VERSION "dbc-export 1 2025.20.8"

NS_ :

BS_:

BU_: BMS CC CMP CMPD CP DAS DI DIF DIR EPBL EPBR EVSE FC GTW HCML HCMR HVP ICR PCS PM PMF PMR PTC SCCM SDCR TAS UMC VC VCFRONT VCLEFT VCRIGHT VCSEC

BO_ 1012 LS_lightShow: 8 GTW
 SG_ LS_lightShowIndex M : 0|5@1+ (1,0) [0|31] "" Vector__XXX
 SG_ LS_lightLeftRampedChannel1Reques m0 : 5|1@1+ (1,0) [0|1] "" Vector__XXX
 SG_ LS_lightLeftRampedChannel1Durati m0 : 6|2@1+ (1,0) [0|3] "" Vector__XXX
 SG_ LS_lightLeftRampedChannel2Reques m0 : 8|1@1+ (1,0) [0|1] "" Vector__XXX
 SG_ LS_lightLeftRampedChannel2Durati m0 : 9|2@1+ (1,0) [0|3] "" Vector__XXX
 SG_ LS_lightLeftRampedChannel3Reques m0 : 11|1@1+ (1,0) [0|1] "" Vector__XXX
 SG_ LS_lightLeftRampedChannel3Durati m0 : 12|2@1+ (1,0) [0|3] "" Vector__XXX
 SG_ LS_lightLeftRampedChannel4Reques m0 : 14|1@1+ (1,0) [0|1] "" Vector__XXX
 SG_ LS_lightLeftRampedChannel4Durati m0 : 16|2@1+ (1,0) [0|3] "" Vector__XXX
 SG_ LS_lightLeftRampedChannel5Reques m0 : 18|1@1+ (1,0) [0|1] "" Vector__XXX
 SG_ LS_lightLeftRampedChannel5Durati m0 : 19|2@1+ (1,0) [0|3] "" Vector__XXX
 SG_ LS_lightLeftRampedChannel6Reques m0 : 21|1@1+ (1,0) [0|1] "" Vector__XXX
 SG_ LS_lightLeftRampedChannel6Durati m0 : 22|2@1+ (1,0) [0|3] "" Vector__XXX
 SG_ LS_lightLeftRampedChannel7Reques m0 : 24|1@1+ (1,0) [0|1] "" Vector__XXX
 SG_ LS_lightLeftRampedChannel7Durati m0 : 25|2@1+ (1,0) [0|3] "" Vector__XXX
 SG_ LS_lightRightRampedChannel1Reque m0 : 27|1@1+ (1,0) [0|1] "" Vector__XXX
 SG_ LS_lightRightRampedChannel1Durat m0 : 28|2@1+ (1,0) [0|3] "" Vector__XXX
 SG_ LS_lightRightRampedChannel2Reque m0 : 30|1@1+ (1,0) [0|1] "" Vector__XXX
 SG_ LS_lightRightRampedChannel2Durat m0 : 31|2@1+ (1,0) [0|3] "" Vector__XXX
 SG_ LS_lightRightRampedChannel3Reque m0 : 33|1@1+ (1,0) [0|1] "" Vector__XXX
 SG_ LS_lightRightRampedChannel3Durat m0 : 34|2@1+ (1,0) [0|3] "" Vector__XXX
 SG_ LS_lightRightRampedChannel4Reque m0 : 36|1@1+ (1,0) [0|1] "" Vector__XXX
 SG_ LS_lightRightRampedChannel4Durat m0 : 37|2@1+ (1,0) [0|3] "" Vector__XXX
 SG_ LS_lightRightRampedChannel5Reque m0 : 39|1@1+ (1,0) [0|1] "" Vector__XXX
 SG_ LS_lightRightRampedChannel5Durat m0 : 40|2@1+ (1,0) [0|3] "" Vector__XXX
 SG_ LS_lightRightRampedChannel6Reque m0 : 42|1@1+ (1,0) [0|1] "" Vector__XXX
 SG_ LS_lightRightRampedChannel6Durat m0 : 43|2@1+ (1,0) [0|3] "" Vector__XXX
 SG_ LS_lightRightRampedChannel7Reque m0 : 45|1@1+ (1,0) [0|1] "" Vector__XXX
 SG_ LS_lightRightRampedChannel7Durat m0 : 46|2@1+ (1,0) [0|3] "" Vector__XXX
 SG_ LS_lightRearTurnLeftRequest m0 : 48|1@1+ (1,0) [0|1] "" Vector__XXX
 SG_ LS_lightRearTurnRightRequest m0 : 49|1@1+ (1,0) [0|1] "" Vector__XXX
 SG_ LS_lightSideRepeaterLeftRequest m0 : 50|1@1+ (1,0) [0|1] "" Vector__XXX
 SG_ LS_lightSideRepeaterRightRequest m0 : 51|1@1+ (1,0) [0|1] "" Vector__XXX
 SG_ LS_lightSideMarkerLeftRequest m0 : 52|1@1+ (1,0) [0|1] "" Vector__XXX
 SG_ LS_lightSideMarkerRightRequest m0 : 53|1@1+ (1,0) [0|1] "" Vector__XXX
 SG_ LS_lightFrontFogLeftRequest m0 : 54|1@1+ (1,0) [0|1] "" Vector__XXX
 SG_ LS_lightFrontFogRightRequest m0 : 55|1@1+ (1,0) [0|1] "" Vector__XXX
 SG_ LS_lightRearFogRequest m0 : 56|1@1+ (1,0) [0|1] "" Vector__XXX
 SG_ LS_lightBrakeRequest m0 : 57|1@1+ (1,0) [0|1] "" Vector__XXX
 SG_ LS_lightTailLeftRequest m0 : 58|1@1+ (1,0) [0|1] "" Vector__XXX
 SG_ LS_lightTailRightRequest m0 : 59|1@1+ (1,0) [0|1] "" Vector__XXX
 SG_ LS_lightLicensePlateRequest m0 : 60|1@1+ (1,0) [0|1] "" Vector__XXX
 SG_ LS_lightReverseRequest m0 : 61|1@1+ (1,0) [0|1] "" Vector__XXX
 SG_ LS_lightAuxParkLeftRequest m0 : 62|1@1+ (1,0) [0|1] "" Vector__XXX
 SG_ LS_lightAuxParkRightRequest m0 : 63|1@1+ (1,0) [0|1] "" Vector__XXX
 SG_ LS_mirrorRequestLeft m1 : 5|3@1+ (1,0) [0|7] "" Vector__XXX
 SG_ LS_mirrorRequestRight m1 : 8|3@1+ (1,0) [0|7] "" Vector__XXX
 SG_ LS_liftgateRequest m1 : 11|3@1+ (1,0) [0|7] "" Vector__XXX
 SG_ LS_windowRequestLF m1 : 16|3@1+ (1,0) [0|7] "" Vector__XXX
 SG_ LS_windowRequestLR m1 : 19|3@1+ (1,0) [0|7] "" Vector__XXX
 SG_ LS_windowRequestRF m1 : 24|3@1+ (1,0) [0|7] "" Vector__XXX
 SG_ LS_windowRequestRR m1 : 27|3@1+ (1,0) [0|7] "" Vector__XXX
 SG_ LS_presentingHandleRequestLF m1 : 32|3@1+ (1,0) [0|7] "" Vector__XXX
 SG_ LS_presentingHandleRequestLR m1 : 35|3@1+ (1,0) [0|7] "" Vector__XXX
 SG_ LS_presentingHandleRequestRF m1 : 40|3@1+ (1,0) [0|7] "" Vector__XXX
 SG_ LS_presentingHandleRequestRR m1 : 43|3@1+ (1,0) [0|7] "" Vector__XXX
 SG_ LS_powerFrontDoorRequestLeft m1 : 46|3@1+ (1,0) [0|7] "" Vector__XXX
 SG_ LS_powerFrontDoorRequestRight m1 : 49|3@1+ (1,0) [0|7] "" Vector__XXX
 SG_ LS_falconDoorRequestLeft m1 : 52|3@1+ (1,0) [0|7] "" Vector__XXX
 SG_ LS_falconDoorRequestRight m1 : 55|3@1+ (1,0) [0|7] "" Vector__XXX
 SG_ LS_chargePortRequest m1 : 58|2@1+ (1,0) [0|2] "" Vector__XXX
 SG_ LS_chargePortRaveRequest m1 : 60|1@1+ (1,0) [0|1] "" Vector__XXX
 SG_ LS_suspensionRequest m1 : 61|2@1+ (1,0) [0|2] "" Vector__XXX
 SG_ LS_rgbIPFLRed m2 : 8|8@1+ (1,0) [0|255] "" Vector__XXX
 SG_ LS_rgbIPFLGreen m2 : 16|8@1+ (1,0) [0|255] "" Vector__XXX
 SG_ LS_rgbIPFLBlue m2 : 24|8@1+ (1,0) [0|255] "" Vector__XXX
 SG_ LS_rgbIPFRRed m2 : 32|8@1+ (1,0) [0|255] "" Vector__XXX
 SG_ LS_rgbIPFRGreen m2 : 40|8@1+ (1,0) [0|255] "" Vector__XXX
 SG_ LS_rgbIPFRBlue m2 : 48|8@1+ (1,0) [0|255] "" Vector__XXX
 SG_ LS_rgbDoorFLForeRed m3 : 8|8@1+ (1,0) [0|255] "" Vector__XXX
 SG_ LS_rgbDoorFLForeGreen m3 : 16|8@1+ (1,0) [0|255] "" Vector__XXX
 SG_ LS_rgbDoorFLForeBlue m3 : 24|8@1+ (1,0) [0|255] "" Vector__XXX
 SG_ LS_rgbDoorFLAftRed m3 : 32|8@1+ (1,0) [0|255] "" Vector__XXX
 SG_ LS_rgbDoorFLAftGreen m3 : 40|8@1+ (1,0) [0|255] "" Vector__XXX
 SG_ LS_rgbDoorFLAftBlue m3 : 48|8@1+ (1,0) [0|255] "" Vector__XXX
 SG_ LS_rgbDoorFRForeRed m4 : 8|8@1+ (1,0) [0|255] "" Vector__XXX
 SG_ LS_rgbDoorFRForeGreen m4 : 16|8@1+ (1,0) [0|255] "" Vector__XXX
 SG_ LS_rgbDoorFRForeBlue m4 : 24|8@1+ (1,0) [0|255] "" Vector__XXX
 SG_ LS_rgbDoorFRAftRed m4 : 32|8@1+ (1,0) [0|255] "" Vector__XXX
 SG_ LS_rgbDoorFRAftGreen m4 : 40|8@1+ (1,0) [0|255] "" Vector__XXX
 SG_ LS_rgbDoorFRAftBlue m4 : 48|8@1+ (1,0) [0|255] "" Vector__XXX
 SG_ LS_rgbDoorRLForeRed m5 : 8|8@1+ (1,0) [0|255] "" Vector__XXX
 SG_ LS_rgbDoorRLForeGreen m5 : 16|8@1+ (1,0) [0|255] "" Vector__XXX
 SG_ LS_rgbDoorRLForeBlue m5 : 24|8@1+ (1,0) [0|255] "" Vector__XXX
 SG_ LS_rgbDoorRLAftRed m5 : 32|8@1+ (1,0) [0|255] "" Vector__XXX
 SG_ LS_rgbDoorRLAftGreen m5 : 40|8@1+ (1,0) [0|255] "" Vector__XXX
 SG_ LS_rgbDoorRLAftBlue m5 : 48|8@1+ (1,0) [0|255] "" Vector__XXX
 SG_ LS_rgbDoorRRForeRed m6 : 8|8@1+ (1,0) [0|255] "" Vector__XXX
 SG_ LS_rgbDoorRRForeGreen m6 : 16|8@1+ (1,0) [0|255] "" Vector__XXX
 SG_ LS_rgbDoorRRForeBlue m6 : 24|8@1+ (1,0) [0|255] "" Vector__XXX
 SG_ LS_rgbDoorRRAftRed m6 : 32|8@1+ (1,0) [0|255] "" Vector__XXX
 SG_ LS_rgbDoorRRAftGreen m6 : 40|8@1+ (1,0) [0|255] "" Vector__XXX
 SG_ LS_rgbDoorRRAftBlue m6 : 48|8@1+ (1,0) [0|255] "" Vector__XXX
 SG_ LS_frontMatrix0 m7 : 8|8@1+ (1,0) [0|255] "" Vector__XXX
 SG_ LS_frontMatrix1 m7 : 16|8@1+ (1,0) [0|255] "" Vector__XXX
 SG_ LS_frontMatrix2 m7 : 24|8@1+ (1,0) [0|255] "" Vector__XXX
 SG_ LS_frontMatrix3 m7 : 32|8@1+ (1,0) [0|255] "" Vector__XXX
 SG_ LS_frontMatrix4 m7 : 40|8@1+ (1,0) [0|255] "" Vector__XXX
 SG_ LS_frontMatrix5 m7 : 48|8@1+ (1,0) [0|255] "" Vector__XXX
 SG_ LS_frontMatrix6 m7 : 56|8@1+ (1,0) [0|255] "" Vector__XXX
 SG_ LS_frontMatrix7 m8 : 8|8@1+ (1,0) [0|255] "" Vector__XXX
 SG_ LS_frontMatrix8 m8 : 16|8@1+ (1,0) [0|255] "" Vector__XXX
 SG_ LS_frontMatrix9 m8 : 24|8@1+ (1,0) [0|255] "" Vector__XXX
 SG_ LS_frontMatrix10 m8 : 32|8@1+ (1,0) [0|255] "" Vector__XXX
 SG_ LS_frontMatrix11 m8 : 40|8@1+ (1,0) [0|255] "" Vector__XXX
 SG_ LS_frontMatrix12 m8 : 48|8@1+ (1,0) [0|255] "" Vector__XXX
 SG_ LS_frontMatrix13 m8 : 56|8@1+ (1,0) [0|255] "" Vector__XXX
 SG_ LS_frontMatrix14 m9 : 8|8@1+ (1,0) [0|255] "" Vector__XXX
 SG_ LS_frontMatrix15 m9 : 16|8@1+ (1,0) [0|255] "" Vector__XXX
 SG_ LS_frontMatrix16 m9 : 24|8@1+ (1,0) [0|255] "" Vector__XXX
 SG_ LS_frontMatrix17 m9 : 32|8@1+ (1,0) [0|255] "" Vector__XXX
 SG_ LS_frontMatrix18 m9 : 40|8@1+ (1,0) [0|255] "" Vector__XXX
 SG_ LS_frontMatrix19 m9 : 48|8@1+ (1,0) [0|255] "" Vector__XXX
 SG_ LS_frontMatrix20 m9 : 56|8@1+ (1,0) [0|255] "" Vector__XXX
 SG_ LS_frontMatrix21 m10 : 8|8@1+ (1,0) [0|255] "" Vector__XXX
 SG_ LS_frontMatrix22 m10 : 16|8@1+ (1,0) [0|255] "" Vector__XXX
 SG_ LS_frontMatrix23 m10 : 24|8@1+ (1,0) [0|255] "" Vector__XXX
 SG_ LS_frontMatrix24 m10 : 32|8@1+ (1,0) [0|255] "" Vector__XXX
 SG_ LS_frontMatrix25 m10 : 40|8@1+ (1,0) [0|255] "" Vector__XXX
 SG_ LS_frontMatrix26 m10 : 48|8@1+ (1,0) [0|255] "" Vector__XXX
 SG_ LS_frontMatrix27 m10 : 56|8@1+ (1,0) [0|255] "" Vector__XXX
 SG_ LS_frontMatrix28 m11 : 8|8@1+ (1,0) [0|255] "" Vector__XXX
 SG_ LS_frontMatrix29 m11 : 16|8@1+ (1,0) [0|255] "" Vector__XXX
 SG_ LS_frontMatrix30 m11 : 24|8@1+ (1,0) [0|255] "" Vector__XXX
 SG_ LS_frontMatrix31 m11 : 32|8@1+ (1,0) [0|255] "" Vector__XXX
 SG_ LS_frontMatrix32 m11 : 40|8@1+ (1,0) [0|255] "" Vector__XXX
 SG_ LS_frontMatrix33 m11 : 48|8@1+ (1,0) [0|255] "" Vector__XXX
 SG_ LS_frontMatrix34 m11 : 56|8@1+ (1,0) [0|255] "" Vector__XXX
 SG_ LS_frontMatrix35 m12 : 8|8@1+ (1,0) [0|255] "" Vector__XXX
 SG_ LS_frontMatrix36 m12 : 16|8@1+ (1,0) [0|255] "" Vector__XXX
 SG_ LS_frontMatrix37 m12 : 24|8@1+ (1,0) [0|255] "" Vector__XXX
 SG_ LS_frontMatrix38 m12 : 32|8@1+ (1,0) [0|255] "" Vector__XXX
 SG_ LS_frontMatrix39 m12 : 40|8@1+ (1,0) [0|255] "" Vector__XXX
 SG_ LS_frontMatrix40 m12 : 48|8@1+ (1,0) [0|255] "" Vector__XXX
 SG_ LS_frontMatrix41 m12 : 56|8@1+ (1,0) [0|255] "" Vector__XXX
 SG_ LS_frontMatrix42 m13 : 8|8@1+ (1,0) [0|255] "" Vector__XXX
 SG_ LS_frontMatrix43 m13 : 16|8@1+ (1,0) [0|255] "" Vector__XXX
 SG_ LS_frontMatrix44 m13 : 24|8@1+ (1,0) [0|255] "" Vector__XXX
 SG_ LS_frontMatrix45 m13 : 32|8@1+ (1,0) [0|255] "" Vector__XXX
 SG_ LS_frontMatrix46 m13 : 40|8@1+ (1,0) [0|255] "" Vector__XXX
 SG_ LS_frontMatrix47 m13 : 48|8@1+ (1,0) [0|255] "" Vector__XXX
 SG_ LS_frontMatrix48 m13 : 56|8@1+ (1,0) [0|255] "" Vector__XXX
 SG_ LS_frontMatrix49 m14 : 8|8@1+ (1,0) [0|255] "" Vector__XXX
 SG_ LS_frontMatrix50 m14 : 16|8@1+ (1,0) [0|255] "" Vector__XXX
 SG_ LS_frontMatrix51 m14 : 24|8@1+ (1,0) [0|255] "" Vector__XXX
 SG_ LS_frontMatrix52 m14 : 32|8@1+ (1,0) [0|255] "" Vector__XXX
 SG_ LS_frontMatrix53 m14 : 40|8@1+ (1,0) [0|255] "" Vector__XXX
 SG_ LS_frontMatrix54 m14 : 48|8@1+ (1,0) [0|255] "" Vector__XXX
 SG_ LS_frontMatrix55 m14 : 56|8@1+ (1,0) [0|255] "" Vector__XXX
 SG_ LS_frontMatrix56 m15 : 8|8@1+ (1,0) [0|255] "" Vector__XXX
 SG_ LS_frontMatrix57 m15 : 16|8@1+ (1,0) [0|255] "" Vector__XXX
 SG_ LS_frontMatrix58 m15 : 24|8@1+ (1,0) [0|255] "" Vector__XXX
 SG_ LS_frontMatrix59 m15 : 32|8@1+ (1,0) [0|255] "" Vector__XXX
 SG_ LS_rearMatrix0 m15 : 40|8@1+ (1,0) [0|255] "" Vector__XXX
 SG_ LS_rearMatrix1 m15 : 48|8@1+ (1,0) [0|255] "" Vector__XXX
 SG_ LS_rearMatrix2 m15 : 56|8@1+ (1,0) [0|255] "" Vector__XXX
 SG_ LS_rearMatrix3 m16 : 8|8@1+ (1,0) [0|255] "" Vector__XXX
 SG_ LS_rearMatrix4 m16 : 16|8@1+ (1,0) [0|255] "" Vector__XXX
 SG_ LS_rearMatrix5 m16 : 24|8@1+ (1,0) [0|255] "" Vector__XXX
 SG_ LS_rearMatrix6 m16 : 32|8@1+ (1,0) [0|255] "" Vector__XXX
 SG_ LS_rearMatrix7 m16 : 40|8@1+ (1,0) [0|255] "" Vector__XXX
 SG_ LS_rearMatrix8 m16 : 48|8@1+ (1,0) [0|255] "" Vector__XXX
 SG_ LS_rearMatrix9 m16 : 56|8@1+ (1,0) [0|255] "" Vector__XXX
 SG_ LS_rearMatrix10 m17 : 8|8@1+ (1,0) [0|255] "" Vector__XXX
 SG_ LS_rearMatrix11 m17 : 16|8@1+ (1,0) [0|255] "" Vector__XXX
 SG_ LS_rearMatrix12 m17 : 24|8@1+ (1,0) [0|255] "" Vector__XXX
 SG_ LS_rearMatrix13 m17 : 32|8@1+ (1,0) [0|255] "" Vector__XXX
 SG_ LS_rearMatrix14 m17 : 40|8@1+ (1,0) [0|255] "" Vector__XXX
 SG_ LS_rearMatrix15 m17 : 48|8@1+ (1,0) [0|255] "" Vector__XXX
 SG_ LS_rearMatrix16 m17 : 56|8@1+ (1,0) [0|255] "" Vector__XXX
 SG_ LS_rearMatrix17 m18 : 8|8@1+ (1,0) [0|255] "" Vector__XXX
 SG_ LS_rearMatrix18 m18 : 16|8@1+ (1,0) [0|255] "" Vector__XXX
 SG_ LS_rearMatrix19 m18 : 24|8@1+ (1,0) [0|255] "" Vector__XXX
 SG_ LS_rearMatrix20 m18 : 32|8@1+ (1,0) [0|255] "" Vector__XXX
 SG_ LS_rearMatrix21 m18 : 40|8@1+ (1,0) [0|255] "" Vector__XXX
 SG_ LS_rearMatrix22 m18 : 48|8@1+ (1,0) [0|255] "" Vector__XXX
 SG_ LS_rearMatrix23 m18 : 56|8@1+ (1,0) [0|255] "" Vector__XXX
 SG_ LS_rearMatrix24 m19 : 8|8@1+ (1,0) [0|255] "" Vector__XXX
 SG_ LS_rearMatrix25 m19 : 16|8@1+ (1,0) [0|255] "" Vector__XXX
 SG_ LS_rearMatrix26 m19 : 24|8@1+ (1,0) [0|255] "" Vector__XXX
 SG_ LS_rearMatrix27 m19 : 32|8@1+ (1,0) [0|255] "" Vector__XXX
 SG_ LS_rearMatrix28 m19 : 40|8@1+ (1,0) [0|255] "" Vector__XXX
 SG_ LS_rearMatrix29 m19 : 48|8@1+ (1,0) [0|255] "" Vector__XXX
 SG_ LS_rearMatrix30 m19 : 56|8@1+ (1,0) [0|255] "" Vector__XXX
 SG_ LS_rearMatrix31 m20 : 8|8@1+ (1,0) [0|255] "" Vector__XXX
 SG_ LS_rearMatrix32 m20 : 16|8@1+ (1,0) [0|255] "" Vector__XXX
 SG_ LS_rearMatrix33 m20 : 24|8@1+ (1,0) [0|255] "" Vector__XXX
 SG_ LS_rearMatrix34 m20 : 32|8@1+ (1,0) [0|255] "" Vector__XXX
 SG_ LS_rearMatrix35 m20 : 40|8@1+ (1,0) [0|255] "" Vector__XXX
 SG_ LS_rearMatrix36 m20 : 48|8@1+ (1,0) [0|255] "" Vector__XXX
 SG_ LS_rearMatrix37 m20 : 56|8@1+ (1,0) [0|255] "" Vector__XXX
 SG_ LS_rearMatrix38 m21 : 8|8@1+ (1,0) [0|255] "" Vector__XXX
 SG_ LS_rearMatrix39 m21 : 16|8@1+ (1,0) [0|255] "" Vector__XXX
 SG_ LS_rearMatrix40 m21 : 24|8@1+ (1,0) [0|255] "" Vector__XXX
 SG_ LS_rearMatrix41 m21 : 32|8@1+ (1,0) [0|255] "" Vector__XXX
 SG_ LS_rearMatrix42 m21 : 40|8@1+ (1,0) [0|255] "" Vector__XXX
 SG_ LS_rearMatrix43 m21 : 48|8@1+ (1,0) [0|255] "" Vector__XXX
 SG_ LS_rearMatrix44 m21 : 56|8@1+ (1,0) [0|255] "" Vector__XXX
 SG_ LS_rearMatrix45 m22 : 8|8@1+ (1,0) [0|255] "" Vector__XXX
 SG_ LS_rearMatrix46 m22 : 16|8@1+ (1,0) [0|255] "" Vector__XXX
 SG_ LS_rearMatrix47 m22 : 24|8@1+ (1,0) [0|255] "" Vector__XXX
 SG_ LS_rearMatrix48 m22 : 32|8@1+ (1,0) [0|255] "" Vector__XXX
 SG_ LS_rearMatrix49 m22 : 40|8@1+ (1,0) [0|255] "" Vector__XXX
 SG_ LS_rearMatrix50 m22 : 48|8@1+ (1,0) [0|255] "" Vector__XXX
 SG_ LS_rearMatrix51 m22 : 56|8@1+ (1,0) [0|255] "" Vector__XXX
 SG_ LS_rearMatrix52 m23 : 8|8@1+ (1,0) [0|255] "" Vector__XXX
 SG_ LS_rearMatrix53 m23 : 16|8@1+ (1,0) [0|255] "" Vector__XXX
 SG_ LS_rearMatrix54 m23 : 24|8@1+ (1,0) [0|255] "" Vector__XXX
 SG_ LS_rearMatrix55 m23 : 32|8@1+ (1,0) [0|255] "" Vector__XXX
 SG_ LS_rearMatrix56 m23 : 40|8@1+ (1,0) [0|255] "" Vector__XXX
 SG_ LS_rearMatrix57 m23 : 48|8@1+ (1,0) [0|255] "" Vector__XXX
 SG_ LS_rearMatrix58 m23 : 56|8@1+ (1,0) [0|255] "" Vector__XXX
 SG_ LS_rearMatrix59 m24 : 8|8@1+ (1,0) [0|255] "" Vector__XXX
 SG_ LS_offroadLightBar0 m24 : 16|8@1+ (1,0) [0|255] "" Vector__XXX
 SG_ LS_offroadLightBar1 m24 : 24|8@1+ (1,0) [0|255] "" Vector__XXX
 SG_ LS_offroadLightBar2 m24 : 32|8@1+ (1,0) [0|255] "" Vector__XXX
 SG_ LS_offroadLightBar3 m24 : 40|8@1+ (1,0) [0|255] "" Vector__XXX
 SG_ LS_offroadLightBar4 m24 : 48|8@1+ (1,0) [0|255] "" Vector__XXX
 SG_ LS_offroadLightBar5 m24 : 56|8@1+ (1,0) [0|255] "" Vector__XXX

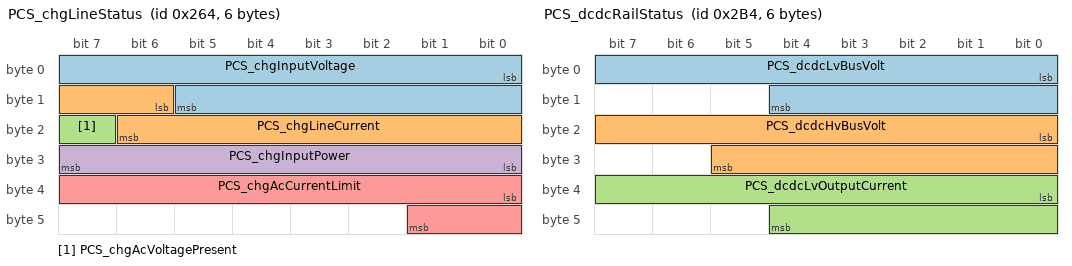
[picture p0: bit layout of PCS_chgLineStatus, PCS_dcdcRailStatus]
BO_ 612 PCS_chgLineStatus: 6 PCS
 SG_ PCS_chgInputVoltage : 0|14@1+ (0.033,0) [0|540.639] "V" Vector__XXX
 SG_ PCS_chgLineCurrent : 14|9@1+ (0.1,0) [0|50] "A" Vector__XXX
 SG_ PCS_chgAcVoltagePresent : 23|1@1+ (1,0) [0|1] "" Vector__XXX
 SG_ PCS_chgInputPower : 24|8@1+ (0.1,0) [0|20] "kW" Vector__XXX
 SG_ PCS_chgAcCurrentLimit : 32|10@1+ (0.1,0) [0|102.3] "A" Vector__XXX

BO_ 692 PCS_dcdcRailStatus: 6 PCS
 SG_ PCS_dcdcLvBusVolt : 0|13@1+ (0.01,0) [0|80] "V" Vector__XXX
 SG_ PCS_dcdcHvBusVolt : 16|14@1+ (0.1,0) [0|1600] "V" Vector__XXX
 SG_ PCS_dcdcLvOutputCurrent : 32|13@1- (0.1,0) [-400|400] "A" Vector__XXX

BO_ 964 PCS_info: 8 PCS
 SG_ PCS_infoIndex M : 0|8@1+ (1,0) [0|255] "" Vector__XXX
 SG_ PCS_buildType m10 : 8|8@1+ (1,0) [0|255] "" Vector__XXX
 SG_ PCS_buildConfigId m10 : 16|16@1+ (1,0) [0|65535] "" Vector__XXX
 SG_ PCS_hardwareId m10 : 32|16@1+ (1,0) [0|65535] "" Vector__XXX
 SG_ PCS_componentId m10 : 48|16@1+ (1,0) [0|65535] "" Vector__XXX
 SG_ PCS_pcbaId m11 : 16|8@1+ (1,0) [0|255] "" Vector__XXX
 SG_ PCS_assemblyId m11 : 24|8@1+ (1,0) [0|255] "" Vector__XXX
 SG_ PCS_usageId m11 : 32|16@1+ (1,0) [0|65535] "" Vector__XXX
 SG_ PCS_subUsageId m11 : 48|16@1+ (1,0) [0|65535] "" Vector__XXX
 SG_ PCS_platformType m13 : 8|8@1+ (1,0) [0|255] "" Vector__XXX
 SG_ PCS_appCrc m13 : 32|32@1+ (1,0) [0|4294967295] "" Vector__XXX
 SG_ PCS_cpu2AppCrc m16 : 32|32@1+ (1,0) [0|4294967295] "" Vector__XXX
 SG_ PCS_appGitHash m17 : 8|56@1+ (1,0) [0|7.20575940379e+16] "" Vector__XXX
 SG_ PCS_bootGitHash m18 : 8|56@1+ (1,0) [0|7.20575940379e+16] "" Vector__XXX
 SG_ PCS_bootUdsProtoVersion m20 : 8|8@1+ (1,0) [0|255] "" Vector__XXX
 SG_ PCS_bootCrc m20 : 32|32@1+ (1,0) [0|4294967295] "" Vector__XXX

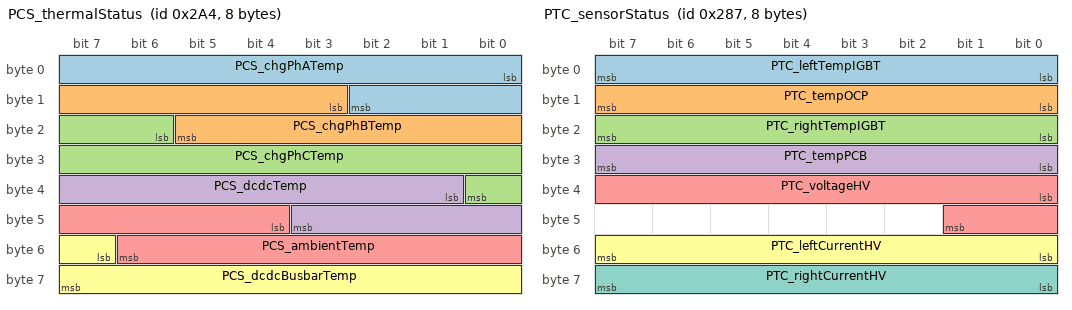
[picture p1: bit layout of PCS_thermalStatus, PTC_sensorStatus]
BO_ 676 PCS_thermalStatus: 8 PCS
 SG_ PCS_chgPhATemp : 0|11@1- (0.1,40) [-62.4|142.3] "C" Vector__XXX
 SG_ PCS_chgPhBTemp : 11|11@1- (0.1,40) [-62.4|142.3] "C" Vector__XXX
 SG_ PCS_chgPhCTemp : 22|11@1- (0.1,40) [-62.4|142.3] "C" Vector__XXX
 SG_ PCS_dcdcTemp : 33|11@1- (0.1,40) [-62.4|142.3] "C" Vector__XXX
 SG_ PCS_ambientTemp : 44|11@1- (0.1,40) [-62.4|142.3] "C" Vector__XXX
 SG_ PCS_dcdcBusbarTemp : 55|9@1+ (0.2935421,0) [0|149.706471] "C" Vector__XXX

BO_ 790 PMF_info: 8 PMF
 SG_ PMF_infoIndex M : 0|8@1+ (1,0) [0|255] "" Vector__XXX
 SG_ PMF_buildType m10 : 8|8@1+ (1,0) [0|255] "" Vector__XXX
 SG_ PMF_buildConfigurationId m10 : 16|16@1+ (1,0) [0|65535] "" Vector__XXX
 SG_ PMF_hardwareId m10 : 32|8@1+ (1,0) [0|252] "" Vector__XXX
 SG_ PMF_deviceFused m10 : 40|1@1+ (1,0) [0|1] "" Vector__XXX
 SG_ PMF_componentId m10 : 48|16@1+ (1,0) [0|65535] "" Vector__XXX
 SG_ PMF_pcbaId m11 : 16|8@1+ (1,0) [0|255] "" Vector__XXX
 SG_ PMF_assemblyId m11 : 24|8@1+ (1,0) [0|255] "" Vector__XXX
 SG_ PMF_usageId m11 : 32|16@1+ (1,0) [0|65535] "" Vector__XXX
 SG_ PMF_subUsageId m11 : 48|16@1+ (1,0) [0|65535] "" Vector__XXX
 SG_ PMF_applicationCrc m13 : 32|32@1+ (1,0) [0|4294967295] "" Vector__XXX
 SG_ PMF_appGitHash m17 : 8|56@1+ (1,0) [0|7.20575940379e+16] "" Vector__XXX
 SG_ PMF_bootGitHash m18 : 8|56@1+ (1,0) [0|7.20575940379e+16] "" Vector__XXX
 SG_ PMF_platformTyp m19 : 8|8@1+ (1,0) [0|255] "" Vector__XXX
 SG_ PMF_udsProtocolVersion m20 : 8|8@1+ (1,0) [0|255] "" Vector__XXX
 SG_ PMF_bootloaderCrc m20 : 32|32@1+ (1,0) [0|4294967295] "" Vector__XXX

BO_ 1748 PMR_info: 8 PMR
 SG_ PMR_infoIndex M : 0|8@1+ (1,0) [0|255] "" Vector__XXX
 SG_ PMR_buildType m10 : 8|8@1+ (1,0) [0|255] "" Vector__XXX
 SG_ PMR_buildConfigurationId m10 : 16|16@1+ (1,0) [0|65535] "" Vector__XXX
 SG_ PMR_hardwareId m10 : 32|8@1+ (1,0) [0|252] "" Vector__XXX
 SG_ PMR_deviceFused m10 : 40|1@1+ (1,0) [0|1] "" Vector__XXX
 SG_ PMR_componentId m10 : 48|16@1+ (1,0) [0|65535] "" Vector__XXX
 SG_ PMR_pcbaId m11 : 16|8@1+ (1,0) [0|255] "" Vector__XXX
 SG_ PMR_assemblyId m11 : 24|8@1+ (1,0) [0|255] "" Vector__XXX
 SG_ PMR_usageId m11 : 32|16@1+ (1,0) [0|65535] "" Vector__XXX
 SG_ PMR_subUsageId m11 : 48|16@1+ (1,0) [0|65535] "" Vector__XXX
 SG_ PMR_applicationCrc m13 : 32|32@1+ (1,0) [0|4294967295] "" Vector__XXX
 SG_ PMR_appGitHash m17 : 8|56@1+ (1,0) [0|7.20575940379e+16] "" Vector__XXX
 SG_ PMR_bootGitHash m18 : 8|56@1+ (1,0) [0|7.20575940379e+16] "" Vector__XXX
 SG_ PMR_platformTyp m19 : 8|8@1+ (1,0) [0|255] "" Vector__XXX
 SG_ PMR_udsProtocolVersion m20 : 8|8@1+ (1,0) [0|255] "" Vector__XXX
 SG_ PMR_bootloaderCrc m20 : 32|32@1+ (1,0) [0|4294967295] "" Vector__XXX

BO_ 1551 PM_info: 8 PM
 SG_ PM_infoIndex M : 0|8@1+ (1,0) [0|255] "" Vector__XXX
 SG_ PM_buildType m10 : 8|8@1+ (1,0) [0|255] "" Vector__XXX
 SG_ PM_buildConfigurationId m10 : 16|16@1+ (1,0) [0|65535] "" Vector__XXX
 SG_ PM_hardwareId m10 : 32|8@1+ (1,0) [0|252] "" Vector__XXX
 SG_ PM_deviceFused m10 : 40|1@1+ (1,0) [0|1] "" Vector__XXX
 SG_ PM_componentId m10 : 48|16@1+ (1,0) [0|65535] "" Vector__XXX
 SG_ PM_pcbaId m11 : 16|8@1+ (1,0) [0|255] "" Vector__XXX
 SG_ PM_assemblyId m11 : 24|8@1+ (1,0) [0|255] "" Vector__XXX
 SG_ PM_usageId m11 : 32|16@1+ (1,0) [0|65535] "" Vector__XXX
 SG_ PM_subUsageId m11 : 48|16@1+ (1,0) [0|65535] "" Vector__XXX
 SG_ PM_applicationCrc m13 : 32|32@1+ (1,0) [0|4294967295] "" Vector__XXX
 SG_ PM_bootGitHash m18 : 8|56@1+ (1,0) [0|7.20575940379e+16] "" Vector__XXX

BO_ 837 PTC_info: 8 PTC
 SG_ PTC_infoIndex M : 0|8@1+ (1,0) [0|255] "" Vector__XXX
 SG_ PTC_infoBuildType m10 : 8|3@1+ (1,0) [0|7] "" Vector__XXX
 SG_ PTC_infoBuildConfigId m10 : 16|16@1+ (1,0) [0|65535] "" Vector__XXX
 SG_ PTC_infoHardwareId m10 : 32|16@1+ (1,0) [0|65535] "" Vector__XXX
 SG_ PTC_infoComponentId m10 : 48|16@1+ (1,0) [0|65535] "" Vector__XXX
 SG_ PTC_infoPcbaId m11 : 16|8@1+ (1,0) [0|255] "" Vector__XXX
 SG_ PTC_infoAssemblyId m11 : 24|8@1+ (1,0) [0|254] "" Vector__XXX
 SG_ PTC_infoUsageId m11 : 32|16@1+ (1,0) [0|65535] "" Vector__XXX
 SG_ PTC_infoSubUsageId m11 : 48|16@1+ (1,0) [0|65535] "" Vector__XXX
 SG_ PTC_infoPlatformType m13 : 8|8@1+ (1,0) [0|255] "" Vector__XXX
 SG_ PTC_infoAppCrc m13 : 32|32@1+ (1,0) [0|4294967295] "" Vector__XXX
 SG_ PTC_infoBootUdsProtoVersion m20 : 8|8@1+ (1,0) [0|255] "" Vector__XXX
 SG_ PTC_infoBootCrc m20 : 32|32@1+ (1,0) [0|4294967295] "" Vector__XXX

BO_ 647 PTC_sensorStatus: 8 PTC
 SG_ PTC_leftTempIGBT : 0|8@1+ (1,-40) [-40|200] "degC" Vector__XXX
 SG_ PTC_tempOCP : 8|8@1+ (1,-40) [-40|200] "degC" Vector__XXX
 SG_ PTC_rightTempIGBT : 16|8@1+ (1,-40) [-40|200] "degC" Vector__XXX
 SG_ PTC_tempPCB : 24|8@1+ (1,-40) [-40|200] "degC" Vector__XXX
 SG_ PTC_voltageHV : 32|10@1+ (0.5,0) [0|511.5] "V" Vector__XXX
 SG_ PTC_leftCurrentHV : 48|8@1+ (0.2,0) [0|50] "A" Vector__XXX
 SG_ PTC_rightCurrentHV : 56|8@1+ (0.2,0) [0|50] "A" Vector__XXX

BO_ 816 SCCM_info: 8 SCCM
 SG_ SCCM_infoIndex M : 0|8@1+ (1,0) [0|255] "" Vector__XXX
 SG_ SCCM_infoBuildType m10 : 8|8@1+ (1,0) [0|255] "" Vector__XXX
 SG_ SCCM_infoBuildConfigId m10 : 16|16@1+ (1,0) [0|65535] "" Vector__XXX
 SG_ SCCM_infoHardwareId m10 : 32|16@1+ (1,0) [0|65535] "" Vector__XXX
 SG_ SCCM_infoComponentId m10 : 48|16@1+ (1,0) [0|65535] "" Vector__XXX
 SG_ SCCM_infoPcbaId m11 : 16|8@1+ (1,0) [0|255] "" Vector__XXX
 SG_ SCCM_infoAssemblyId m11 : 24|8@1+ (1,0) [0|255] "" Vector__XXX
 SG_ SCCM_infoUsageId m11 : 32|16@1+ (1,0) [0|65535] "" Vector__XXX
 SG_ SCCM_infoSubUsageId m11 : 48|16@1+ (1,0) [0|65535] "" Vector__XXX
 SG_ SCCM_infoPlatformType m13 : 8|8@1+ (1,0) [0|255] "" Vector__XXX
 SG_ SCCM_infoAppCrc m13 : 39|32@0+ (1,0) [0|4294967295] "" Vector__XXX
 SG_ SCCM_infoBootSvnRev m14 : 8|24@1+ (1,0) [0|16777215] "" Vector__XXX
 SG_ SCCM_infoBootSvnUrlHash m14 : 32|32@1+ (1,0) [0|4294967295] "" Vector__XXX
 SG_ SCCM_infoSubcomponent1Version m16 : 16|32@1+ (1,0) [0|4294967295] "" Vector__XXX
 SG_ SCCM_infoAppSvnHash m17 : 8|56@1+ (1,0) [0|7.20575940379e+16] "" Vector__XXX
 SG_ SCCM_infoBootSvnHash m18 : 8|56@1+ (1,0) [0|7.20575940379e+16] "" Vector__XXX
 SG_ SCCM_infoUdsProtoVersion m20 : 8|8@1+ (1,0) [0|255] "" Vector__XXX
 SG_ SCCM_infoBootCrc m20 : 32|32@1+ (1,0) [0|4294967295] "" Vector__XXX

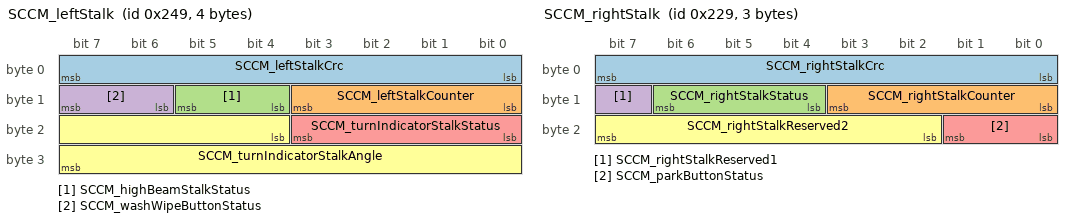
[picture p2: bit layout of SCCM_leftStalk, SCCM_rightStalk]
BO_ 585 SCCM_leftStalk: 4 SCCM
 SG_ SCCM_leftStalkCrc : 0|8@1+ (1,0) [0|255] "" Vector__XXX
 SG_ SCCM_leftStalkCounter : 8|4@1+ (1,0) [0|15] "" Vector__XXX
 SG_ SCCM_highBeamStalkStatus : 12|2@1+ (1,0) [0|2] "" Vector__XXX
 SG_ SCCM_washWipeButtonStatus : 14|2@1+ (1,0) [0|2] "" Vector__XXX
 SG_ SCCM_turnIndicatorStalkStatus : 16|4@1+ (1,0) [0|15] "" Vector__XXX
 SG_ SCCM_turnIndicatorStalkAngle : 20|12@1+ (0.1,-180) [-180|180] "deg" Vector__XXX

BO_ 553 SCCM_rightStalk: 3 SCCM
 SG_ SCCM_rightStalkCrc : 0|8@1+ (1,0) [0|255] "" Vector__XXX
 SG_ SCCM_rightStalkCounter : 8|4@1+ (1,0) [0|15] "" Vector__XXX
 SG_ SCCM_rightStalkStatus : 12|3@1+ (1,0) [0|7] "" Vector__XXX
 SG_ SCCM_rightStalkReserved1 : 15|1@1+ (1,0) [0|1] "" Vector__XXX
 SG_ SCCM_parkButtonStatus : 16|2@1+ (1,0) [0|2] "" Vector__XXX
 SG_ SCCM_rightStalkReserved2 : 18|6@1+ (1,0) [0|63] "" Vector__XXX

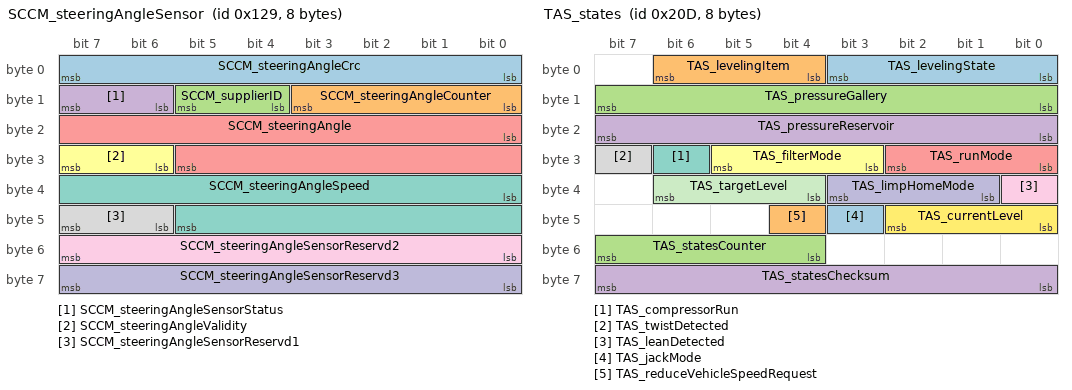
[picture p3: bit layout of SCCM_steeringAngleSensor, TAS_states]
BO_ 297 SCCM_steeringAngleSensor: 8 SCCM
 SG_ SCCM_steeringAngleCrc : 0|8@1+ (1,0) [0|255] "" Vector__XXX
 SG_ SCCM_steeringAngleCounter : 8|4@1+ (1,0) [0|15] "" Vector__XXX
 SG_ SCCM_supplierID : 12|2@1+ (1,0) [0|3] "" Vector__XXX
 SG_ SCCM_steeringAngleSensorStatus : 14|2@1+ (1,0) [0|3] "" Vector__XXX
 SG_ SCCM_steeringAngle : 16|14@1+ (0.1,-819.2) [-819.2|819] "deg" Vector__XXX
 SG_ SCCM_steeringAngleValidity : 30|2@1+ (1,0) [0|2] "" Vector__XXX
 SG_ SCCM_steeringAngleSpeed : 32|14@1+ (0.5,-4096) [-4096|4095.5] "deg/s" Vector__XXX
 SG_ SCCM_steeringAngleSensorReservd1 : 46|2@1+ (1,0) [0|3] "" Vector__XXX
 SG_ SCCM_steeringAngleSensorReservd2 : 48|8@1+ (1,0) [0|255] "" Vector__XXX
 SG_ SCCM_steeringAngleSensorReservd3 : 56|8@1+ (1,0) [0|255] "" Vector__XXX

BO_ 1597 SDCR_info: 8 SDCR
 SG_ SDCR_infoIndex M : 0|8@1+ (1,0) [0|255] "" Vector__XXX
 SG_ SDCR_infoBuildType m10 : 13|3@1+ (1,0) [0|7] "" Vector__XXX
 SG_ SDCR_infoBuildConfigId m10 : 16|16@1+ (1,0) [0|65535] "" Vector__XXX
 SG_ SDCR_infoHardwareId m10 : 32|16@1+ (1,0) [0|65535] "" Vector__XXX
 SG_ SDCR_infoComponentId m10 : 55|16@0+ (1,0) [0|65535] "" Vector__XXX
 SG_ SDCR_infoPcbaId m11 : 8|8@1+ (1,0) [0|255] "" Vector__XXX
 SG_ SDCR_infoAssemblyId m11 : 16|8@1+ (1,0) [0|255] "" Vector__XXX
 SG_ SDCR_infoUsageId m11 : 31|16@0+ (1,0) [0|65535] "" Vector__XXX
 SG_ SDCR_infoSubUsageId m11 : 40|16@1+ (1,0) [0|65535] "" Vector__XXX
 SG_ SDCR_infoAppCrc m13 : 15|32@0+ (1,0) [0|4294967295] "" Vector__XXX
 SG_ SDCR_infoBootGitHash m18 : 8|56@1+ (1,0) [0|7.20575940379e+16] "" Vector__XXX

BO_ 523 TAS_axleData: 8 TAS
 SG_ TAS_axleIndex M : 0|1@1+ (1,0) [0|1] "" Vector__XXX
 SG_ TAS_rawHeightFL m0 : 4|10@1+ (1,-512) [-512|510] "mm" Vector__XXX
 SG_ TAS_staticHeightEstimateFL m0 : 14|10@1+ (1,-512) [-512|510] "mm" Vector__XXX
 SG_ TAS_componentPressureFL m0 : 24|8@1+ (0.1,0) [0|25.4] "bara" Vector__XXX
 SG_ TAS_rawHeightFR m0 : 32|10@1+ (1,-512) [-512|510] "mm" Vector__XXX
 SG_ TAS_staticHeightEstimateFR m0 : 42|10@1+ (1,-512) [-512|510] "mm" Vector__XXX
 SG_ TAS_componentPressureFR m0 : 52|8@1+ (0.1,0) [0|25.4] "bara" Vector__XXX
 SG_ TAS_rawHeightRL m1 : 4|10@1+ (1,-512) [-512|510] "mm" Vector__XXX
 SG_ TAS_staticHeightEstimateRL m1 : 14|10@1+ (1,-512) [-512|510] "mm" Vector__XXX
 SG_ TAS_componentPressureRL m1 : 24|8@1+ (0.1,0) [0|25.4] "bara" Vector__XXX
 SG_ TAS_rawHeightRR m1 : 32|10@1+ (1,-512) [-512|510] "mm" Vector__XXX
 SG_ TAS_staticHeightEstimateRR m1 : 42|10@1+ (1,-512) [-512|510] "mm" Vector__XXX
 SG_ TAS_componentPressureRR m1 : 52|8@1+ (0.1,0) [0|25.4] "bara" Vector__XXX

BO_ 1398 TAS_dampingStates: 8 TAS
 SG_ TAS_endstopState : 0|1@1+ (1,0) [0|1] "" Vector__XXX
 SG_ TAS_continuousControlState : 1|1@1+ (1,0) [0|1] "" Vector__XXX
 SG_ TAS_activeTireTune : 2|1@1+ (1,0) [0|1] "" Vector__XXX
 SG_ TAS_roughnessRaiseReason : 3|2@1+ (1,0) [0|3] "" Vector__XXX
 SG_ TAS_frontMetricDrivesRear : 5|2@1+ (1,0) [0|3] "" Vector__XXX
 SG_ TAS_roadCondition : 8|8@1+ (0.005,0) [0|1.27] "-" Vector__XXX
 SG_ TAS_bellyProtect : 16|2@1+ (1,0) [0|3] "" Vector__XXX
 SG_ TAS_frontMetricDrivesFront : 18|2@1+ (1,0) [0|3] "" Vector__XXX
 SG_ TAS_speedBumpAxleFront : 20|3@1+ (1,0) [0|7] "" Vector__XXX
 SG_ TAS_speedBumpAxleRear : 23|3@1+ (1,0) [0|7] "" Vector__XXX
 SG_ TAS_holeProtectFL : 26|2@1+ (1,0) [0|3] "" Vector__XXX
 SG_ TAS_holeProtectFR : 28|2@1+ (1,0) [0|3] "" Vector__XXX
 SG_ TAS_holeProtectRL : 30|2@1+ (1,0) [0|3] "" Vector__XXX
 SG_ TAS_holeProtectRR : 32|2@1+ (1,0) [0|3] "" Vector__XXX
 SG_ TAS_stepProtectFL : 34|2@1+ (1,0) [0|3] "" Vector__XXX
 SG_ TAS_stepProtectFR : 36|2@1+ (1,0) [0|3] "" Vector__XXX
 SG_ TAS_stepProtectRL : 38|2@1+ (1,0) [0|3] "" Vector__XXX
 SG_ TAS_stepProtectRR : 40|2@1+ (1,0) [0|3] "" Vector__XXX
 SG_ TAS_FDUTorqueCorruptionScale : 42|4@1+ (0.075,0) [0|1.05] "-" Vector__XXX
 SG_ TAS_sprungMassEstimate : 46|5@1+ (64,1800) [1800|3720] "kg" Vector__XXX
 SG_ TAS_anyDamperActive : 51|1@1+ (1,0) [0|1] "" Vector__XXX
 SG_ TAS_dampingStatesCounter : 52|4@1+ (1,0) [0|15] "" Vector__XXX
 SG_ TAS_dampingStatesChecksum : 56|8@1+ (1,0) [0|255] "" Vector__XXX

BO_ 1357 TAS_info: 8 TAS
 SG_ TAS_infoIndex M : 0|8@1+ (1,0) [0|255] "" Vector__XXX
 SG_ TAS_infoBuildType m10 : 8|8@1+ (1,0) [0|255] "" Vector__XXX
 SG_ TAS_infoBuildConfigId m10 : 16|16@1+ (1,0) [0|65535] "" Vector__XXX
 SG_ TAS_infoHardwareId m10 : 32|1@1+ (1,0) [0|1] "" Vector__XXX
 SG_ TAS_infoComponentId m10 : 48|16@1+ (1,0) [0|65535] "" Vector__XXX
 SG_ TAS_infoPcbaId m11 : 16|8@1+ (1,0) [0|255] "" Vector__XXX
 SG_ TAS_infoAssemblyId m11 : 24|8@1+ (1,0) [0|254] "" Vector__XXX
 SG_ TAS_infoUsageId m11 : 32|16@1+ (1,0) [0|65535] "" Vector__XXX
 SG_ TAS_infoSubUsageId m11 : 48|16@1+ (1,0) [0|65535] "" Vector__XXX
 SG_ TAS_infoAppCrc m13 : 32|32@1+ (1,0) [0|4294967295] "" Vector__XXX
 SG_ TAS_infoAppGitHash m17 : 8|56@1+ (1,0) [0|7.20575940379e+16] "" Vector__XXX
 SG_ TAS_infoBootGitHash m18 : 8|56@1+ (1,0) [0|7.20575940379e+16] "" Vector__XXX
 SG_ TAS_infoPlatformType m19 : 8|8@1+ (1,0) [0|255] "" Vector__XXX
 SG_ TAS_infoMajorVersion m19 : 16|8@1+ (1,0) [0|254] "" Vector__XXX
 SG_ TAS_infoBranchOrigin m19 : 24|8@1+ (1,0) [0|254] "" Vector__XXX
 SG_ TAS_infoMaturity m19 : 32|8@1+ (1,0) [0|254] "" Vector__XXX
 SG_ TAS_infoHardwareRevision m19 : 40|8@1+ (1,0) [0|254] "" Vector__XXX

BO_ 525 TAS_states: 8 TAS
 SG_ TAS_levelingState : 0|4@1+ (1,0) [0|15] "" Vector__XXX
 SG_ TAS_levelingItem : 4|3@1+ (1,0) [0|7] "" Vector__XXX
 SG_ TAS_pressureGallery : 8|8@1+ (0.1,0) [0|25.4] "bara" Vector__XXX
 SG_ TAS_pressureReservoir : 16|8@1+ (0.1,0) [0|25.4] "bara" Vector__XXX
 SG_ TAS_runMode : 24|3@1+ (1,0) [0|7] "" Vector__XXX
 SG_ TAS_filterMode : 27|3@1+ (1,0) [0|7] "" Vector__XXX
 SG_ TAS_compressorRun : 30|1@1+ (1,0) [0|1] "" Vector__XXX
 SG_ TAS_twistDetected : 31|1@1+ (1,0) [0|1] "" Vector__XXX
 SG_ TAS_leanDetected : 32|1@1+ (1,0) [0|1] "" Vector__XXX
 SG_ TAS_limpHomeMode : 33|3@1+ (1,0) [0|7] "" Vector__XXX
 SG_ TAS_targetLevel : 36|3@1+ (1,0) [0|7] "" Vector__XXX
 SG_ TAS_currentLevel : 40|3@1+ (1,0) [0|7] "" Vector__XXX
 SG_ TAS_jackMode : 43|1@1+ (1,0) [0|1] "" Vector__XXX
 SG_ TAS_reduceVehicleSpeedRequest : 44|1@1+ (1,0) [0|1] "" Vector__XXX
 SG_ TAS_statesCounter : 52|4@1+ (1,0) [0|15] "" Vector__XXX
 SG_ TAS_statesChecksum : 56|8@1+ (1,0) [0|255] "" Vector__XXX

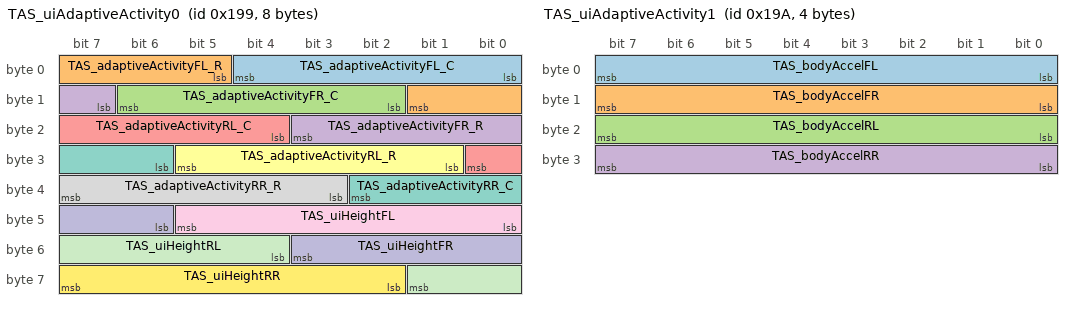
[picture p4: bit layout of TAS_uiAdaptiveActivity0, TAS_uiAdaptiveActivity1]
BO_ 409 TAS_uiAdaptiveActivity0: 8 TAS
 SG_ TAS_adaptiveActivityFL_C : 0|5@1+ (0.04,0) [0|1] "-" Vector__XXX
 SG_ TAS_adaptiveActivityFL_R : 5|5@1+ (0.04,0) [0|1] "-" Vector__XXX
 SG_ TAS_adaptiveActivityFR_C : 10|5@1+ (0.04,0) [0|1] "-" Vector__XXX
 SG_ TAS_adaptiveActivityFR_R : 15|5@1+ (0.04,0) [0|1] "-" Vector__XXX
 SG_ TAS_adaptiveActivityRL_C : 20|5@1+ (0.04,0) [0|1] "-" Vector__XXX
 SG_ TAS_adaptiveActivityRL_R : 25|5@1+ (0.04,0) [0|1] "-" Vector__XXX
 SG_ TAS_adaptiveActivityRR_C : 30|5@1+ (0.04,0) [0|1] "-" Vector__XXX
 SG_ TAS_adaptiveActivityRR_R : 35|5@1+ (0.04,0) [0|1] "-" Vector__XXX
 SG_ TAS_uiHeightFL : 40|6@1+ (4,-128) [-128|120] "mm" Vector__XXX
 SG_ TAS_uiHeightFR : 46|6@1+ (4,-128) [-128|120] "mm" Vector__XXX
 SG_ TAS_uiHeightRL : 52|6@1+ (4,-128) [-128|120] "mm" Vector__XXX
 SG_ TAS_uiHeightRR : 58|6@1+ (4,-128) [-128|120] "mm" Vector__XXX

BO_ 410 TAS_uiAdaptiveActivity1: 4 TAS
 SG_ TAS_bodyAccelFL : 0|8@1+ (0.05,-5) [-5|5] "g" Vector__XXX
 SG_ TAS_bodyAccelFR : 8|8@1+ (0.05,-5) [-5|5] "g" Vector__XXX
 SG_ TAS_bodyAccelRL : 16|8@1+ (0.05,-5) [-5|5] "g" Vector__XXX
 SG_ TAS_bodyAccelRR : 24|8@1+ (0.05,-5) [-5|5] "g" Vector__XXX

BO_ 538 TAS_uiControl: 5 TAS
 SG_ TAS_yellowWarningLamp : 0|1@1+ (1,0) [0|1] "" Vector__XXX
 SG_ TAS_redWarningLamp : 1|1@1+ (1,0) [0|1] "" Vector__XXX
 SG_ TAS_veryLowAllowed : 2|1@1+ (1,0) [0|1] "" Vector__XXX
 SG_ TAS_lowAllowed : 3|1@1+ (1,0) [0|1] "" Vector__XXX
 SG_ TAS_standardAllowed : 4|1@1+ (1,0) [0|1] "" Vector__XXX
 SG_ TAS_highAllowed : 5|1@1+ (1,0) [0|1] "" Vector__XXX
 SG_ TAS_veryHighAllowed : 6|1@1+ (1,0) [0|1] "" Vector__XXX
 SG_ TAS_extractAllowed : 7|1@1+ (1,0) [0|1] "" Vector__XXX
 SG_ TAS_showSpinner : 9|1@1+ (1,0) [0|1] "" Vector__XXX
 SG_ TAS_adaptiveRideModeOverride : 10|2@1+ (1,0) [0|2] "" Vector__XXX
 SG_ TAS_levelSelectEnabled : 12|1@1+ (1,0) [0|1] "" Vector__XXX
 SG_ TAS_jackModeToggleEnabled : 13|1@1+ (1,0) [0|1] "" Vector__XXX
 SG_ TAS_adaptiveRideSelectEnabled : 14|1@1+ (1,0) [0|1] "" Vector__XXX
 SG_ TAS_launchModeState : 16|3@1+ (1,0) [0|7] "" Vector__XXX
 SG_ TAS_restrictUpLevelingFalcons : 19|1@1+ (1,0) [0|1] "" Vector__XXX
 SG_ TAS_restrictUpLevelingTrunk : 20|1@1+ (1,0) [0|1] "" Vector__XXX
 SG_ TAS_restrictDownLevelingDoors : 21|1@1+ (1,0) [0|1] "" Vector__XXX
 SG_ TAS_restrictLevelingChargeCable : 22|1@1+ (1,0) [0|1] "" Vector__XXX
 SG_ TAS_restrictLevelingSystemCheck : 23|1@1+ (1,0) [0|1] "" Vector__XXX
 SG_ TAS_restrictLevelingTransport : 24|1@1+ (1,0) [0|1] "" Vector__XXX
 SG_ TAS_restrictLevelingShowroom : 25|1@1+ (1,0) [0|1] "" Vector__XXX
 SG_ TAS_uiControlCounter : 28|4@1+ (1,0) [0|15] "" Vector__XXX
 SG_ TAS_uiControlChecksum : 32|8@1+ (1,0) [0|255] "" Vector__XXX

BO_ 659 UI_chassisControl: 8 GTW
 SG_ UI_steeringTuneRequest : 0|2@1+ (1,0) [0|3] "" Vector__XXX
 SG_ UI_tractionControlMode : 2|3@1+ (1,0) [0|7] "" Vector__XXX
 SG_ UI_parkBrakeRequest : 5|2@1+ (1,0) [0|2] "" Vector__XXX
 SG_ UI_winchModeRequest : 8|2@1+ (1,0) [0|3] "" Vector__XXX
 SG_ UI_trailerMode : 12|1@1+ (1,0) [0|1] "" Vector__XXX
 SG_ UI_accOvertakeEnable : 16|2@1+ (1,0) [0|2] "" Vector__XXX
 SG_ UI_aebEnable : 18|2@1+ (1,0) [0|2] "" Vector__XXX
 SG_ UI_aesEnable : 20|2@1+ (1,0) [0|2] "" Vector__XXX
 SG_ UI_ahlbEnable : 22|2@1+ (1,0) [0|2] "" Vector__XXX
 SG_ UI_autoLaneChangeEnable : 24|2@1+ (1,0) [0|2] "" Vector__XXX
 SG_ UI_winchProxUserOverride : 26|1@1+ (1,0) [0|1] "" Vector__XXX
 SG_ UI_autoParkRequest : 28|4@1+ (1,0) [0|14] "" Vector__XXX
 SG_ UI_bsdEnable : 32|2@1+ (1,0) [0|2] "" Vector__XXX
 SG_ UI_fcwEnable : 34|2@1+ (1,0) [0|2] "" Vector__XXX
 SG_ UI_fcwSensitivity : 36|2@1+ (1,0) [0|2] "" Vector__XXX
 SG_ UI_latControlEnable : 38|2@1+ (1,0) [0|2] "" Vector__XXX
 SG_ UI_ldwEnable : 40|2@1+ (1,0) [0|2] "" Vector__XXX

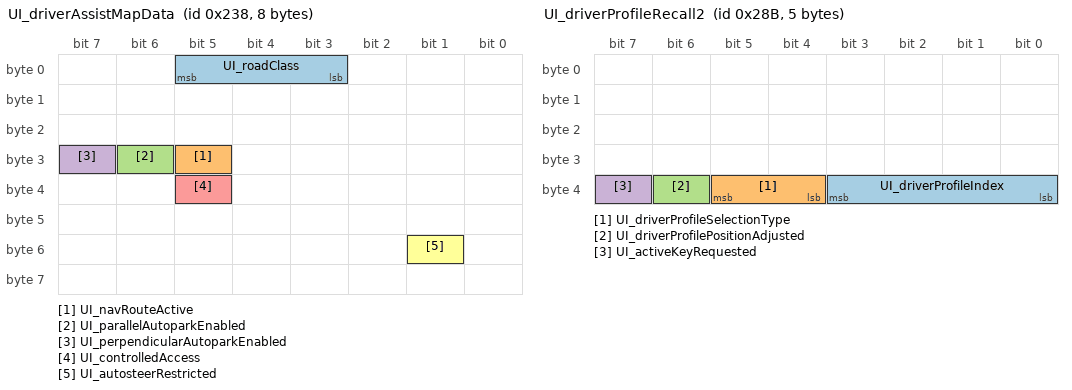
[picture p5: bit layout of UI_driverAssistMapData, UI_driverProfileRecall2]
BO_ 568 UI_driverAssistMapData: 8 GTW
 SG_ UI_roadClass : 3|3@1+ (1,0) [1|7] "" Vector__XXX
 SG_ UI_navRouteActive : 29|1@1+ (1,0) [0|1] "" Vector__XXX
 SG_ UI_parallelAutoparkEnabled : 30|1@1+ (1,0) [0|1] "" Vector__XXX
 SG_ UI_perpendicularAutoparkEnabled : 31|1@1+ (1,0) [0|1] "" Vector__XXX
 SG_ UI_controlledAccess : 37|1@1+ (1,0) [0|1] "" Vector__XXX
 SG_ UI_autosteerRestricted : 49|1@1+ (1,0) [0|1] "" Vector__XXX

BO_ 651 UI_driverProfileRecall2: 5 GTW
 SG_ UI_driverProfileIndex : 32|4@1+ (1,0) [0|15] "" Vector__XXX
 SG_ UI_driverProfileSelectionType : 36|2@1+ (1,0) [0|3] "" Vector__XXX
 SG_ UI_driverProfilePositionAdjusted : 38|1@1+ (1,0) [0|1] "" Vector__XXX
 SG_ UI_activeKeyRequested : 39|1@1+ (1,0) [0|1] "" Vector__XXX

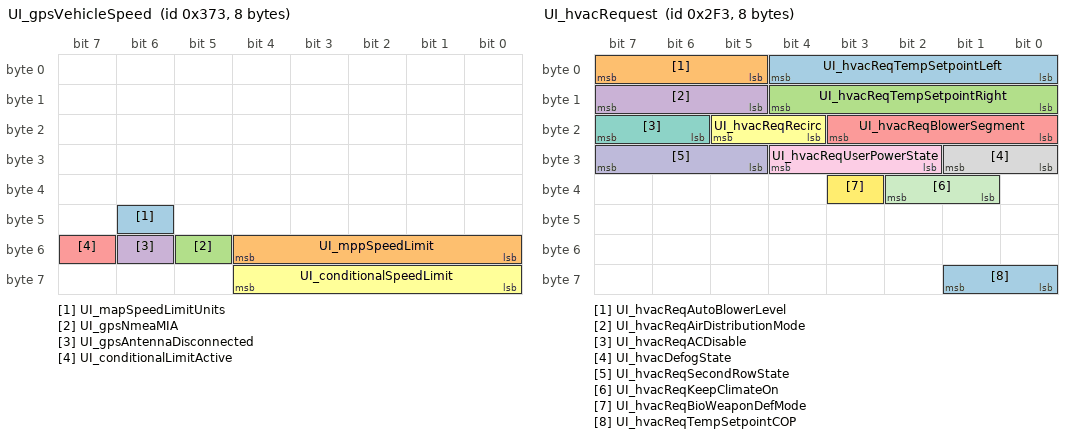
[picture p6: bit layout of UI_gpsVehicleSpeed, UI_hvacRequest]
BO_ 883 UI_gpsVehicleSpeed: 8 GTW
 SG_ UI_mapSpeedLimitUnits : 46|1@1+ (1,0) [0|1] "" Vector__XXX
 SG_ UI_mppSpeedLimit : 48|5@1+ (5,0) [0|155] "kph/mph" Vector__XXX
 SG_ UI_gpsNmeaMIA : 53|1@1+ (1,0) [0|1] "" Vector__XXX
 SG_ UI_gpsAntennaDisconnected : 54|1@1+ (1,0) [0|1] "" Vector__XXX
 SG_ UI_conditionalLimitActive : 55|1@1+ (1,0) [0|1] "" Vector__XXX
 SG_ UI_conditionalSpeedLimit : 56|5@1+ (5,0) [0|150] "kph/mph" Vector__XXX

BO_ 755 UI_hvacRequest: 8 GTW
 SG_ UI_hvacReqTempSetpointLeft : 0|5@1+ (0.5,15) [15|28] "degC" Vector__XXX
 SG_ UI_hvacReqAutoBlowerLevel : 5|3@1+ (1,0) [0|7] "" Vector__XXX
 SG_ UI_hvacReqTempSetpointRight : 8|5@1+ (0.5,15) [15|28] "degC" Vector__XXX
 SG_ UI_hvacReqAirDistributionMode : 13|3@1+ (1,0) [0|7] "" Vector__XXX
 SG_ UI_hvacReqBlowerSegment : 16|4@1+ (1,0) [0|15] "" Vector__XXX
 SG_ UI_hvacReqRecirc : 20|2@1+ (1,0) [0|3] "" Vector__XXX
 SG_ UI_hvacReqACDisable : 22|2@1+ (1,0) [0|3] "" Vector__XXX
 SG_ UI_hvacDefogState : 24|2@1+ (1,0) [0|3] "" Vector__XXX
 SG_ UI_hvacReqUserPowerState : 26|3@1+ (1,0) [0|7] "" Vector__XXX
 SG_ UI_hvacReqSecondRowState : 29|3@1+ (1,0) [0|7] "" Vector__XXX
 SG_ UI_hvacReqKeepClimateOn : 33|2@1+ (1,0) [0|3] "" Vector__XXX
 SG_ UI_hvacReqBioWeaponDefMode : 35|1@1+ (1,0) [0|1] "" Vector__XXX
 SG_ UI_hvacReqTempSetpointCOP : 56|2@1+ (1,0) [0|3] "" Vector__XXX

BO_ 1523 UI_odo: 3 GTW
 SG_ UI_odometer : 0|24@1+ (0.1,0) [0|1677721.4] "km" Vector__XXX

BO_ 948 UI_peripheralPowerRequests: 1 GTW
 SG_ UI_usbFrontHubPowerStateRequest : 0|2@1+ (1,0) [1|3] "" Vector__XXX

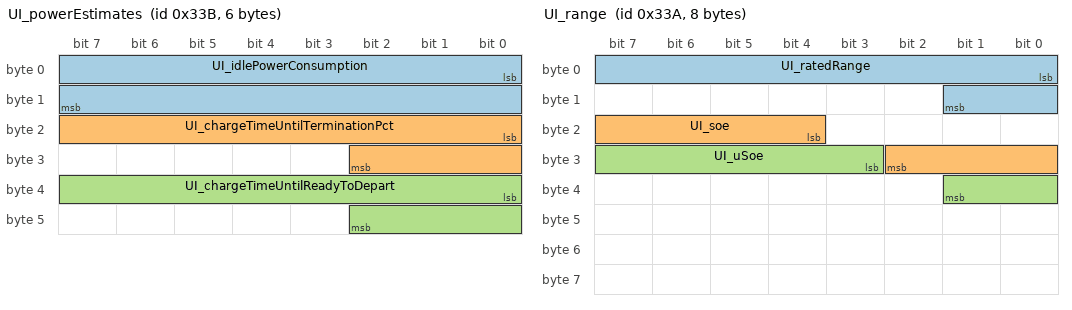
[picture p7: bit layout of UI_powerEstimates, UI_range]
BO_ 827 UI_powerEstimates: 6 GTW
 SG_ UI_idlePowerConsumption : 0|16@1+ (0.001,0) [0|50] "kW" Vector__XXX
 SG_ UI_chargeTimeUntilTerminationPct : 16|11@1+ (1,0) [0|2046] "min" Vector__XXX
 SG_ UI_chargeTimeUntilReadyToDepart : 32|11@1+ (1,0) [0|2046] "min" Vector__XXX

BO_ 826 UI_range: 8 GTW
 SG_ UI_ratedRange : 0|10@1+ (1,0) [0|1023] "mi" Vector__XXX
 SG_ UI_soe : 20|7@1+ (1,0) [0|127] "%" Vector__XXX
 SG_ UI_uSoe : 27|7@1+ (1,0) [0|127] "%" Vector__XXX

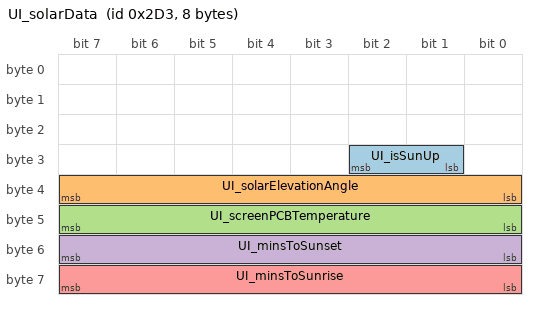
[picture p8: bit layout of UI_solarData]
BO_ 723 UI_solarData: 8 GTW
 SG_ UI_isSunUp : 25|2@1+ (1,0) [0|2] "" Vector__XXX
 SG_ UI_solarElevationAngle : 32|8@1- (1,0) [-128|126] "degrees" Vector__XXX
 SG_ UI_screenPCBTemperature : 40|8@1- (0.5,40) [-20|100] "degC" Vector__XXX
 SG_ UI_minsToSunset : 48|8@1+ (10,0) [0|2550] "min" Vector__XXX
 SG_ UI_minsToSunrise : 56|8@1+ (10,0) [0|2550] "min" Vector__XXX

BO_ 851 UI_status: 8 GTW
 SG_ UI_touchActive : 0|1@1+ (1,0) [0|1] "" Vector__XXX
 SG_ UI_audioActive : 1|1@1+ (1,0) [0|1] "" Vector__XXX
 SG_ UI_cellActive : 3|1@1+ (1,0) [0|1] "" Vector__XXX
 SG_ UI_displayReady : 4|1@1+ (1,0) [0|1] "" Vector__XXX
 SG_ UI_displayOn : 5|1@1+ (1,0) [0|1] "" Vector__XXX
 SG_ UI_wifiActive : 6|1@1+ (1,0) [0|1] "" Vector__XXX
 SG_ UI_wifiConnected : 7|1@1+ (1,0) [0|1] "" Vector__XXX
 SG_ UI_readyForDrive : 9|1@1+ (1,0) [0|1] "" Vector__XXX
 SG_ UI_cellConnected : 10|1@1+ (1,0) [0|1] "" Vector__XXX
 SG_ UI_vpnActive : 11|1@1+ (1,0) [0|1] "" Vector__XXX
 SG_ UI_factoryReset : 14|2@1+ (1,0) [1|3] "" Vector__XXX
 SG_ UI_gpsActive : 16|1@1+ (1,0) [0|1] "" Vector__XXX
 SG_ UI_cellNetworkTechnology : 19|4@1+ (1,0) [0|14] "" Vector__XXX
 SG_ UI_falseTouchCounter : 32|8@1+ (1,0) [0|255] "1" Vector__XXX
 SG_ UI_cellSignalBars : 42|3@1+ (1,0) [0|6] "" Vector__XXX
 SG_ UI_trailerModeTelltale : 45|2@1+ (1,0) [0|3] "" Vector__XXX
 SG_ UI_pcbTemperature : 48|8@1- (1,40) [-20|100] "degC" Vector__XXX
 SG_ UI_cpuTemperature : 56|8@1- (1,40) [-20|100] "degC" Vector__XXX

BO_ 663 UI_suspensionControl: 8 GTW
 SG_ UI_adaptiveRideRequest : 3|2@1+ (1,0) [0|3] "" Vector__XXX
 SG_ UI_geofenceLevelingRequest : 7|3@1+ (1,0) [0|7] "" Vector__XXX

BO_ 627 UI_vehicleControl: 8 GTW
 SG_ UI_powerStateRequest : 0|2@1+ (1,0) [0|3] "" Vector__XXX
 SG_ UI_childDoorLockOnRight : 2|1@1+ (1,0) [0|1] "" Vector__XXX
 SG_ UI_frontFogSwitch : 3|1@1+ (1,0) [0|1] "" Vector__XXX
 SG_ UI_summonActive : 4|1@1+ (1,0) [0|1] "" Vector__XXX
 SG_ UI_frunkRequest : 5|1@1+ (1,0) [0|1] "" Vector__XXX
 SG_ UI_wiperMode : 6|2@1+ (1,0) [1|3] "" Vector__XXX
 SG_ UI_steeringButtonMode : 9|3@1+ (1,0) [0|7] "" Vector__XXX
 SG_ UI_walkUpUnlock : 12|1@1+ (1,0) [0|1] "" Vector__XXX
 SG_ UI_walkAwayLock : 13|1@1+ (1,0) [0|1] "" Vector__XXX
 SG_ UI_unlockOnPark : 14|1@1+ (1,0) [0|1] "" Vector__XXX
 SG_ UI_globalUnlockOn : 15|1@1+ (1,0) [0|1] "" Vector__XXX
 SG_ UI_childDoorLockOnLeft : 16|1@1+ (1,0) [0|1] "" Vector__XXX
 SG_ UI_lockRequest : 17|3@1+ (1,0) [0|6] "" Vector__XXX
 SG_ UI_alarmEnabled : 20|1@1+ (1,0) [0|1] "" Vector__XXX
 SG_ UI_stop12vSupport : 22|1@1+ (1,0) [0|1] "" Vector__XXX
 SG_ UI_rearFogSwitch : 23|1@1+ (1,0) [0|1] "" Vector__XXX
 SG_ UI_mirrorFoldRequest : 24|2@1+ (1,0) [0|2] "" Vector__XXX
 SG_ UI_mirrorHeatRequest : 26|1@1+ (1,0) [0|1] "" Vector__XXX
 SG_ UI_remoteStartRequest : 27|3@1+ (1,0) [0|7] "" Vector__XXX
 SG_ UI_seeYouHomeLightingOn : 30|1@1+ (1,0) [0|1] "" Vector__XXX
 SG_ UI_powerOff : 31|1@1+ (1,0) [0|1] "" Vector__XXX
 SG_ UI_displayBrightnessLevel : 32|8@1+ (0.5,0) [0|127] "%" Vector__XXX
 SG_ UI_autoHighBeamEnabled : 41|1@1+ (1,0) [0|1] "" Vector__XXX
 SG_ UI_frontLeftSeatHeatReq : 42|2@1+ (1,0) [0|3] "" Vector__XXX
 SG_ UI_frontRightSeatHeatReq : 44|2@1+ (1,0) [0|3] "" Vector__XXX
 SG_ UI_rearLeftSeatHeatReq : 46|2@1+ (1,0) [0|3] "" Vector__XXX
 SG_ UI_rearCenterSeatHeatReq : 48|2@1+ (1,0) [0|3] "" Vector__XXX
 SG_ UI_rearRightSeatHeatReq : 50|2@1+ (1,0) [0|3] "" Vector__XXX
 SG_ UI_autoFoldMirrorsOn : 52|1@1+ (1,0) [0|1] "" Vector__XXX
 SG_ UI_mirrorDipOnReverse : 53|1@1+ (1,0) [0|1] "" Vector__XXX
 SG_ UI_remoteClosureRequest : 54|2@1+ (1,0) [0|2] "" Vector__XXX
 SG_ UI_wiperRequest : 56|3@1+ (1,0) [1|7] "" Vector__XXX
 SG_ UI_domeLightSwitch : 59|2@1+ (1,0) [0|3] "" Vector__XXX

BO_ 1285 UMC_smartAdapterInfo: 8 UMC
 SG_ SA_infoIndex M : 0|8@1+ (1,0) [0|255] "" Vector__XXX
 SG_ SA_genealogyVersion m0 : 8|8@1+ (1,0) [0|255] "" Vector__XXX
 SG_ SA_genealogyCrc m0 : 16|32@1+ (1,0) [0|4294967295] "" Vector__XXX
 SG_ SA_region m0 : 48|4@1+ (1,0) [0|15] "" Vector__XXX
 SG_ SA_OverTempThreshold m0 : 56|8@1+ (1,0) [0|255] "" Vector__XXX
 SG_ SA_partNumInt m31 : 8|32@1+ (1,0) [0|4294967295] "" Vector__XXX
 SG_ SA_partNumRev m31 : 40|8@1+ (1,0) [0|255] "" Vector__XXX
 SG_ SA_currentLimit m31 : 48|8@1+ (1,0) [0|255] "" Vector__XXX
 SG_ SA_l1Voltage m31 : 56|8@1+ (1,0) [0|255] "" Vector__XXX

BO_TX_BU_ 1012 : GTW;
BO_TX_BU_ 612 : PCS;
BO_TX_BU_ 692 : PCS;
BO_TX_BU_ 964 : PCS;
BO_TX_BU_ 676 : PCS;
BO_TX_BU_ 790 : PMF;
BO_TX_BU_ 1748 : PMR;
BO_TX_BU_ 1551 : PM;
BO_TX_BU_ 837 : PTC;
BO_TX_BU_ 647 : PTC;
BO_TX_BU_ 816 : SCCM;
BO_TX_BU_ 585 : SCCM;
BO_TX_BU_ 553 : SCCM;
BO_TX_BU_ 297 : SCCM;
BO_TX_BU_ 1597 : SDCR;
BO_TX_BU_ 523 : TAS;
BO_TX_BU_ 1398 : TAS;
BO_TX_BU_ 1357 : TAS;
BO_TX_BU_ 525 : TAS;
BO_TX_BU_ 409 : TAS;
BO_TX_BU_ 410 : TAS;
BO_TX_BU_ 538 : TAS;
BO_TX_BU_ 659 : GTW;
BO_TX_BU_ 568 : GTW;
BO_TX_BU_ 651 : GTW;
BO_TX_BU_ 883 : GTW;
BO_TX_BU_ 755 : GTW;
BO_TX_BU_ 1523 : GTW;
BO_TX_BU_ 948 : GTW;
BO_TX_BU_ 827 : GTW;
BO_TX_BU_ 826 : GTW;
BO_TX_BU_ 723 : GTW;
BO_TX_BU_ 851 : GTW;
BO_TX_BU_ 663 : GTW;
BO_TX_BU_ 627 : GTW;
BO_TX_BU_ 1285 : UMC;
CM_ BO_ 1012 "LS ECU message: light show; forwarded onto this bus by the gateway";
CM_ SG_ 1012 LS_lightShowIndex "LS ECU: light show index";
CM_ SG_ 1012 LS_lightLeftRampedChannel1Reques "LS ECU: light left ramped channel1 request";
CM_ SG_ 1012 LS_lightLeftRampedChannel1Durati "LS ECU: light left ramped channel1 duration";
CM_ SG_ 1012 LS_lightLeftRampedChannel2Reques "LS ECU: light left ramped channel2 request";
CM_ SG_ 1012 LS_lightLeftRampedChannel2Durati "LS ECU: light left ramped channel2 duration";
CM_ SG_ 1012 LS_lightLeftRampedChannel3Reques "LS ECU: light left ramped channel3 request";
CM_ SG_ 1012 LS_lightLeftRampedChannel3Durati "LS ECU: light left ramped channel3 duration";
CM_ SG_ 1012 LS_lightLeftRampedChannel4Reques "LS ECU: light left ramped channel4 request";
CM_ SG_ 1012 LS_lightLeftRampedChannel4Durati "LS ECU: light left ramped channel4 duration";
CM_ SG_ 1012 LS_lightLeftRampedChannel5Reques "LS ECU: light left ramped channel5 request";
CM_ SG_ 1012 LS_lightLeftRampedChannel5Durati "LS ECU: light left ramped channel5 duration";
CM_ SG_ 1012 LS_lightLeftRampedChannel6Reques "LS ECU: light left ramped channel6 request";
CM_ SG_ 1012 LS_lightLeftRampedChannel6Durati "LS ECU: light left ramped channel6 duration";
CM_ SG_ 1012 LS_lightLeftRampedChannel7Reques "LS ECU: light left ramped channel7 request";
CM_ SG_ 1012 LS_lightLeftRampedChannel7Durati "LS ECU: light left ramped channel7 duration";
CM_ SG_ 1012 LS_lightRightRampedChannel1Reque "LS ECU: light right ramped channel1 request";
CM_ SG_ 1012 LS_lightRightRampedChannel1Durat "LS ECU: light right ramped channel1 duration; raw 1 = signal not available (SNA)";
CM_ SG_ 1012 LS_lightRightRampedChannel2Reque "LS ECU: light right ramped channel2 request";
CM_ SG_ 1012 LS_lightRightRampedChannel2Durat "LS ECU: light right ramped channel2 duration; raw 1 = signal not available (SNA)";
CM_ SG_ 1012 LS_lightRightRampedChannel3Reque "LS ECU: light right ramped channel3 request";
CM_ SG_ 1012 LS_lightRightRampedChannel3Durat "LS ECU: light right ramped channel3 duration";
CM_ SG_ 1012 LS_lightRightRampedChannel4Reque "LS ECU: light right ramped channel4 request";
CM_ SG_ 1012 LS_lightRightRampedChannel4Durat "LS ECU: light right ramped channel4 duration";
CM_ SG_ 1012 LS_lightRightRampedChannel5Reque "LS ECU: light right ramped channel5 request";
CM_ SG_ 1012 LS_lightRightRampedChannel5Durat "LS ECU: light right ramped channel5 duration";
CM_ SG_ 1012 LS_lightRightRampedChannel6Reque "LS ECU: light right ramped channel6 request";
CM_ SG_ 1012 LS_lightRightRampedChannel6Durat "LS ECU: light right ramped channel6 duration";
CM_ SG_ 1012 LS_lightRightRampedChannel7Reque "LS ECU: light right ramped channel7 request";
CM_ SG_ 1012 LS_lightRightRampedChannel7Durat "LS ECU: light right ramped channel7 duration";
CM_ SG_ 1012 LS_lightRearTurnLeftRequest "LS ECU: light rear turn left request";
CM_ SG_ 1012 LS_lightRearTurnRightRequest "LS ECU: light rear turn right request";
CM_ SG_ 1012 LS_lightSideRepeaterLeftRequest "LS ECU: light side repeater left request";
CM_ SG_ 1012 LS_lightSideRepeaterRightRequest "LS ECU: light side repeater right request";
CM_ SG_ 1012 LS_lightSideMarkerLeftRequest "LS ECU: light side marker left request";
CM_ SG_ 1012 LS_lightSideMarkerRightRequest "LS ECU: light side marker right request";
CM_ SG_ 1012 LS_lightFrontFogLeftRequest "LS ECU: light front fog left request";
CM_ SG_ 1012 LS_lightFrontFogRightRequest "LS ECU: light front fog right request";
CM_ SG_ 1012 LS_lightRearFogRequest "LS ECU: light rear fog request";
CM_ SG_ 1012 LS_lightBrakeRequest "LS ECU: light brake request";
CM_ SG_ 1012 LS_lightTailLeftRequest "LS ECU: light tail left request";
CM_ SG_ 1012 LS_lightTailRightRequest "LS ECU: light tail right request";
CM_ SG_ 1012 LS_lightLicensePlateRequest "LS ECU: light license plate request";
CM_ SG_ 1012 LS_lightReverseRequest "LS ECU: light reverse request";
CM_ SG_ 1012 LS_lightAuxParkLeftRequest "LS ECU: light aux park left request";
CM_ SG_ 1012 LS_lightAuxParkRightRequest "LS ECU: light aux park right request";
CM_ SG_ 1012 LS_mirrorRequestLeft "LS ECU: mirror request left";
CM_ SG_ 1012 LS_mirrorRequestRight "LS ECU: mirror request right";
CM_ SG_ 1012 LS_liftgateRequest "LS ECU: liftgate request";
CM_ SG_ 1012 LS_windowRequestLF "LS ECU: window request LF";
CM_ SG_ 1012 LS_windowRequestLR "LS ECU: window request LR";
CM_ SG_ 1012 LS_windowRequestRF "LS ECU: window request RF";
CM_ SG_ 1012 LS_windowRequestRR "LS ECU: window request RR";
CM_ SG_ 1012 LS_presentingHandleRequestLF "LS ECU: presenting handle request LF";
CM_ SG_ 1012 LS_presentingHandleRequestLR "LS ECU: presenting handle request LR";
CM_ SG_ 1012 LS_presentingHandleRequestRF "LS ECU: presenting handle request RF";
CM_ SG_ 1012 LS_presentingHandleRequestRR "LS ECU: presenting handle request RR";
CM_ SG_ 1012 LS_powerFrontDoorRequestLeft "LS ECU: power front door request left";
CM_ SG_ 1012 LS_powerFrontDoorRequestRight "LS ECU: power front door request right";
CM_ SG_ 1012 LS_falconDoorRequestLeft "LS ECU: falcon door request left";
CM_ SG_ 1012 LS_falconDoorRequestRight "LS ECU: falcon door request right";
CM_ SG_ 1012 LS_chargePortRequest "LS ECU: charge port request; raw 3 = signal not available (SNA)";
CM_ SG_ 1012 LS_chargePortRaveRequest "LS ECU: charge port rave request";
CM_ SG_ 1012 LS_suspensionRequest "LS ECU: suspension request; raw 3 = signal not available (SNA)";
CM_ SG_ 1012 LS_rgbIPFLRed "LS ECU: rgb IPFL red";
CM_ SG_ 1012 LS_rgbIPFLGreen "LS ECU: rgb IPFL green";
CM_ SG_ 1012 LS_rgbIPFLBlue "LS ECU: rgb IPFL blue";
CM_ SG_ 1012 LS_rgbIPFRRed "LS ECU: rgb IPFR red";
CM_ SG_ 1012 LS_rgbIPFRGreen "LS ECU: rgb IPFR green";
CM_ SG_ 1012 LS_rgbIPFRBlue "LS ECU: rgb IPFR blue";
CM_ SG_ 1012 LS_rgbDoorFLForeRed "LS ECU: rgb door FL fore red";
CM_ SG_ 1012 LS_rgbDoorFLForeGreen "LS ECU: rgb door FL fore green";
CM_ SG_ 1012 LS_rgbDoorFLForeBlue "LS ECU: rgb door FL fore blue";
CM_ SG_ 1012 LS_rgbDoorFLAftRed "LS ECU: rgb door FL aft red";
CM_ SG_ 1012 LS_rgbDoorFLAftGreen "LS ECU: rgb door FL aft green";
CM_ SG_ 1012 LS_rgbDoorFLAftBlue "LS ECU: rgb door FL aft blue";
CM_ SG_ 1012 LS_rgbDoorFRForeRed "LS ECU: rgb door FR fore red";
CM_ SG_ 1012 LS_rgbDoorFRForeGreen "LS ECU: rgb door FR fore green";
CM_ SG_ 1012 LS_rgbDoorFRForeBlue "LS ECU: rgb door FR fore blue";
CM_ SG_ 1012 LS_rgbDoorFRAftRed "LS ECU: rgb door FR aft red";
CM_ SG_ 1012 LS_rgbDoorFRAftGreen "LS ECU: rgb door FR aft green";
CM_ SG_ 1012 LS_rgbDoorFRAftBlue "LS ECU: rgb door FR aft blue";
CM_ SG_ 1012 LS_rgbDoorRLForeRed "LS ECU: rgb door RL fore red";
CM_ SG_ 1012 LS_rgbDoorRLForeGreen "LS ECU: rgb door RL fore green";
CM_ SG_ 1012 LS_rgbDoorRLForeBlue "LS ECU: rgb door RL fore blue";
CM_ SG_ 1012 LS_rgbDoorRLAftRed "LS ECU: rgb door RL aft red";
CM_ SG_ 1012 LS_rgbDoorRLAftGreen "LS ECU: rgb door RL aft green";
CM_ SG_ 1012 LS_rgbDoorRLAftBlue "LS ECU: rgb door RL aft blue";
CM_ SG_ 1012 LS_rgbDoorRRForeRed "LS ECU: rgb door RR fore red";
CM_ SG_ 1012 LS_rgbDoorRRForeGreen "LS ECU: rgb door RR fore green";
CM_ SG_ 1012 LS_rgbDoorRRForeBlue "LS ECU: rgb door RR fore blue";
CM_ SG_ 1012 LS_rgbDoorRRAftRed "LS ECU: rgb door RR aft red";
CM_ SG_ 1012 LS_rgbDoorRRAftGreen "LS ECU: rgb door RR aft green";
CM_ SG_ 1012 LS_rgbDoorRRAftBlue "LS ECU: rgb door RR aft blue";
CM_ SG_ 1012 LS_frontMatrix0 "LS ECU: front matrix0";
CM_ SG_ 1012 LS_frontMatrix1 "LS ECU: front matrix1";
CM_ SG_ 1012 LS_frontMatrix2 "LS ECU: front matrix2";
CM_ SG_ 1012 LS_frontMatrix3 "LS ECU: front matrix3";
CM_ SG_ 1012 LS_frontMatrix4 "LS ECU: front matrix4";
CM_ SG_ 1012 LS_frontMatrix5 "LS ECU: front matrix5";
CM_ SG_ 1012 LS_frontMatrix6 "LS ECU: front matrix6";
CM_ SG_ 1012 LS_frontMatrix7 "LS ECU: front matrix7";
CM_ SG_ 1012 LS_frontMatrix8 "LS ECU: front matrix8";
CM_ SG_ 1012 LS_frontMatrix9 "LS ECU: front matrix9";
CM_ SG_ 1012 LS_frontMatrix10 "LS ECU: front matrix10";
CM_ SG_ 1012 LS_frontMatrix11 "LS ECU: front matrix11";
CM_ SG_ 1012 LS_frontMatrix12 "LS ECU: front matrix12";
CM_ SG_ 1012 LS_frontMatrix13 "LS ECU: front matrix13";
CM_ SG_ 1012 LS_frontMatrix14 "LS ECU: front matrix14";
CM_ SG_ 1012 LS_frontMatrix15 "LS ECU: front matrix15";
CM_ SG_ 1012 LS_frontMatrix16 "LS ECU: front matrix16";
CM_ SG_ 1012 LS_frontMatrix17 "LS ECU: front matrix17";
CM_ SG_ 1012 LS_frontMatrix18 "LS ECU: front matrix18";
CM_ SG_ 1012 LS_frontMatrix19 "LS ECU: front matrix19";
CM_ SG_ 1012 LS_frontMatrix20 "LS ECU: front matrix20";
CM_ SG_ 1012 LS_frontMatrix21 "LS ECU: front matrix21";
CM_ SG_ 1012 LS_frontMatrix22 "LS ECU: front matrix22";
CM_ SG_ 1012 LS_frontMatrix23 "LS ECU: front matrix23";
CM_ SG_ 1012 LS_frontMatrix24 "LS ECU: front matrix24";
CM_ SG_ 1012 LS_frontMatrix25 "LS ECU: front matrix25";
CM_ SG_ 1012 LS_frontMatrix26 "LS ECU: front matrix26";
CM_ SG_ 1012 LS_frontMatrix27 "LS ECU: front matrix27";
CM_ SG_ 1012 LS_frontMatrix28 "LS ECU: front matrix28";
CM_ SG_ 1012 LS_frontMatrix29 "LS ECU: front matrix29";
CM_ SG_ 1012 LS_frontMatrix30 "LS ECU: front matrix30";
CM_ SG_ 1012 LS_frontMatrix31 "LS ECU: front matrix31";
CM_ SG_ 1012 LS_frontMatrix32 "LS ECU: front matrix32";
CM_ SG_ 1012 LS_frontMatrix33 "LS ECU: front matrix33";
CM_ SG_ 1012 LS_frontMatrix34 "LS ECU: front matrix34";
CM_ SG_ 1012 LS_frontMatrix35 "LS ECU: front matrix35";
CM_ SG_ 1012 LS_frontMatrix36 "LS ECU: front matrix36";
CM_ SG_ 1012 LS_frontMatrix37 "LS ECU: front matrix37";
CM_ SG_ 1012 LS_frontMatrix38 "LS ECU: front matrix38";
CM_ SG_ 1012 LS_frontMatrix39 "LS ECU: front matrix39";
CM_ SG_ 1012 LS_frontMatrix40 "LS ECU: front matrix40";
CM_ SG_ 1012 LS_frontMatrix41 "LS ECU: front matrix41";
CM_ SG_ 1012 LS_frontMatrix42 "LS ECU: front matrix42";
CM_ SG_ 1012 LS_frontMatrix43 "LS ECU: front matrix43";
CM_ SG_ 1012 LS_frontMatrix44 "LS ECU: front matrix44";
CM_ SG_ 1012 LS_frontMatrix45 "LS ECU: front matrix45";
CM_ SG_ 1012 LS_frontMatrix46 "LS ECU: front matrix46";
CM_ SG_ 1012 LS_frontMatrix47 "LS ECU: front matrix47";
CM_ SG_ 1012 LS_frontMatrix48 "LS ECU: front matrix48";
CM_ SG_ 1012 LS_frontMatrix49 "LS ECU: front matrix49";
CM_ SG_ 1012 LS_frontMatrix50 "LS ECU: front matrix50";
CM_ SG_ 1012 LS_frontMatrix51 "LS ECU: front matrix51";
CM_ SG_ 1012 LS_frontMatrix52 "LS ECU: front matrix52";
CM_ SG_ 1012 LS_frontMatrix53 "LS ECU: front matrix53";
CM_ SG_ 1012 LS_frontMatrix54 "LS ECU: front matrix54";
CM_ SG_ 1012 LS_frontMatrix55 "LS ECU: front matrix55";
CM_ SG_ 1012 LS_frontMatrix56 "LS ECU: front matrix56";
CM_ SG_ 1012 LS_frontMatrix57 "LS ECU: front matrix57";
CM_ SG_ 1012 LS_frontMatrix58 "LS ECU: front matrix58";
CM_ SG_ 1012 LS_frontMatrix59 "LS ECU: front matrix59";
CM_ SG_ 1012 LS_rearMatrix0 "LS ECU: rear matrix0";
CM_ SG_ 1012 LS_rearMatrix1 "LS ECU: rear matrix1";
CM_ SG_ 1012 LS_rearMatrix2 "LS ECU: rear matrix2";
CM_ SG_ 1012 LS_rearMatrix3 "LS ECU: rear matrix3";
CM_ SG_ 1012 LS_rearMatrix4 "LS ECU: rear matrix4";
CM_ SG_ 1012 LS_rearMatrix5 "LS ECU: rear matrix5";
CM_ SG_ 1012 LS_rearMatrix6 "LS ECU: rear matrix6";
CM_ SG_ 1012 LS_rearMatrix7 "LS ECU: rear matrix7";
CM_ SG_ 1012 LS_rearMatrix8 "LS ECU: rear matrix8";
CM_ SG_ 1012 LS_rearMatrix9 "LS ECU: rear matrix9";
CM_ SG_ 1012 LS_rearMatrix10 "LS ECU: rear matrix10";
CM_ SG_ 1012 LS_rearMatrix11 "LS ECU: rear matrix11";
CM_ SG_ 1012 LS_rearMatrix12 "LS ECU: rear matrix12";
CM_ SG_ 1012 LS_rearMatrix13 "LS ECU: rear matrix13";
CM_ SG_ 1012 LS_rearMatrix14 "LS ECU: rear matrix14";
CM_ SG_ 1012 LS_rearMatrix15 "LS ECU: rear matrix15";
CM_ SG_ 1012 LS_rearMatrix16 "LS ECU: rear matrix16";
CM_ SG_ 1012 LS_rearMatrix17 "LS ECU: rear matrix17";
CM_ SG_ 1012 LS_rearMatrix18 "LS ECU: rear matrix18";
CM_ SG_ 1012 LS_rearMatrix19 "LS ECU: rear matrix19";
CM_ SG_ 1012 LS_rearMatrix20 "LS ECU: rear matrix20";
CM_ SG_ 1012 LS_rearMatrix21 "LS ECU: rear matrix21";
CM_ SG_ 1012 LS_rearMatrix22 "LS ECU: rear matrix22";
CM_ SG_ 1012 LS_rearMatrix23 "LS ECU: rear matrix23";
CM_ SG_ 1012 LS_rearMatrix24 "LS ECU: rear matrix24";
CM_ SG_ 1012 LS_rearMatrix25 "LS ECU: rear matrix25";
CM_ SG_ 1012 LS_rearMatrix26 "LS ECU: rear matrix26";
CM_ SG_ 1012 LS_rearMatrix27 "LS ECU: rear matrix27";
CM_ SG_ 1012 LS_rearMatrix28 "LS ECU: rear matrix28";
CM_ SG_ 1012 LS_rearMatrix29 "LS ECU: rear matrix29";
CM_ SG_ 1012 LS_rearMatrix30 "LS ECU: rear matrix30";
CM_ SG_ 1012 LS_rearMatrix31 "LS ECU: rear matrix31";
CM_ SG_ 1012 LS_rearMatrix32 "LS ECU: rear matrix32";
CM_ SG_ 1012 LS_rearMatrix33 "LS ECU: rear matrix33";
CM_ SG_ 1012 LS_rearMatrix34 "LS ECU: rear matrix34";
CM_ SG_ 1012 LS_rearMatrix35 "LS ECU: rear matrix35";
CM_ SG_ 1012 LS_rearMatrix36 "LS ECU: rear matrix36";
CM_ SG_ 1012 LS_rearMatrix37 "LS ECU: rear matrix37";
CM_ SG_ 1012 LS_rearMatrix38 "LS ECU: rear matrix38";
CM_ SG_ 1012 LS_rearMatrix39 "LS ECU: rear matrix39";
CM_ SG_ 1012 LS_rearMatrix40 "LS ECU: rear matrix40";
CM_ SG_ 1012 LS_rearMatrix41 "LS ECU: rear matrix41";
CM_ SG_ 1012 LS_rearMatrix42 "LS ECU: rear matrix42";
CM_ SG_ 1012 LS_rearMatrix43 "LS ECU: rear matrix43";
CM_ SG_ 1012 LS_rearMatrix44 "LS ECU: rear matrix44";
CM_ SG_ 1012 LS_rearMatrix45 "LS ECU: rear matrix45";
CM_ SG_ 1012 LS_rearMatrix46 "LS ECU: rear matrix46";
CM_ SG_ 1012 LS_rearMatrix47 "LS ECU: rear matrix47";
CM_ SG_ 1012 LS_rearMatrix48 "LS ECU: rear matrix48";
CM_ SG_ 1012 LS_rearMatrix49 "LS ECU: rear matrix49";
CM_ SG_ 1012 LS_rearMatrix50 "LS ECU: rear matrix50";
CM_ SG_ 1012 LS_rearMatrix51 "LS ECU: rear matrix51";
CM_ SG_ 1012 LS_rearMatrix52 "LS ECU: rear matrix52";
CM_ SG_ 1012 LS_rearMatrix53 "LS ECU: rear matrix53";
CM_ SG_ 1012 LS_rearMatrix54 "LS ECU: rear matrix54";
CM_ SG_ 1012 LS_rearMatrix55 "LS ECU: rear matrix55";
CM_ SG_ 1012 LS_rearMatrix56 "LS ECU: rear matrix56";
CM_ SG_ 1012 LS_rearMatrix57 "LS ECU: rear matrix57";
CM_ SG_ 1012 LS_rearMatrix58 "LS ECU: rear matrix58";
CM_ SG_ 1012 LS_rearMatrix59 "LS ECU: rear matrix59";
CM_ SG_ 1012 LS_offroadLightBar0 "LS ECU: offroad light bar0";
CM_ SG_ 1012 LS_offroadLightBar1 "LS ECU: offroad light bar1";
CM_ SG_ 1012 LS_offroadLightBar2 "LS ECU: offroad light bar2";
CM_ SG_ 1012 LS_offroadLightBar3 "LS ECU: offroad light bar3";
CM_ SG_ 1012 LS_offroadLightBar4 "LS ECU: offroad light bar4";
CM_ SG_ 1012 LS_offroadLightBar5 "LS ECU: offroad light bar5";
CM_ BO_ 612 "Power conversion system (on-board charger and DC-DC converter) message: chg line status";
CM_ SG_ 612 PCS_chgInputVoltage "RMS value of AC charger's sensed input voltage";
CM_ SG_ 612 PCS_chgLineCurrent "AC charger's sensed input line current";
CM_ SG_ 612 PCS_chgAcVoltagePresent "Indicates whether AC voltage is present on the PCS input";
CM_ SG_ 612 PCS_chgInputPower "Total AC charger input power";
CM_ SG_ 612 PCS_chgAcCurrentLimit "Maximum AC current that can be pulled from a single conductor";
CM_ BO_ 692 "Power conversion system (on-board charger and DC-DC converter) message: dcdc rail status";
CM_ SG_ 692 PCS_dcdcLvBusVolt "DCDC's sensed LV bus voltage";
CM_ SG_ 692 PCS_dcdcHvBusVolt "DCDC's sensed HV bus voltage";
CM_ SG_ 692 PCS_dcdcLvOutputCurrent "DCDC's computed LV output current";
CM_ BO_ 964 "Power conversion system (on-board charger and DC-DC converter) message: info";
CM_ SG_ 964 PCS_infoIndex "Power conversion system (on-board charger and DC-DC converter): info index";
CM_ SG_ 964 PCS_buildType "Power conversion system (on-board charger and DC-DC converter): build type";
CM_ SG_ 964 PCS_buildConfigId "Power conversion system (on-board charger and DC-DC converter): build config id";
CM_ SG_ 964 PCS_hardwareId "Power conversion system (on-board charger and DC-DC converter): hardware id";
CM_ SG_ 964 PCS_componentId "Power conversion system (on-board charger and DC-DC converter): component id";
CM_ SG_ 964 PCS_pcbaId "PCBA ID portion of component hardware ID as reported by application";
CM_ SG_ 964 PCS_assemblyId "Power conversion system (on-board charger and DC-DC converter): assembly id";
CM_ SG_ 964 PCS_usageId "Usage ID portion of component hardware ID as reported by application";
CM_ SG_ 964 PCS_subUsageId "Sub-usage ID portion of component hardware ID as reported by application";
CM_ SG_ 964 PCS_platformType "Power conversion system (on-board charger and DC-DC converter): platform type";
CM_ SG_ 964 PCS_appCrc "Power conversion system (on-board charger and DC-DC converter): app crc";
CM_ SG_ 964 PCS_cpu2AppCrc "Power conversion system (on-board charger and DC-DC converter): cpu2 app crc";
CM_ SG_ 964 PCS_appGitHash "Power conversion system (on-board charger and DC-DC converter): app git hash";
CM_ SG_ 964 PCS_bootGitHash "Power conversion system (on-board charger and DC-DC converter): boot git hash";
CM_ SG_ 964 PCS_bootUdsProtoVersion "Power conversion system (on-board charger and DC-DC converter): boot uds proto version";
CM_ SG_ 964 PCS_bootCrc "Power conversion system (on-board charger and DC-DC converter): boot crc";
CM_ BO_ 676 "Power conversion system (on-board charger and DC-DC converter) message: thermal status";
CM_ SG_ 676 PCS_chgPhATemp "Sensed temperature of AC charger phase A; raw 1025 = signal not available (SNA)";
CM_ SG_ 676 PCS_chgPhBTemp "Sensed temperature of AC charger phase B; raw 1025 = signal not available (SNA)";
CM_ SG_ 676 PCS_chgPhCTemp "Sensed temperature of AC charger phase C; raw 1025 = signal not available (SNA)";
CM_ SG_ 676 PCS_dcdcTemp "Sensed temperature of DCDC; raw 1025 = signal not available (SNA)";
CM_ SG_ 676 PCS_ambientTemp "Ambient temperature sensed by the PCS; raw 1025 = signal not available (SNA)";
CM_ SG_ 676 PCS_dcdcBusbarTemp "Sensed temperature of DCDC busbar; raw 511 = signal not available (SNA)";
CM_ BO_ 790 "PMF ECU message: info";
CM_ SG_ 790 PMF_infoIndex "PMF ECU: info index";
CM_ SG_ 790 PMF_buildType "PMF ECU: build type";
CM_ SG_ 790 PMF_buildConfigurationId "PMF ECU: build configuration id";
CM_ SG_ 790 PMF_hardwareId "PMF ECU: hardware id";
CM_ SG_ 790 PMF_deviceFused "PMF ECU: device fused";
CM_ SG_ 790 PMF_componentId "PMF ECU: component id";
CM_ SG_ 790 PMF_pcbaId "PMF ECU: pcba id";
CM_ SG_ 790 PMF_assemblyId "PMF ECU: assembly id";
CM_ SG_ 790 PMF_usageId "PMF ECU: usage id";
CM_ SG_ 790 PMF_subUsageId "PMF ECU: sub usage id";
CM_ SG_ 790 PMF_applicationCrc "PMF ECU: application crc";
CM_ SG_ 790 PMF_appGitHash "PMF ECU: app git hash";
CM_ SG_ 790 PMF_bootGitHash "PMF ECU: boot git hash";
CM_ SG_ 790 PMF_platformTyp "PMF ECU: platform typ";
CM_ SG_ 790 PMF_udsProtocolVersion "PMF ECU: uds protocol version";
CM_ SG_ 790 PMF_bootloaderCrc "PMF ECU: bootloader crc";
CM_ BO_ 1748 "PMR ECU message: info";
CM_ SG_ 1748 PMR_infoIndex "PMR ECU: info index";
CM_ SG_ 1748 PMR_buildType "PMR ECU: build type";
CM_ SG_ 1748 PMR_buildConfigurationId "PMR ECU: build configuration id";
CM_ SG_ 1748 PMR_hardwareId "PMR ECU: hardware id";
CM_ SG_ 1748 PMR_deviceFused "PMR ECU: device fused";
CM_ SG_ 1748 PMR_componentId "PMR ECU: component id";
CM_ SG_ 1748 PMR_pcbaId "PMR ECU: pcba id";
CM_ SG_ 1748 PMR_assemblyId "PMR ECU: assembly id";
CM_ SG_ 1748 PMR_usageId "PMR ECU: usage id";
CM_ SG_ 1748 PMR_subUsageId "PMR ECU: sub usage id";
CM_ SG_ 1748 PMR_applicationCrc "PMR ECU: application crc";
CM_ SG_ 1748 PMR_appGitHash "PMR ECU: app git hash";
CM_ SG_ 1748 PMR_bootGitHash "PMR ECU: boot git hash";
CM_ SG_ 1748 PMR_platformTyp "PMR ECU: platform typ";
CM_ SG_ 1748 PMR_udsProtocolVersion "PMR ECU: uds protocol version";
CM_ SG_ 1748 PMR_bootloaderCrc "PMR ECU: bootloader crc";
CM_ BO_ 1551 "PM ECU message: info";
CM_ SG_ 1551 PM_infoIndex "PM ECU: info index";
CM_ SG_ 1551 PM_buildType "PM ECU: build type";
CM_ SG_ 1551 PM_buildConfigurationId "PM ECU: build configuration id";
CM_ SG_ 1551 PM_hardwareId "PM ECU: hardware id";
CM_ SG_ 1551 PM_deviceFused "PM ECU: device fused";
CM_ SG_ 1551 PM_componentId "PM ECU: component id";
CM_ SG_ 1551 PM_pcbaId "PM ECU: pcba id";
CM_ SG_ 1551 PM_assemblyId "PM ECU: assembly id";
CM_ SG_ 1551 PM_usageId "PM ECU: usage id";
CM_ SG_ 1551 PM_subUsageId "PM ECU: sub usage id";
CM_ SG_ 1551 PM_applicationCrc "PM ECU: application crc";
CM_ SG_ 1551 PM_bootGitHash "PM ECU: boot git hash";
CM_ BO_ 837 "Cabin heater message: info";
CM_ SG_ 837 PTC_infoIndex "Cabin heater: info index";
CM_ SG_ 837 PTC_infoBuildType "Cabin heater: info build type";
CM_ SG_ 837 PTC_infoBuildConfigId "Cabin heater: info build config id";
CM_ SG_ 837 PTC_infoHardwareId "Cabin heater: info hardware id";
CM_ SG_ 837 PTC_infoComponentId "Cabin heater: info component id";
CM_ SG_ 837 PTC_infoPcbaId "Cabin heater: info pcba id";
CM_ SG_ 837 PTC_infoAssemblyId "Cabin heater: info assembly id; raw 255 = signal not available (SNA)";
CM_ SG_ 837 PTC_infoUsageId "Cabin heater: info usage id";
CM_ SG_ 837 PTC_infoSubUsageId "Cabin heater: info sub usage id";
CM_ SG_ 837 PTC_infoPlatformType "Cabin heater: info platform type";
CM_ SG_ 837 PTC_infoAppCrc "Cabin heater: info app crc";
CM_ SG_ 837 PTC_infoBootUdsProtoVersion "Cabin heater: info boot uds proto version";
CM_ SG_ 837 PTC_infoBootCrc "Cabin heater: info boot crc";
CM_ BO_ 647 "Cabin heater message: sensor status";
CM_ SG_ 647 PTC_leftTempIGBT "Heater left bank IGBT temperature";
CM_ SG_ 647 PTC_tempOCP "Temperature measured near the over current protection circuit";
CM_ SG_ 647 PTC_rightTempIGBT "Heater right bank IGBT temperature";
CM_ SG_ 647 PTC_tempPCB "Heater printed circuit board temperature";
CM_ SG_ 647 PTC_voltageHV "Heater high voltage input voltage";
CM_ SG_ 647 PTC_leftCurrentHV "Cabin heater: left current HV";
CM_ SG_ 647 PTC_rightCurrentHV "Cabin heater: right current HV";
CM_ BO_ 816 "Steering column control module message: info";
CM_ SG_ 816 SCCM_infoIndex "Steering column control module: info index";
CM_ SG_ 816 SCCM_infoBuildType "Steering column control module: info build type";
CM_ SG_ 816 SCCM_infoBuildConfigId "Steering column control module: info build config id";
CM_ SG_ 816 SCCM_infoHardwareId "Steering column control module: info hardware id";
CM_ SG_ 816 SCCM_infoComponentId "Steering column control module: info component id";
CM_ SG_ 816 SCCM_infoPcbaId "Steering column control module: info pcba id";
CM_ SG_ 816 SCCM_infoAssemblyId "Steering column control module: info assembly id";
CM_ SG_ 816 SCCM_infoUsageId "Steering column control module: info usage id";
CM_ SG_ 816 SCCM_infoSubUsageId "Steering column control module: info sub usage id";
CM_ SG_ 816 SCCM_infoPlatformType "Steering column control module: info platform type";
CM_ SG_ 816 SCCM_infoAppCrc "Steering column control module: info app crc";
CM_ SG_ 816 SCCM_infoBootSvnRev "Steering column control module: info boot svn rev";
CM_ SG_ 816 SCCM_infoBootSvnUrlHash "Steering column control module: info boot svn url hash";
CM_ SG_ 816 SCCM_infoSubcomponent1Version "Steering column control module: info subcomponent1 version";
CM_ SG_ 816 SCCM_infoAppSvnHash "Steering column control module: info app svn hash";
CM_ SG_ 816 SCCM_infoBootSvnHash "Steering column control module: info boot svn hash";
CM_ SG_ 816 SCCM_infoUdsProtoVersion "Steering column control module: info uds proto version";
CM_ SG_ 816 SCCM_infoBootCrc "Steering column control module: info boot crc";
CM_ BO_ 585 "Steering column control module message: left stalk";
CM_ SG_ 585 SCCM_leftStalkCrc "Steering column control module: left stalk crc";
CM_ SG_ 585 SCCM_leftStalkCounter "Steering column control module: left stalk counter";
CM_ SG_ 585 SCCM_highBeamStalkStatus "Active state of high beam push/pull stalk position; raw 3 = signal not available (SNA)";
CM_ SG_ 585 SCCM_washWipeButtonStatus "Active state of wash/wipe button on the turn signal stalk; raw 3 = signal not available (SNA)";
CM_ SG_ 585 SCCM_turnIndicatorStalkStatus "Active state of turn indicator stalk position; raw 9 = signal not available (SNA)";
CM_ SG_ 585 SCCM_turnIndicatorStalkAngle "Measured angle of the turn signal stalk; raw 4095 = signal not available (SNA)";
CM_ BO_ 553 "Steering column control module message: right stalk";
CM_ SG_ 553 SCCM_rightStalkCrc "Steering column control module: right stalk crc";
CM_ SG_ 553 SCCM_rightStalkCounter "Steering column control module: right stalk counter";
CM_ SG_ 553 SCCM_rightStalkStatus "Active state of drive stalk position, does not indicate active drive gear; raw 6 = signal not available (SNA)";
CM_ SG_ 553 SCCM_rightStalkReserved1 "Steering column control module: right stalk reserved1";
CM_ SG_ 553 SCCM_parkButtonStatus "Active state of park button on the drive stalk; raw 3 = signal not available (SNA)";
CM_ SG_ 553 SCCM_rightStalkReserved2 "Steering column control module: right stalk reserved2";
CM_ BO_ 297 "Steering column control module message: steering angle sensor";
CM_ SG_ 297 SCCM_steeringAngleCrc "Steering column control module: steering angle crc";
CM_ SG_ 297 SCCM_steeringAngleCounter "Message counter";
CM_ SG_ 297 SCCM_supplierID "Steering column control module: supplier ID";
CM_ SG_ 297 SCCM_steeringAngleSensorStatus "Reports steering angle sensor status and validity based on bootup checks";
CM_ SG_ 297 SCCM_steeringAngle "Measured ASAS sensor angle; raw 16383 = signal not available (SNA)";
CM_ SG_ 297 SCCM_steeringAngleValidity "Transitions to VALID when rotation of over 4 deg has occurred; raw 3 = signal not available (SNA)";
CM_ SG_ 297 SCCM_steeringAngleSpeed "Speed of steering angle rotation";
CM_ SG_ 297 SCCM_steeringAngleSensorReservd1 "Steering column control module: steering angle sensor reservd1";
CM_ SG_ 297 SCCM_steeringAngleSensorReservd2 "Steering column control module: steering angle sensor reservd2";
CM_ SG_ 297 SCCM_steeringAngleSensorReservd3 "Steering column control module: steering angle sensor reservd3";
CM_ BO_ 1597 "SDCR ECU message: info";
CM_ SG_ 1597 SDCR_infoIndex "SDCR ECU: info index";
CM_ SG_ 1597 SDCR_infoBuildType "SDCR ECU: info build type";
CM_ SG_ 1597 SDCR_infoBuildConfigId "SDCR ECU: info build config id";
CM_ SG_ 1597 SDCR_infoHardwareId "SDCR ECU: info hardware id";
CM_ SG_ 1597 SDCR_infoComponentId "SDCR ECU: info component id";
CM_ SG_ 1597 SDCR_infoPcbaId "SDCR ECU: info pcba id";
CM_ SG_ 1597 SDCR_infoAssemblyId "SDCR ECU: info assembly id";
CM_ SG_ 1597 SDCR_infoUsageId "SDCR ECU: info usage id";
CM_ SG_ 1597 SDCR_infoSubUsageId "SDCR ECU: info sub usage id";
CM_ SG_ 1597 SDCR_infoAppCrc "SDCR ECU: info app crc";
CM_ SG_ 1597 SDCR_infoBootGitHash "SDCR ECU: info boot git hash";
CM_ BO_ 523 "Air suspension controller message: axle data";
CM_ SG_ 523 TAS_axleIndex "Air suspension controller: axle index";
CM_ SG_ 523 TAS_rawHeightFL "Current height of the FL air spring; raw 1023 = signal not available (SNA)";
CM_ SG_ 523 TAS_staticHeightEstimateFL "Current static height estimate of the FL air spring; raw 1023 = signal not available (SNA)";
CM_ SG_ 523 TAS_componentPressureFL "Current static pressure of the FL air spring; raw 255 = signal not available (SNA)";
CM_ SG_ 523 TAS_rawHeightFR "Current height of the FR air spring; raw 1023 = signal not available (SNA)";
CM_ SG_ 523 TAS_staticHeightEstimateFR "Current static height estimate of the FR air spring; raw 1023 = signal not available (SNA)";
CM_ SG_ 523 TAS_componentPressureFR "Current static pressure of the FR air spring; raw 255 = signal not available (SNA)";
CM_ SG_ 523 TAS_rawHeightRL "Current height of the RL air spring; raw 1023 = signal not available (SNA)";
CM_ SG_ 523 TAS_staticHeightEstimateRL "Current static height estimate of the RL air spring; raw 1023 = signal not available (SNA)";
CM_ SG_ 523 TAS_componentPressureRL "Current static pressure of the RL air spring; raw 255 = signal not available (SNA)";
CM_ SG_ 523 TAS_rawHeightRR "Current height of the RR air spring; raw 1023 = signal not available (SNA)";
CM_ SG_ 523 TAS_staticHeightEstimateRR "Current static height estimate of the RR air spring; raw 1023 = signal not available (SNA)";
CM_ SG_ 523 TAS_componentPressureRR "Current static pressure of the RR air spring; raw 255 = signal not available (SNA)";
CM_ BO_ 1398 "Air suspension controller message: damping states";
CM_ SG_ 1398 TAS_endstopState "Air suspension controller: endstop state";
CM_ SG_ 1398 TAS_continuousControlState "SW-237496";
CM_ SG_ 1398 TAS_activeTireTune "Air suspension controller: active tire tune";
CM_ SG_ 1398 TAS_roughnessRaiseReason "Air suspension controller: roughness raise reason";
CM_ SG_ 1398 TAS_frontMetricDrivesRear "Air suspension controller: front metric drives rear";
CM_ SG_ 1398 TAS_roadCondition "Air suspension controller: road condition; raw 255 = signal not available (SNA)";
CM_ SG_ 1398 TAS_bellyProtect "Air suspension controller: belly protect";
CM_ SG_ 1398 TAS_frontMetricDrivesFront "Air suspension controller: front metric drives front";
CM_ SG_ 1398 TAS_speedBumpAxleFront "Air suspension controller: speed bump axle front";
CM_ SG_ 1398 TAS_speedBumpAxleRear "Air suspension controller: speed bump axle rear";
CM_ SG_ 1398 TAS_holeProtectFL "Air suspension controller: hole protect FL";
CM_ SG_ 1398 TAS_holeProtectFR "Air suspension controller: hole protect FR";
CM_ SG_ 1398 TAS_holeProtectRL "Air suspension controller: hole protect RL";
CM_ SG_ 1398 TAS_holeProtectRR "Air suspension controller: hole protect RR";
CM_ SG_ 1398 TAS_stepProtectFL "Air suspension controller: step protect FL";
CM_ SG_ 1398 TAS_stepProtectFR "Air suspension controller: step protect FR";
CM_ SG_ 1398 TAS_stepProtectRL "Air suspension controller: step protect RL";
CM_ SG_ 1398 TAS_stepProtectRR "Air suspension controller: step protect RR";
CM_ SG_ 1398 TAS_FDUTorqueCorruptionScale "Air suspension controller: FDU torque corruption scale; raw 15 = signal not available (SNA)";
CM_ SG_ 1398 TAS_sprungMassEstimate "Air suspension controller: sprung mass estimate; raw 31 = signal not available (SNA)";
CM_ SG_ 1398 TAS_anyDamperActive "Air suspension controller: any damper active";
CM_ SG_ 1398 TAS_dampingStatesCounter "Air suspension controller: damping states counter";
CM_ SG_ 1398 TAS_dampingStatesChecksum "Air suspension controller: damping states checksum";
CM_ BO_ 1357 "Air suspension controller message: info";
CM_ SG_ 1357 TAS_infoIndex "Air suspension controller: info index";
CM_ SG_ 1357 TAS_infoBuildType "Air suspension controller: info build type";
CM_ SG_ 1357 TAS_infoBuildConfigId "Air suspension controller: info build config id";
CM_ SG_ 1357 TAS_infoHardwareId "Air suspension controller: info hardware id";
CM_ SG_ 1357 TAS_infoComponentId "Air suspension controller: info component id";
CM_ SG_ 1357 TAS_infoPcbaId "Air suspension controller: info pcba id";
CM_ SG_ 1357 TAS_infoAssemblyId "Air suspension controller: info assembly id; raw 255 = signal not available (SNA)";
CM_ SG_ 1357 TAS_infoUsageId "Air suspension controller: info usage id";
CM_ SG_ 1357 TAS_infoSubUsageId "Air suspension controller: info sub usage id";
CM_ SG_ 1357 TAS_infoAppCrc "Air suspension controller: info app crc";
CM_ SG_ 1357 TAS_infoAppGitHash "Air suspension controller: info app git hash";
CM_ SG_ 1357 TAS_infoBootGitHash "Air suspension controller: info boot git hash";
CM_ SG_ 1357 TAS_infoPlatformType "Air suspension controller: info platform type";
CM_ SG_ 1357 TAS_infoMajorVersion "Air suspension controller: info major version; raw 255 = signal not available (SNA)";
CM_ SG_ 1357 TAS_infoBranchOrigin "Air suspension controller: info branch origin; raw 255 = signal not available (SNA)";
CM_ SG_ 1357 TAS_infoMaturity "Air suspension controller: info maturity; raw 255 = signal not available (SNA)";
CM_ SG_ 1357 TAS_infoHardwareRevision "Air suspension controller: info hardware revision; raw 255 = signal not available (SNA)";
CM_ BO_ 525 "Air suspension controller message: states";
CM_ SG_ 525 TAS_levelingState "Indicates air suspension leveling state.";
CM_ SG_ 525 TAS_levelingItem "Indicates the currently active air suspension components.";
CM_ SG_ 525 TAS_pressureGallery "Current air suspension valve block gallery pressure; raw 255 = signal not available (SNA)";
CM_ SG_ 525 TAS_pressureReservoir "Indicates the latest valid reservoir pressure; raw 255 = signal not available (SNA)";
CM_ SG_ 525 TAS_runMode "Indicates the status of run mode.";
CM_ SG_ 525 TAS_filterMode "Indicates the status of filter mode.";
CM_ SG_ 525 TAS_compressorRun "Either an indication that the compressor is running or a request to run the air compressor";
CM_ SG_ 525 TAS_twistDetected "TAS has detected large amount of twist.";
CM_ SG_ 525 TAS_leanDetected "TAS has detected vehicle to be leaning left or right.";
CM_ SG_ 525 TAS_limpHomeMode "Indicates which limp home mode is active.";
CM_ SG_ 525 TAS_targetLevel "Indicates target ride height.";
CM_ SG_ 525 TAS_currentLevel "Indicates current ride height.";
CM_ SG_ 525 TAS_jackMode "Indicates the status of Jack mode.";
CM_ SG_ 525 TAS_reduceVehicleSpeedRequest "Air suspension controller: reduce vehicle speed request";
CM_ SG_ 525 TAS_statesCounter "Air suspension controller: states counter";
CM_ SG_ 525 TAS_statesChecksum "Air suspension controller: states checksum";
CM_ BO_ 409 "Air suspension controller message: ui adaptive activity0";
CM_ SG_ 409 TAS_adaptiveActivityFL_C "Air suspension controller: adaptive activity FL c; raw 31 = signal not available (SNA)";
CM_ SG_ 409 TAS_adaptiveActivityFL_R "Air suspension controller: adaptive activity FL r; raw 31 = signal not available (SNA)";
CM_ SG_ 409 TAS_adaptiveActivityFR_C "Air suspension controller: adaptive activity FR c; raw 31 = signal not available (SNA)";
CM_ SG_ 409 TAS_adaptiveActivityFR_R "Air suspension controller: adaptive activity FR r; raw 31 = signal not available (SNA)";
CM_ SG_ 409 TAS_adaptiveActivityRL_C "Air suspension controller: adaptive activity RL c; raw 31 = signal not available (SNA)";
CM_ SG_ 409 TAS_adaptiveActivityRL_R "Air suspension controller: adaptive activity RL r; raw 31 = signal not available (SNA)";
CM_ SG_ 409 TAS_adaptiveActivityRR_C "Air suspension controller: adaptive activity RR c; raw 31 = signal not available (SNA)";
CM_ SG_ 409 TAS_adaptiveActivityRR_R "Air suspension controller: adaptive activity RR r; raw 31 = signal not available (SNA)";
CM_ SG_ 409 TAS_uiHeightFL "Air suspension controller: ui height FL; raw 63 = signal not available (SNA)";
CM_ SG_ 409 TAS_uiHeightFR "Air suspension controller: ui height FR; raw 63 = signal not available (SNA)";
CM_ SG_ 409 TAS_uiHeightRL "Air suspension controller: ui height RL; raw 63 = signal not available (SNA)";
CM_ SG_ 409 TAS_uiHeightRR "Air suspension controller: ui height RR; raw 63 = signal not available (SNA)";
CM_ BO_ 410 "Air suspension controller message: ui adaptive activity1";
CM_ SG_ 410 TAS_bodyAccelFL "Air suspension controller: body accel FL; raw 255 = signal not available (SNA)";
CM_ SG_ 410 TAS_bodyAccelFR "Air suspension controller: body accel FR; raw 255 = signal not available (SNA)";
CM_ SG_ 410 TAS_bodyAccelRL "Air suspension controller: body accel RL; raw 255 = signal not available (SNA)";
CM_ SG_ 410 TAS_bodyAccelRR "Air suspension controller: body accel RR; raw 255 = signal not available (SNA)";
CM_ BO_ 538 "Air suspension controller message: ui control";
CM_ SG_ 538 TAS_yellowWarningLamp "Air suspension controller: yellow warning lamp";
CM_ SG_ 538 TAS_redWarningLamp "Air suspension controller: red warning lamp";
CM_ SG_ 538 TAS_veryLowAllowed "Air suspension controller: very low allowed";
CM_ SG_ 538 TAS_lowAllowed "Air suspension controller: low allowed";
CM_ SG_ 538 TAS_standardAllowed "Air suspension controller: standard allowed";
CM_ SG_ 538 TAS_highAllowed "Air suspension controller: high allowed";
CM_ SG_ 538 TAS_veryHighAllowed "Air suspension controller: very high allowed";
CM_ SG_ 538 TAS_extractAllowed "Air suspension controller: extract allowed";
CM_ SG_ 538 TAS_showSpinner "Air suspension controller: show spinner";
CM_ SG_ 538 TAS_adaptiveRideModeOverride "Air suspension controller: adaptive ride mode override; raw 3 = signal not available (SNA)";
CM_ SG_ 538 TAS_levelSelectEnabled "Air suspension controller: level select enabled";
CM_ SG_ 538 TAS_jackModeToggleEnabled "Air suspension controller: jack mode toggle enabled";
CM_ SG_ 538 TAS_adaptiveRideSelectEnabled "Air suspension controller: adaptive ride select enabled";
CM_ SG_ 538 TAS_launchModeState "Air suspension controller: launch mode state";
CM_ SG_ 538 TAS_restrictUpLevelingFalcons "Air suspension controller: restrict up leveling falcons";
CM_ SG_ 538 TAS_restrictUpLevelingTrunk "Air suspension controller: restrict up leveling trunk";
CM_ SG_ 538 TAS_restrictDownLevelingDoors "Air suspension controller: restrict down leveling doors";
CM_ SG_ 538 TAS_restrictLevelingChargeCable "Air suspension controller: restrict leveling charge cable";
CM_ SG_ 538 TAS_restrictLevelingSystemCheck "Air suspension controller: restrict leveling system check";
CM_ SG_ 538 TAS_restrictLevelingTransport "Air suspension controller: restrict leveling transport";
CM_ SG_ 538 TAS_restrictLevelingShowroom "Indication that up and down leveling are restricted while showroom mode is active.";
CM_ SG_ 538 TAS_uiControlCounter "Air suspension controller: ui control counter";
CM_ SG_ 538 TAS_uiControlChecksum "Air suspension controller: ui control checksum";
CM_ BO_ 659 "Touchscreen user interface computer message: chassis control; forwarded onto this bus by the gateway";
CM_ SG_ 659 UI_steeringTuneRequest "UI customer level request for steering feel. MS had comfort, normal, sport. M3 intent is Normal, sport see SW-95934";
CM_ SG_ 659 UI_tractionControlMode "Transport user selected traction control modes";
CM_ SG_ 659 UI_parkBrakeRequest "User selection for Park brake; raw 3 = signal not available (SNA)";
CM_ SG_ 659 UI_winchModeRequest "Winch mode (towing) request";
CM_ SG_ 659 UI_trailerMode "Indicates whether trailer mode is selected. To be used when towing a trailer.";
CM_ SG_ 659 UI_accOvertakeEnable "Enable ACC Overtake assistance (reduce follow distance when the turn signal is on), UI firmware only sets datavalue to True; raw 3 = signal not available (SNA)";
CM_ SG_ 659 UI_aebEnable "Enable Autonomous Emergency Brakes; raw 3 = signal not available (SNA)";
CM_ SG_ 659 UI_aesEnable "Enable Automatic Emergency Steering (associated datavalue set to true and never changed by UI firmware); raw 3 = signal not available (SNA)";
CM_ SG_ 659 UI_ahlbEnable "Enable Automatic High/Low Beams; raw 3 = signal not available (SNA)";
CM_ SG_ 659 UI_autoLaneChangeEnable "Enable Automatic Lane Change; raw 3 = signal not available (SNA)";
CM_ SG_ 659 UI_winchProxUserOverride "User feedback from tow mode panel confirming that charge cable is disconnected when vehicle is unable to determine cable status";
CM_ SG_ 659 UI_autoParkRequest "Request Automatic Parking; raw 15 = signal not available (SNA)";
CM_ SG_ 659 UI_bsdEnable "Enable Blind Spot Detection (datavalue defaults to true and not changed by UI firmware); raw 3 = signal not available (SNA)";
CM_ SG_ 659 UI_fcwEnable "Enable Forward Collision Warning; raw 3 = signal not available (SNA)";
CM_ SG_ 659 UI_fcwSensitivity "Forward Collision Warning Level; raw 3 = signal not available (SNA)";
CM_ SG_ 659 UI_latControlEnable "Enable Lateral Control (lane centering, lane keeping, lane changing); raw 3 = signal not available (SNA)";
CM_ SG_ 659 UI_ldwEnable "Enable Lane Departure Warning; raw 3 = signal not available (SNA)";
CM_ BO_ 568 "Touchscreen user interface computer message: driver assist map data; forwarded onto this bus by the gateway";
CM_ SG_ 568 UI_roadClass "Autopilot map road class; raw 0 = signal not available (SNA)";
CM_ SG_ 568 UI_navRouteActive "Navigation route is active";
CM_ SG_ 568 UI_parallelAutoparkEnabled "Autopilot map parallel park enabled.";
CM_ SG_ 568 UI_perpendicularAutoparkEnabled "Autopilot map perpendicular park enabled.";
CM_ SG_ 568 UI_controlledAccess "DAS map controlled access segment.";
CM_ SG_ 568 UI_autosteerRestricted "Autopilot map is autostreer restricted.";
CM_ BO_ 651 "Touchscreen user interface computer message: driver profile recall2; forwarded onto this bus by the gateway";
CM_ SG_ 651 UI_driverProfileIndex "Tracks manual driver profile selection. Shows the linked phonekey / key card / key fob or profile index if not linked";
CM_ SG_ 651 UI_driverProfileSelectionType "Tracks manual driver profile selection. Shows the linked phonekey / key card / key fob or profile index if not linked";
CM_ SG_ 651 UI_driverProfilePositionAdjusted "Tracks adjustments to driver profile. Sets when a profile position has been adjusted from what was saved";
CM_ SG_ 651 UI_activeKeyRequested "Tracks manual driver profile selection. Shows the linked phonekey / key card / key fob or profile index if not linked";
CM_ BO_ 883 "Touchscreen user interface computer message: gps vehicle speed; forwarded onto this bus by the gateway";
CM_ SG_ 883 UI_mapSpeedLimitUnits "Autopilot map speed limit units.";
CM_ SG_ 883 UI_mppSpeedLimit "Autopilot map speed limit";
CM_ SG_ 883 UI_gpsNmeaMIA "GPS NMEA data MIA";
CM_ SG_ 883 UI_gpsAntennaDisconnected "GPS antenna state";
CM_ SG_ 883 UI_conditionalLimitActive "Conditional speed limit condition is currently active";
CM_ SG_ 883 UI_conditionalSpeedLimit "Conditional speed limit value; raw 31 = signal not available (SNA)";
CM_ BO_ 755 "Touchscreen user interface computer message: hvac request; forwarded onto this bus by the gateway";
CM_ SG_ 755 UI_hvacReqTempSetpointLeft "HVAC left set temperature.";
CM_ SG_ 755 UI_hvacReqAutoBlowerLevel "Reports the auto Heating, Ventilation, and Air Conditioning (HVAC) speed aggressiveness setting.";
CM_ SG_ 755 UI_hvacReqTempSetpointRight "HVAC right set temperature.";
CM_ SG_ 755 UI_hvacReqAirDistributionMode "Request for air distribution mode.";
CM_ SG_ 755 UI_hvacReqBlowerSegment "HVAC manual blower request (GUI_hvacManualBlowerRequest)";
CM_ SG_ 755 UI_hvacReqRecirc "HVAC recirculation mode";
CM_ SG_ 755 UI_hvacReqACDisable "Request to disable AC.";
CM_ SG_ 755 UI_hvacDefogState "HVAC defog state.";
CM_ SG_ 755 UI_hvacReqUserPowerState "Reports HVAC power state.";
CM_ SG_ 755 UI_hvacReqSecondRowState "HVAC rear fan request speed.";
CM_ SG_ 755 UI_hvacReqKeepClimateOn "Request accessory power";
CM_ SG_ 755 UI_hvacReqBioWeaponDefMode "Request for BioWeapon Defense Mode";
CM_ SG_ 755 UI_hvacReqTempSetpointCOP "HVAC cabin overheat protection set temperature.";
CM_ BO_ 1523 "Touchscreen user interface computer message: odo; forwarded onto this bus by the gateway";
CM_ SG_ 1523 UI_odometer "Odometer; raw 16777215 = signal not available (SNA)";
CM_ BO_ 948 "Touchscreen user interface computer message: peripheral power requests; forwarded onto this bus by the gateway";
CM_ SG_ 948 UI_usbFrontHubPowerStateRequest "Reports the Universal Serial Bus (USB) Hub power request; raw 0 = signal not available (SNA)";
CM_ BO_ 827 "Touchscreen user interface computer message: power estimates; forwarded onto this bus by the gateway";
CM_ SG_ 827 UI_idlePowerConsumption "Power consumption when idle";
CM_ SG_ 827 UI_chargeTimeUntilTerminationPct "Charge time minutes until reached uSoe target; raw 2047 = signal not available (SNA)";
CM_ SG_ 827 UI_chargeTimeUntilReadyToDepart "Charge time minutes until enough energy to depart for rest of trip; raw 2047 = signal not available (SNA)";
CM_ BO_ 826 "Touchscreen user interface computer message: range; forwarded onto this bus by the gateway";
CM_ SG_ 826 UI_ratedRange "Rated range in miles";
CM_ SG_ 826 UI_soe "State of energy";
CM_ SG_ 826 UI_uSoe "Usable state of energy";
CM_ BO_ 723 "Touchscreen user interface computer message: solar data; forwarded onto this bus by the gateway";
CM_ SG_ 723 UI_isSunUp "is sun up; raw 3 = signal not available (SNA)";
CM_ SG_ 723 UI_solarElevationAngle "Solar Elevation Angle; raw 127 = signal not available (SNA)";
CM_ SG_ 723 UI_screenPCBTemperature "Temperature of display PCB";
CM_ SG_ 723 UI_minsToSunset "time until to sunset";
CM_ SG_ 723 UI_minsToSunrise "time until to sunrise";
CM_ BO_ 851 "Touchscreen user interface computer message: status; forwarded onto this bus by the gateway";
CM_ SG_ 851 UI_touchActive "No touchscreen errors";
CM_ SG_ 851 UI_audioActive "Audio system is ready.";
CM_ SG_ 851 UI_cellActive "Cell is powered";
CM_ SG_ 851 UI_displayReady "UI is ready (GUI_allReady) and display is ok (GUI_displayHardwareOK)";
CM_ SG_ 851 UI_displayOn "UI display on/off status";
CM_ SG_ 851 UI_wifiActive "WiFi active.";
CM_ SG_ 851 UI_wifiConnected "WiFi Connected.";
CM_ SG_ 851 UI_readyForDrive "Ready for drive (UI ready or self park request)";
CM_ SG_ 851 UI_cellConnected "Detects if the cell is connected to a network.";
CM_ SG_ 851 UI_vpnActive "VPN connected.";
CM_ SG_ 851 UI_factoryReset "UI request for factory reset; raw 0 = signal not available (SNA)";
CM_ SG_ 851 UI_gpsActive "GPS has valid fix";
CM_ SG_ 851 UI_cellNetworkTechnology "Describes the type of cellular network to which the car computer is connected: GPRS_2G(114Kbps) < EGDE_2G(368Kbps) < 3G(3Mbps) < HSDPA_3G(14Mbps) < HSPAplus_4Gg(168Mbps) < 4G_LTE(299Mbps); raw 15 = signal not available (SNA)";
CM_ SG_ 851 UI_falseTouchCounter "Count false touches after display is off.";
CM_ SG_ 851 UI_cellSignalBars "Number of cellular signal bars displayed on the UI, derived from cellSignalStrength; raw 7 = signal not available (SNA)";
CM_ SG_ 851 UI_trailerModeTelltale "Color of the trailer mode telltale";
CM_ SG_ 851 UI_pcbTemperature "PCB digital temp sensor reading in DegC";
CM_ SG_ 851 UI_cpuTemperature "Apollo Lake SOC temperature in DegC";
CM_ BO_ 663 "Touchscreen user interface computer message: suspension control; forwarded onto this bus by the gateway";
CM_ SG_ 663 UI_adaptiveRideRequest "UI customer adaptive ride request for air suspension.";
CM_ SG_ 663 UI_geofenceLevelingRequest "Geofence level request from customer; raw 5 = signal not available (SNA)";
CM_ BO_ 627 "Touchscreen user interface computer message: vehicle control; forwarded onto this bus by the gateway";
CM_ SG_ 627 UI_powerStateRequest "Request accessory power";
CM_ SG_ 627 UI_childDoorLockOnRight "UI child door lock request status.";
CM_ SG_ 627 UI_frontFogSwitch "Request for front fog lights to be on";
CM_ SG_ 627 UI_summonActive "Summon is active";
CM_ SG_ 627 UI_frunkRequest "Request open frunk";
CM_ SG_ 627 UI_wiperMode "Wiper mode state; raw 0 = signal not available (SNA)";
CM_ SG_ 627 UI_steeringButtonMode "Steering wheel control mode";
CM_ SG_ 627 UI_walkUpUnlock "Walk up unlock request (datavalue defaults to false)";
CM_ SG_ 627 UI_walkAwayLock "Walk away door lock setting.";
CM_ SG_ 627 UI_unlockOnPark "Unlock on park setting";
CM_ SG_ 627 UI_globalUnlockOn "Global Unlock Setting";
CM_ SG_ 627 UI_childDoorLockOnLeft "UI child door lock request status.";
CM_ SG_ 627 UI_lockRequest "Lock or unlock request; raw 7 = signal not available (SNA)";
CM_ SG_ 627 UI_alarmEnabled "UI customer level request to enable alarm.";
CM_ SG_ 627 UI_stop12vSupport "UI request to stop rails as 12v support";
CM_ SG_ 627 UI_rearFogSwitch "Request for rear fog lights to be on";
CM_ SG_ 627 UI_mirrorFoldRequest "Fold the mirrors; raw 3 = signal not available (SNA)";
CM_ SG_ 627 UI_mirrorHeatRequest "Customer usage of mirror heater and rear defrost";
CM_ SG_ 627 UI_remoteStartRequest "remote start or self park request; raw 4 = signal not available (SNA)";
CM_ SG_ 627 UI_seeYouHomeLightingOn "Headlights after exit";
CM_ SG_ 627 UI_powerOff "power off rails request.";
CM_ SG_ 627 UI_displayBrightnessLevel "UI brightness; raw 255 = signal not available (SNA)";
CM_ SG_ 627 UI_autoHighBeamEnabled "Enable Automatic High/Low Beams";
CM_ SG_ 627 UI_frontLeftSeatHeatReq "Request for front left seat heat";
CM_ SG_ 627 UI_frontRightSeatHeatReq "Request for front left seat heat";
CM_ SG_ 627 UI_rearLeftSeatHeatReq "UI request for second row left seat heater";
CM_ SG_ 627 UI_rearCenterSeatHeatReq "UI request for second row middle seat heater";
CM_ SG_ 627 UI_rearRightSeatHeatReq "UI request for second row right seat heater";
CM_ SG_ 627 UI_autoFoldMirrorsOn "Enable Automatic Mirror Fold/Unfold";
CM_ SG_ 627 UI_mirrorDipOnReverse "Enable Mirror Dip On Reverse";
CM_ SG_ 627 UI_remoteClosureRequest "remote actuate trunk; raw 3 = signal not available (SNA)";
CM_ SG_ 627 UI_wiperRequest "Wiper speed; raw 0 = signal not available (SNA)";
CM_ SG_ 627 UI_domeLightSwitch "Dome light switch";
CM_ BO_ 1285 "UMC ECU message: smart adapter info";
CM_ SG_ 1285 SA_infoIndex "UMC ECU: info index";
CM_ SG_ 1285 SA_genealogyVersion "UMC ECU: genealogy version";
CM_ SG_ 1285 SA_genealogyCrc "UMC ECU: genealogy crc";
CM_ SG_ 1285 SA_region "Reports the smart adapter region from Electrically Erasable Programmable Read-Only Memory (EEPROM).";
CM_ SG_ 1285 SA_OverTempThreshold "Reports the smart adapter overtemperature threshold from Electrically Erasable Programmable Read-Only Memory (EEPROM).";
CM_ SG_ 1285 SA_partNumInt "Reports the smart adapter part number integer representation.";
CM_ SG_ 1285 SA_partNumRev "Reports the smart adapter part number revision.";
CM_ SG_ 1285 SA_currentLimit "Reports the smart adapter current limit from Electrically Erasable Programmable Read-Only Memory (EEPROM).";
CM_ SG_ 1285 SA_l1Voltage "Reports the smart adapter nominal voltage request from Electrically Erasable Programmable Read-Only Memory (EEPROM).";
BA_DEF_ BO_ "GenMsgCycleTime" INT 0 3600000;
BA_DEF_ BO_ "GenMsgSendType" ENUM "Cyclic","NotUsed","NotUsed","NotUsed","NotUsed","NotUsed","NotUsed","IfActive","NoMsgSendType","NotUsed";
BA_DEF_ BO_ "VFrameFormat" ENUM "StandardCAN","ExtendedCAN","reserved","J1939PG","reserved","reserved","reserved","reserved","reserved","reserved","reserved","reserved","reserved","reserved","StandardCAN_FD","ExtendedCAN_FD";
BA_DEF_ BO_ "CANFD_BRS" ENUM "0","1";
BA_DEF_ SG_ "GenSigSNA" STRING;
BA_DEF_ SG_ "SystemSignalLongSymbol" STRING;
BA_DEF_ SG_ "Confidence" ENUM "validated","plausible","layout-only","contradicted";
BA_DEF_DEF_ "GenMsgCycleTime" 0;
BA_DEF_DEF_ "GenMsgSendType" "NoMsgSendType";
BA_DEF_DEF_ "VFrameFormat" "StandardCAN";
BA_DEF_DEF_ "CANFD_BRS" "1";
BA_DEF_DEF_ "GenSigSNA" "";
BA_DEF_DEF_ "SystemSignalLongSymbol" "";
BA_DEF_DEF_ "Confidence" "layout-only";
BA_ "GenMsgCycleTime" BO_ 612 100;
BA_ "GenMsgSendType" BO_ 612 0;
BA_ "GenMsgCycleTime" BO_ 692 100;
BA_ "GenMsgSendType" BO_ 692 0;
BA_ "GenMsgCycleTime" BO_ 964 1000;
BA_ "GenMsgSendType" BO_ 964 0;
BA_ "GenMsgCycleTime" BO_ 676 1000;
BA_ "GenMsgSendType" BO_ 676 0;
BA_ "GenMsgCycleTime" BO_ 790 1000;
BA_ "GenMsgSendType" BO_ 790 0;
BA_ "GenMsgCycleTime" BO_ 1748 1000;
BA_ "GenMsgSendType" BO_ 1748 0;
BA_ "GenMsgCycleTime" BO_ 1551 1000;
BA_ "GenMsgSendType" BO_ 1551 0;
BA_ "GenMsgCycleTime" BO_ 837 1000;
BA_ "GenMsgSendType" BO_ 837 0;
BA_ "GenMsgCycleTime" BO_ 647 100;
BA_ "GenMsgSendType" BO_ 647 0;
BA_ "GenMsgCycleTime" BO_ 816 1000;
BA_ "GenMsgSendType" BO_ 816 0;
BA_ "GenMsgCycleTime" BO_ 585 50;
BA_ "GenMsgSendType" BO_ 585 0;
BA_ "GenMsgCycleTime" BO_ 553 100;
BA_ "GenMsgSendType" BO_ 553 0;
BA_ "GenMsgCycleTime" BO_ 297 10;
BA_ "GenMsgSendType" BO_ 297 0;
BA_ "GenMsgCycleTime" BO_ 1597 1000;
BA_ "GenMsgSendType" BO_ 1597 0;
BA_ "GenMsgCycleTime" BO_ 523 20;
BA_ "GenMsgSendType" BO_ 523 0;
BA_ "GenMsgCycleTime" BO_ 1398 100;
BA_ "GenMsgSendType" BO_ 1398 0;
BA_ "GenMsgCycleTime" BO_ 1357 1000;
BA_ "GenMsgSendType" BO_ 1357 0;
BA_ "GenMsgCycleTime" BO_ 525 100;
BA_ "GenMsgSendType" BO_ 525 0;
BA_ "GenMsgCycleTime" BO_ 409 50;
BA_ "GenMsgSendType" BO_ 409 0;
BA_ "GenMsgCycleTime" BO_ 410 50;
BA_ "GenMsgSendType" BO_ 410 0;
BA_ "GenMsgCycleTime" BO_ 538 100;
BA_ "GenMsgSendType" BO_ 538 0;
BA_ "GenMsgCycleTime" BO_ 659 500;
BA_ "GenMsgSendType" BO_ 659 0;
BA_ "GenMsgCycleTime" BO_ 568 500;
BA_ "GenMsgSendType" BO_ 568 0;
BA_ "GenMsgCycleTime" BO_ 651 500;
BA_ "GenMsgSendType" BO_ 651 0;
BA_ "GenMsgCycleTime" BO_ 883 1000;
BA_ "GenMsgSendType" BO_ 883 0;
BA_ "GenMsgCycleTime" BO_ 755 500;
BA_ "GenMsgSendType" BO_ 755 0;
BA_ "GenMsgCycleTime" BO_ 1523 1000;
BA_ "GenMsgSendType" BO_ 1523 0;
BA_ "GenMsgCycleTime" BO_ 948 500;
BA_ "GenMsgSendType" BO_ 948 0;
BA_ "GenMsgCycleTime" BO_ 827 1000;
BA_ "GenMsgSendType" BO_ 827 0;
BA_ "GenMsgCycleTime" BO_ 826 1000;
BA_ "GenMsgSendType" BO_ 826 0;
BA_ "GenMsgCycleTime" BO_ 723 1000;
BA_ "GenMsgSendType" BO_ 723 0;
BA_ "GenMsgCycleTime" BO_ 851 1000;
BA_ "GenMsgSendType" BO_ 851 0;
BA_ "GenMsgCycleTime" BO_ 663 500;
BA_ "GenMsgSendType" BO_ 663 0;
BA_ "GenMsgCycleTime" BO_ 627 500;
BA_ "GenMsgSendType" BO_ 627 0;
BA_ "GenMsgCycleTime" BO_ 1285 100;
BA_ "GenMsgSendType" BO_ 1285 0;
BA_ "Confidence" SG_ 1012 LS_lightShowIndex 1;
BA_ "Confidence" SG_ 1012 LS_lightLeftRampedChannel1Reques 0;
BA_ "SystemSignalLongSymbol" SG_ 1012 LS_lightLeftRampedChannel1Reques "LS_lightLeftRampedChannel1Request";
BA_ "Confidence" SG_ 1012 LS_lightLeftRampedChannel1Durati 0;
BA_ "SystemSignalLongSymbol" SG_ 1012 LS_lightLeftRampedChannel1Durati "LS_lightLeftRampedChannel1Duration";
BA_ "Confidence" SG_ 1012 LS_lightLeftRampedChannel2Reques 0;
BA_ "SystemSignalLongSymbol" SG_ 1012 LS_lightLeftRampedChannel2Reques "LS_lightLeftRampedChannel2Request";
BA_ "Confidence" SG_ 1012 LS_lightLeftRampedChannel2Durati 0;
BA_ "SystemSignalLongSymbol" SG_ 1012 LS_lightLeftRampedChannel2Durati "LS_lightLeftRampedChannel2Duration";
BA_ "Confidence" SG_ 1012 LS_lightLeftRampedChannel3Reques 0;
BA_ "SystemSignalLongSymbol" SG_ 1012 LS_lightLeftRampedChannel3Reques "LS_lightLeftRampedChannel3Request";
BA_ "Confidence" SG_ 1012 LS_lightLeftRampedChannel3Durati 0;
BA_ "SystemSignalLongSymbol" SG_ 1012 LS_lightLeftRampedChannel3Durati "LS_lightLeftRampedChannel3Duration";
BA_ "Confidence" SG_ 1012 LS_lightLeftRampedChannel4Reques 0;
BA_ "SystemSignalLongSymbol" SG_ 1012 LS_lightLeftRampedChannel4Reques "LS_lightLeftRampedChannel4Request";
BA_ "Confidence" SG_ 1012 LS_lightLeftRampedChannel4Durati 0;
BA_ "SystemSignalLongSymbol" SG_ 1012 LS_lightLeftRampedChannel4Durati "LS_lightLeftRampedChannel4Duration";
BA_ "Confidence" SG_ 1012 LS_lightLeftRampedChannel5Reques 0;
BA_ "SystemSignalLongSymbol" SG_ 1012 LS_lightLeftRampedChannel5Reques "LS_lightLeftRampedChannel5Request";
BA_ "Confidence" SG_ 1012 LS_lightLeftRampedChannel5Durati 0;
BA_ "SystemSignalLongSymbol" SG_ 1012 LS_lightLeftRampedChannel5Durati "LS_lightLeftRampedChannel5Duration";
BA_ "Confidence" SG_ 1012 LS_lightLeftRampedChannel6Reques 0;
BA_ "SystemSignalLongSymbol" SG_ 1012 LS_lightLeftRampedChannel6Reques "LS_lightLeftRampedChannel6Request";
BA_ "Confidence" SG_ 1012 LS_lightLeftRampedChannel6Durati 0;
BA_ "SystemSignalLongSymbol" SG_ 1012 LS_lightLeftRampedChannel6Durati "LS_lightLeftRampedChannel6Duration";
BA_ "Confidence" SG_ 1012 LS_lightLeftRampedChannel7Reques 0;
BA_ "SystemSignalLongSymbol" SG_ 1012 LS_lightLeftRampedChannel7Reques "LS_lightLeftRampedChannel7Request";
BA_ "Confidence" SG_ 1012 LS_lightLeftRampedChannel7Durati 0;
BA_ "SystemSignalLongSymbol" SG_ 1012 LS_lightLeftRampedChannel7Durati "LS_lightLeftRampedChannel7Duration";
BA_ "Confidence" SG_ 1012 LS_lightRightRampedChannel1Reque 0;
BA_ "SystemSignalLongSymbol" SG_ 1012 LS_lightRightRampedChannel1Reque "LS_lightRightRampedChannel1Request";
BA_ "Confidence" SG_ 1012 LS_lightRightRampedChannel1Durat 0;
BA_ "GenSigSNA" SG_ 1012 LS_lightRightRampedChannel1Durat "1";
BA_ "SystemSignalLongSymbol" SG_ 1012 LS_lightRightRampedChannel1Durat "LS_lightRightRampedChannel1Duration";
BA_ "Confidence" SG_ 1012 LS_lightRightRampedChannel2Reque 0;
BA_ "SystemSignalLongSymbol" SG_ 1012 LS_lightRightRampedChannel2Reque "LS_lightRightRampedChannel2Request";
BA_ "Confidence" SG_ 1012 LS_lightRightRampedChannel2Durat 0;
BA_ "GenSigSNA" SG_ 1012 LS_lightRightRampedChannel2Durat "1";
BA_ "SystemSignalLongSymbol" SG_ 1012 LS_lightRightRampedChannel2Durat "LS_lightRightRampedChannel2Duration";
BA_ "Confidence" SG_ 1012 LS_lightRightRampedChannel3Reque 0;
BA_ "SystemSignalLongSymbol" SG_ 1012 LS_lightRightRampedChannel3Reque "LS_lightRightRampedChannel3Request";
BA_ "Confidence" SG_ 1012 LS_lightRightRampedChannel3Durat 0;
BA_ "SystemSignalLongSymbol" SG_ 1012 LS_lightRightRampedChannel3Durat "LS_lightRightRampedChannel3Duration";
BA_ "Confidence" SG_ 1012 LS_lightRightRampedChannel4Reque 0;
BA_ "SystemSignalLongSymbol" SG_ 1012 LS_lightRightRampedChannel4Reque "LS_lightRightRampedChannel4Request";
BA_ "Confidence" SG_ 1012 LS_lightRightRampedChannel4Durat 0;
BA_ "SystemSignalLongSymbol" SG_ 1012 LS_lightRightRampedChannel4Durat "LS_lightRightRampedChannel4Duration";
BA_ "Confidence" SG_ 1012 LS_lightRightRampedChannel5Reque 0;
BA_ "SystemSignalLongSymbol" SG_ 1012 LS_lightRightRampedChannel5Reque "LS_lightRightRampedChannel5Request";
BA_ "Confidence" SG_ 1012 LS_lightRightRampedChannel5Durat 0;
BA_ "SystemSignalLongSymbol" SG_ 1012 LS_lightRightRampedChannel5Durat "LS_lightRightRampedChannel5Duration";
BA_ "Confidence" SG_ 1012 LS_lightRightRampedChannel6Reque 0;
BA_ "SystemSignalLongSymbol" SG_ 1012 LS_lightRightRampedChannel6Reque "LS_lightRightRampedChannel6Request";
BA_ "Confidence" SG_ 1012 LS_lightRightRampedChannel6Durat 0;
BA_ "SystemSignalLongSymbol" SG_ 1012 LS_lightRightRampedChannel6Durat "LS_lightRightRampedChannel6Duration";
BA_ "Confidence" SG_ 1012 LS_lightRightRampedChannel7Reque 0;
BA_ "SystemSignalLongSymbol" SG_ 1012 LS_lightRightRampedChannel7Reque "LS_lightRightRampedChannel7Request";
BA_ "Confidence" SG_ 1012 LS_lightRightRampedChannel7Durat 0;
BA_ "SystemSignalLongSymbol" SG_ 1012 LS_lightRightRampedChannel7Durat "LS_lightRightRampedChannel7Duration";
BA_ "Confidence" SG_ 1012 LS_lightRearTurnLeftRequest 0;
BA_ "Confidence" SG_ 1012 LS_lightRearTurnRightRequest 0;
BA_ "Confidence" SG_ 1012 LS_lightSideRepeaterLeftRequest 0;
BA_ "Confidence" SG_ 1012 LS_lightSideRepeaterRightRequest 0;
BA_ "Confidence" SG_ 1012 LS_lightSideMarkerLeftRequest 0;
BA_ "Confidence" SG_ 1012 LS_lightSideMarkerRightRequest 0;
BA_ "Confidence" SG_ 1012 LS_lightFrontFogLeftRequest 0;
BA_ "Confidence" SG_ 1012 LS_lightFrontFogRightRequest 0;
BA_ "Confidence" SG_ 1012 LS_lightRearFogRequest 0;
BA_ "Confidence" SG_ 1012 LS_lightBrakeRequest 0;
BA_ "Confidence" SG_ 1012 LS_lightTailLeftRequest 0;
BA_ "Confidence" SG_ 1012 LS_lightTailRightRequest 0;
BA_ "Confidence" SG_ 1012 LS_lightLicensePlateRequest 0;
BA_ "Confidence" SG_ 1012 LS_lightReverseRequest 0;
BA_ "Confidence" SG_ 1012 LS_lightAuxParkLeftRequest 0;
BA_ "Confidence" SG_ 1012 LS_lightAuxParkRightRequest 0;
BA_ "Confidence" SG_ 1012 LS_mirrorRequestLeft 0;
BA_ "Confidence" SG_ 1012 LS_mirrorRequestRight 0;
BA_ "Confidence" SG_ 1012 LS_liftgateRequest 0;
BA_ "Confidence" SG_ 1012 LS_windowRequestLF 0;
BA_ "Confidence" SG_ 1012 LS_windowRequestLR 0;
BA_ "Confidence" SG_ 1012 LS_windowRequestRF 0;
BA_ "Confidence" SG_ 1012 LS_windowRequestRR 0;
BA_ "Confidence" SG_ 1012 LS_presentingHandleRequestLF 0;
BA_ "Confidence" SG_ 1012 LS_presentingHandleRequestLR 0;
BA_ "Confidence" SG_ 1012 LS_presentingHandleRequestRF 0;
BA_ "Confidence" SG_ 1012 LS_presentingHandleRequestRR 0;
BA_ "Confidence" SG_ 1012 LS_powerFrontDoorRequestLeft 0;
BA_ "Confidence" SG_ 1012 LS_powerFrontDoorRequestRight 0;
BA_ "Confidence" SG_ 1012 LS_falconDoorRequestLeft 0;
BA_ "Confidence" SG_ 1012 LS_falconDoorRequestRight 0;
BA_ "Confidence" SG_ 1012 LS_chargePortRequest 0;
BA_ "GenSigSNA" SG_ 1012 LS_chargePortRequest "3";
BA_ "Confidence" SG_ 1012 LS_chargePortRaveRequest 0;
BA_ "Confidence" SG_ 1012 LS_suspensionRequest 0;
BA_ "GenSigSNA" SG_ 1012 LS_suspensionRequest "3";
BA_ "Confidence" SG_ 1012 LS_rgbIPFLRed 0;
BA_ "Confidence" SG_ 1012 LS_rgbIPFLGreen 0;
BA_ "Confidence" SG_ 1012 LS_rgbIPFLBlue 0;
BA_ "Confidence" SG_ 1012 LS_rgbIPFRRed 0;
BA_ "Confidence" SG_ 1012 LS_rgbIPFRGreen 0;
BA_ "Confidence" SG_ 1012 LS_rgbIPFRBlue 0;
BA_ "Confidence" SG_ 1012 LS_rgbDoorFLForeRed 0;
BA_ "Confidence" SG_ 1012 LS_rgbDoorFLForeGreen 0;
BA_ "Confidence" SG_ 1012 LS_rgbDoorFLForeBlue 0;
BA_ "Confidence" SG_ 1012 LS_rgbDoorFLAftRed 0;
BA_ "Confidence" SG_ 1012 LS_rgbDoorFLAftGreen 0;
BA_ "Confidence" SG_ 1012 LS_rgbDoorFLAftBlue 0;
BA_ "Confidence" SG_ 1012 LS_rgbDoorFRForeRed 0;
BA_ "Confidence" SG_ 1012 LS_rgbDoorFRForeGreen 0;
BA_ "Confidence" SG_ 1012 LS_rgbDoorFRForeBlue 0;
BA_ "Confidence" SG_ 1012 LS_rgbDoorFRAftRed 0;
BA_ "Confidence" SG_ 1012 LS_rgbDoorFRAftGreen 0;
BA_ "Confidence" SG_ 1012 LS_rgbDoorFRAftBlue 0;
BA_ "Confidence" SG_ 1012 LS_rgbDoorRLForeRed 0;
BA_ "Confidence" SG_ 1012 LS_rgbDoorRLForeGreen 0;
BA_ "Confidence" SG_ 1012 LS_rgbDoorRLForeBlue 0;
BA_ "Confidence" SG_ 1012 LS_rgbDoorRLAftRed 0;
BA_ "Confidence" SG_ 1012 LS_rgbDoorRLAftGreen 0;
BA_ "Confidence" SG_ 1012 LS_rgbDoorRLAftBlue 0;
BA_ "Confidence" SG_ 1012 LS_rgbDoorRRForeRed 0;
BA_ "Confidence" SG_ 1012 LS_rgbDoorRRForeGreen 0;
BA_ "Confidence" SG_ 1012 LS_rgbDoorRRForeBlue 0;
BA_ "Confidence" SG_ 1012 LS_rgbDoorRRAftRed 0;
BA_ "Confidence" SG_ 1012 LS_rgbDoorRRAftGreen 0;
BA_ "Confidence" SG_ 1012 LS_rgbDoorRRAftBlue 0;
BA_ "Confidence" SG_ 1012 LS_frontMatrix0 0;
BA_ "Confidence" SG_ 1012 LS_frontMatrix1 0;
BA_ "Confidence" SG_ 1012 LS_frontMatrix2 0;
BA_ "Confidence" SG_ 1012 LS_frontMatrix3 0;
BA_ "Confidence" SG_ 1012 LS_frontMatrix4 0;
BA_ "Confidence" SG_ 1012 LS_frontMatrix5 0;
BA_ "Confidence" SG_ 1012 LS_frontMatrix6 0;
BA_ "Confidence" SG_ 1012 LS_frontMatrix7 0;
BA_ "Confidence" SG_ 1012 LS_frontMatrix8 0;
BA_ "Confidence" SG_ 1012 LS_frontMatrix9 0;
BA_ "Confidence" SG_ 1012 LS_frontMatrix10 0;
BA_ "Confidence" SG_ 1012 LS_frontMatrix11 0;
BA_ "Confidence" SG_ 1012 LS_frontMatrix12 0;
BA_ "Confidence" SG_ 1012 LS_frontMatrix13 0;
BA_ "Confidence" SG_ 1012 LS_frontMatrix14 0;
BA_ "Confidence" SG_ 1012 LS_frontMatrix15 0;
BA_ "Confidence" SG_ 1012 LS_frontMatrix16 0;
BA_ "Confidence" SG_ 1012 LS_frontMatrix17 0;
BA_ "Confidence" SG_ 1012 LS_frontMatrix18 0;
BA_ "Confidence" SG_ 1012 LS_frontMatrix19 0;
BA_ "Confidence" SG_ 1012 LS_frontMatrix20 0;
BA_ "Confidence" SG_ 1012 LS_frontMatrix21 0;
BA_ "Confidence" SG_ 1012 LS_frontMatrix22 0;
BA_ "Confidence" SG_ 1012 LS_frontMatrix23 0;
BA_ "Confidence" SG_ 1012 LS_frontMatrix24 0;
BA_ "Confidence" SG_ 1012 LS_frontMatrix25 0;
BA_ "Confidence" SG_ 1012 LS_frontMatrix26 0;
BA_ "Confidence" SG_ 1012 LS_frontMatrix27 0;
BA_ "Confidence" SG_ 1012 LS_frontMatrix28 0;
BA_ "Confidence" SG_ 1012 LS_frontMatrix29 0;
BA_ "Confidence" SG_ 1012 LS_frontMatrix30 0;
BA_ "Confidence" SG_ 1012 LS_frontMatrix31 0;
BA_ "Confidence" SG_ 1012 LS_frontMatrix32 0;
BA_ "Confidence" SG_ 1012 LS_frontMatrix33 0;
BA_ "Confidence" SG_ 1012 LS_frontMatrix34 0;
BA_ "Confidence" SG_ 1012 LS_frontMatrix35 0;
BA_ "Confidence" SG_ 1012 LS_frontMatrix36 0;
BA_ "Confidence" SG_ 1012 LS_frontMatrix37 0;
BA_ "Confidence" SG_ 1012 LS_frontMatrix38 0;
BA_ "Confidence" SG_ 1012 LS_frontMatrix39 0;
BA_ "Confidence" SG_ 1012 LS_frontMatrix40 0;
BA_ "Confidence" SG_ 1012 LS_frontMatrix41 0;
BA_ "Confidence" SG_ 1012 LS_frontMatrix42 0;
BA_ "Confidence" SG_ 1012 LS_frontMatrix43 0;
BA_ "Confidence" SG_ 1012 LS_frontMatrix44 0;
BA_ "Confidence" SG_ 1012 LS_frontMatrix45 0;
BA_ "Confidence" SG_ 1012 LS_frontMatrix46 0;
BA_ "Confidence" SG_ 1012 LS_frontMatrix47 0;
BA_ "Confidence" SG_ 1012 LS_frontMatrix48 0;
BA_ "Confidence" SG_ 1012 LS_frontMatrix49 0;
BA_ "Confidence" SG_ 1012 LS_frontMatrix50 0;
BA_ "Confidence" SG_ 1012 LS_frontMatrix51 0;
BA_ "Confidence" SG_ 1012 LS_frontMatrix52 0;
BA_ "Confidence" SG_ 1012 LS_frontMatrix53 0;
BA_ "Confidence" SG_ 1012 LS_frontMatrix54 0;
BA_ "Confidence" SG_ 1012 LS_frontMatrix55 0;
BA_ "Confidence" SG_ 1012 LS_frontMatrix56 0;
BA_ "Confidence" SG_ 1012 LS_frontMatrix57 0;
BA_ "Confidence" SG_ 1012 LS_frontMatrix58 0;
BA_ "Confidence" SG_ 1012 LS_frontMatrix59 0;
BA_ "Confidence" SG_ 1012 LS_rearMatrix0 0;
BA_ "Confidence" SG_ 1012 LS_rearMatrix1 0;
BA_ "Confidence" SG_ 1012 LS_rearMatrix2 0;
BA_ "Confidence" SG_ 1012 LS_rearMatrix3 0;
BA_ "Confidence" SG_ 1012 LS_rearMatrix4 0;
BA_ "Confidence" SG_ 1012 LS_rearMatrix5 0;
BA_ "Confidence" SG_ 1012 LS_rearMatrix6 0;
BA_ "Confidence" SG_ 1012 LS_rearMatrix7 0;
BA_ "Confidence" SG_ 1012 LS_rearMatrix8 0;
BA_ "Confidence" SG_ 1012 LS_rearMatrix9 0;
BA_ "Confidence" SG_ 1012 LS_rearMatrix10 0;
BA_ "Confidence" SG_ 1012 LS_rearMatrix11 0;
BA_ "Confidence" SG_ 1012 LS_rearMatrix12 0;
BA_ "Confidence" SG_ 1012 LS_rearMatrix13 0;
BA_ "Confidence" SG_ 1012 LS_rearMatrix14 0;
BA_ "Confidence" SG_ 1012 LS_rearMatrix15 0;
BA_ "Confidence" SG_ 1012 LS_rearMatrix16 0;
BA_ "Confidence" SG_ 1012 LS_rearMatrix17 0;
BA_ "Confidence" SG_ 1012 LS_rearMatrix18 0;
BA_ "Confidence" SG_ 1012 LS_rearMatrix19 0;
BA_ "Confidence" SG_ 1012 LS_rearMatrix20 0;
BA_ "Confidence" SG_ 1012 LS_rearMatrix21 0;
BA_ "Confidence" SG_ 1012 LS_rearMatrix22 0;
BA_ "Confidence" SG_ 1012 LS_rearMatrix23 0;
BA_ "Confidence" SG_ 1012 LS_rearMatrix24 0;
BA_ "Confidence" SG_ 1012 LS_rearMatrix25 0;
BA_ "Confidence" SG_ 1012 LS_rearMatrix26 0;
BA_ "Confidence" SG_ 1012 LS_rearMatrix27 0;
BA_ "Confidence" SG_ 1012 LS_rearMatrix28 0;
BA_ "Confidence" SG_ 1012 LS_rearMatrix29 0;
BA_ "Confidence" SG_ 1012 LS_rearMatrix30 0;
BA_ "Confidence" SG_ 1012 LS_rearMatrix31 0;
BA_ "Confidence" SG_ 1012 LS_rearMatrix32 0;
BA_ "Confidence" SG_ 1012 LS_rearMatrix33 0;
BA_ "Confidence" SG_ 1012 LS_rearMatrix34 0;
BA_ "Confidence" SG_ 1012 LS_rearMatrix35 0;
BA_ "Confidence" SG_ 1012 LS_rearMatrix36 0;
BA_ "Confidence" SG_ 1012 LS_rearMatrix37 0;
BA_ "Confidence" SG_ 1012 LS_rearMatrix38 0;
BA_ "Confidence" SG_ 1012 LS_rearMatrix39 0;
BA_ "Confidence" SG_ 1012 LS_rearMatrix40 0;
BA_ "Confidence" SG_ 1012 LS_rearMatrix41 0;
BA_ "Confidence" SG_ 1012 LS_rearMatrix42 0;
BA_ "Confidence" SG_ 1012 LS_rearMatrix43 0;
BA_ "Confidence" SG_ 1012 LS_rearMatrix44 0;
BA_ "Confidence" SG_ 1012 LS_rearMatrix45 0;
BA_ "Confidence" SG_ 1012 LS_rearMatrix46 0;
BA_ "Confidence" SG_ 1012 LS_rearMatrix47 0;
BA_ "Confidence" SG_ 1012 LS_rearMatrix48 0;
BA_ "Confidence" SG_ 1012 LS_rearMatrix49 0;
BA_ "Confidence" SG_ 1012 LS_rearMatrix50 0;
BA_ "Confidence" SG_ 1012 LS_rearMatrix51 0;
BA_ "Confidence" SG_ 1012 LS_rearMatrix52 0;
BA_ "Confidence" SG_ 1012 LS_rearMatrix53 0;
BA_ "Confidence" SG_ 1012 LS_rearMatrix54 0;
BA_ "Confidence" SG_ 1012 LS_rearMatrix55 0;
BA_ "Confidence" SG_ 1012 LS_rearMatrix56 0;
BA_ "Confidence" SG_ 1012 LS_rearMatrix57 0;
BA_ "Confidence" SG_ 1012 LS_rearMatrix58 0;
BA_ "Confidence" SG_ 1012 LS_rearMatrix59 0;
BA_ "Confidence" SG_ 1012 LS_offroadLightBar0 0;
BA_ "Confidence" SG_ 1012 LS_offroadLightBar1 0;
BA_ "Confidence" SG_ 1012 LS_offroadLightBar2 0;
BA_ "Confidence" SG_ 1012 LS_offroadLightBar3 0;
BA_ "Confidence" SG_ 1012 LS_offroadLightBar4 0;
BA_ "Confidence" SG_ 1012 LS_offroadLightBar5 0;
BA_ "Confidence" SG_ 612 PCS_chgInputVoltage 0;
BA_ "Confidence" SG_ 612 PCS_chgLineCurrent 0;
BA_ "Confidence" SG_ 612 PCS_chgAcVoltagePresent 0;
BA_ "Confidence" SG_ 612 PCS_chgInputPower 0;
BA_ "Confidence" SG_ 612 PCS_chgAcCurrentLimit 0;
BA_ "Confidence" SG_ 692 PCS_dcdcLvBusVolt 0;
BA_ "Confidence" SG_ 692 PCS_dcdcHvBusVolt 0;
BA_ "Confidence" SG_ 692 PCS_dcdcLvOutputCurrent 0;
BA_ "Confidence" SG_ 964 PCS_infoIndex 1;
BA_ "Confidence" SG_ 964 PCS_buildType 0;
BA_ "Confidence" SG_ 964 PCS_buildConfigId 0;
BA_ "Confidence" SG_ 964 PCS_hardwareId 0;
BA_ "Confidence" SG_ 964 PCS_componentId 0;
BA_ "Confidence" SG_ 964 PCS_pcbaId 0;
BA_ "Confidence" SG_ 964 PCS_assemblyId 0;
BA_ "Confidence" SG_ 964 PCS_usageId 0;
BA_ "Confidence" SG_ 964 PCS_subUsageId 0;
BA_ "Confidence" SG_ 964 PCS_platformType 0;
BA_ "Confidence" SG_ 964 PCS_appCrc 0;
BA_ "Confidence" SG_ 964 PCS_cpu2AppCrc 0;
BA_ "Confidence" SG_ 964 PCS_appGitHash 0;
BA_ "Confidence" SG_ 964 PCS_bootGitHash 0;
BA_ "Confidence" SG_ 964 PCS_bootUdsProtoVersion 0;
BA_ "Confidence" SG_ 964 PCS_bootCrc 0;
BA_ "Confidence" SG_ 676 PCS_chgPhATemp 0;
BA_ "GenSigSNA" SG_ 676 PCS_chgPhATemp "1025";
BA_ "Confidence" SG_ 676 PCS_chgPhBTemp 0;
BA_ "GenSigSNA" SG_ 676 PCS_chgPhBTemp "1025";
BA_ "Confidence" SG_ 676 PCS_chgPhCTemp 0;
BA_ "GenSigSNA" SG_ 676 PCS_chgPhCTemp "1025";
BA_ "Confidence" SG_ 676 PCS_dcdcTemp 0;
BA_ "GenSigSNA" SG_ 676 PCS_dcdcTemp "1025";
BA_ "Confidence" SG_ 676 PCS_ambientTemp 0;
BA_ "GenSigSNA" SG_ 676 PCS_ambientTemp "1025";
BA_ "Confidence" SG_ 676 PCS_dcdcBusbarTemp 0;
BA_ "GenSigSNA" SG_ 676 PCS_dcdcBusbarTemp "511";
BA_ "Confidence" SG_ 790 PMF_infoIndex 1;
BA_ "Confidence" SG_ 790 PMF_buildType 0;
BA_ "Confidence" SG_ 790 PMF_buildConfigurationId 0;
BA_ "Confidence" SG_ 790 PMF_hardwareId 0;
BA_ "Confidence" SG_ 790 PMF_deviceFused 0;
BA_ "Confidence" SG_ 790 PMF_componentId 0;
BA_ "Confidence" SG_ 790 PMF_pcbaId 0;
BA_ "Confidence" SG_ 790 PMF_assemblyId 0;
BA_ "Confidence" SG_ 790 PMF_usageId 0;
BA_ "Confidence" SG_ 790 PMF_subUsageId 0;
BA_ "Confidence" SG_ 790 PMF_applicationCrc 0;
BA_ "Confidence" SG_ 790 PMF_appGitHash 0;
BA_ "Confidence" SG_ 790 PMF_bootGitHash 0;
BA_ "Confidence" SG_ 790 PMF_platformTyp 0;
BA_ "Confidence" SG_ 790 PMF_udsProtocolVersion 0;
BA_ "Confidence" SG_ 790 PMF_bootloaderCrc 0;
BA_ "Confidence" SG_ 1748 PMR_infoIndex 1;
BA_ "Confidence" SG_ 1748 PMR_buildType 0;
BA_ "Confidence" SG_ 1748 PMR_buildConfigurationId 0;
BA_ "Confidence" SG_ 1748 PMR_hardwareId 0;
BA_ "Confidence" SG_ 1748 PMR_deviceFused 0;
BA_ "Confidence" SG_ 1748 PMR_componentId 0;
BA_ "Confidence" SG_ 1748 PMR_pcbaId 0;
BA_ "Confidence" SG_ 1748 PMR_assemblyId 0;
BA_ "Confidence" SG_ 1748 PMR_usageId 0;
BA_ "Confidence" SG_ 1748 PMR_subUsageId 0;
BA_ "Confidence" SG_ 1748 PMR_applicationCrc 0;
BA_ "Confidence" SG_ 1748 PMR_appGitHash 0;
BA_ "Confidence" SG_ 1748 PMR_bootGitHash 0;
BA_ "Confidence" SG_ 1748 PMR_platformTyp 0;
BA_ "Confidence" SG_ 1748 PMR_udsProtocolVersion 0;
BA_ "Confidence" SG_ 1748 PMR_bootloaderCrc 0;
BA_ "Confidence" SG_ 1551 PM_infoIndex 1;
BA_ "Confidence" SG_ 1551 PM_buildType 0;
BA_ "Confidence" SG_ 1551 PM_buildConfigurationId 0;
BA_ "Confidence" SG_ 1551 PM_hardwareId 0;
BA_ "Confidence" SG_ 1551 PM_deviceFused 0;
BA_ "Confidence" SG_ 1551 PM_componentId 0;
BA_ "Confidence" SG_ 1551 PM_pcbaId 0;
BA_ "Confidence" SG_ 1551 PM_assemblyId 0;
BA_ "Confidence" SG_ 1551 PM_usageId 0;
BA_ "Confidence" SG_ 1551 PM_subUsageId 0;
BA_ "Confidence" SG_ 1551 PM_applicationCrc 0;
BA_ "Confidence" SG_ 1551 PM_bootGitHash 0;
BA_ "Confidence" SG_ 837 PTC_infoIndex 1;
BA_ "Confidence" SG_ 837 PTC_infoBuildType 0;
BA_ "Confidence" SG_ 837 PTC_infoBuildConfigId 0;
BA_ "Confidence" SG_ 837 PTC_infoHardwareId 0;
BA_ "Confidence" SG_ 837 PTC_infoComponentId 0;
BA_ "Confidence" SG_ 837 PTC_infoPcbaId 0;
BA_ "Confidence" SG_ 837 PTC_infoAssemblyId 0;
BA_ "GenSigSNA" SG_ 837 PTC_infoAssemblyId "255";
BA_ "Confidence" SG_ 837 PTC_infoUsageId 0;
BA_ "Confidence" SG_ 837 PTC_infoSubUsageId 0;
BA_ "Confidence" SG_ 837 PTC_infoPlatformType 0;
BA_ "Confidence" SG_ 837 PTC_infoAppCrc 0;
BA_ "Confidence" SG_ 837 PTC_infoBootUdsProtoVersion 0;
BA_ "Confidence" SG_ 837 PTC_infoBootCrc 0;
BA_ "Confidence" SG_ 647 PTC_leftTempIGBT 0;
BA_ "Confidence" SG_ 647 PTC_tempOCP 0;
BA_ "Confidence" SG_ 647 PTC_rightTempIGBT 0;
BA_ "Confidence" SG_ 647 PTC_tempPCB 0;
BA_ "Confidence" SG_ 647 PTC_voltageHV 0;
BA_ "Confidence" SG_ 647 PTC_leftCurrentHV 0;
BA_ "Confidence" SG_ 647 PTC_rightCurrentHV 0;
BA_ "Confidence" SG_ 816 SCCM_infoIndex 1;
BA_ "Confidence" SG_ 816 SCCM_infoBuildType 0;
BA_ "Confidence" SG_ 816 SCCM_infoBuildConfigId 0;
BA_ "Confidence" SG_ 816 SCCM_infoHardwareId 0;
BA_ "Confidence" SG_ 816 SCCM_infoComponentId 0;
BA_ "Confidence" SG_ 816 SCCM_infoPcbaId 0;
BA_ "Confidence" SG_ 816 SCCM_infoAssemblyId 0;
BA_ "Confidence" SG_ 816 SCCM_infoUsageId 0;
BA_ "Confidence" SG_ 816 SCCM_infoSubUsageId 0;
BA_ "Confidence" SG_ 816 SCCM_infoPlatformType 0;
BA_ "Confidence" SG_ 816 SCCM_infoBootSvnRev 0;
BA_ "Confidence" SG_ 816 SCCM_infoBootSvnUrlHash 0;
BA_ "Confidence" SG_ 816 SCCM_infoSubcomponent1Version 0;
BA_ "Confidence" SG_ 816 SCCM_infoAppSvnHash 0;
BA_ "Confidence" SG_ 816 SCCM_infoBootSvnHash 0;
BA_ "Confidence" SG_ 816 SCCM_infoUdsProtoVersion 0;
BA_ "Confidence" SG_ 816 SCCM_infoBootCrc 0;
BA_ "Confidence" SG_ 585 SCCM_leftStalkCrc 0;
BA_ "Confidence" SG_ 585 SCCM_leftStalkCounter 0;
BA_ "Confidence" SG_ 585 SCCM_highBeamStalkStatus 0;
BA_ "GenSigSNA" SG_ 585 SCCM_highBeamStalkStatus "3";
BA_ "Confidence" SG_ 585 SCCM_washWipeButtonStatus 0;
BA_ "GenSigSNA" SG_ 585 SCCM_washWipeButtonStatus "3";
BA_ "Confidence" SG_ 585 SCCM_turnIndicatorStalkStatus 0;
BA_ "GenSigSNA" SG_ 585 SCCM_turnIndicatorStalkStatus "9";
BA_ "Confidence" SG_ 585 SCCM_turnIndicatorStalkAngle 0;
BA_ "GenSigSNA" SG_ 585 SCCM_turnIndicatorStalkAngle "4095";
BA_ "Confidence" SG_ 553 SCCM_rightStalkCrc 0;
BA_ "Confidence" SG_ 553 SCCM_rightStalkCounter 0;
BA_ "Confidence" SG_ 553 SCCM_rightStalkStatus 0;
BA_ "GenSigSNA" SG_ 553 SCCM_rightStalkStatus "6";
BA_ "Confidence" SG_ 553 SCCM_rightStalkReserved1 0;
BA_ "Confidence" SG_ 553 SCCM_parkButtonStatus 0;
BA_ "GenSigSNA" SG_ 553 SCCM_parkButtonStatus "3";
BA_ "Confidence" SG_ 553 SCCM_rightStalkReserved2 0;
BA_ "Confidence" SG_ 297 SCCM_steeringAngleCrc 0;
BA_ "Confidence" SG_ 297 SCCM_steeringAngleCounter 0;
BA_ "Confidence" SG_ 297 SCCM_supplierID 0;
BA_ "Confidence" SG_ 297 SCCM_steeringAngleSensorStatus 0;
BA_ "Confidence" SG_ 297 SCCM_steeringAngle 0;
BA_ "GenSigSNA" SG_ 297 SCCM_steeringAngle "16383";
BA_ "Confidence" SG_ 297 SCCM_steeringAngleValidity 0;
BA_ "GenSigSNA" SG_ 297 SCCM_steeringAngleValidity "3";
BA_ "Confidence" SG_ 297 SCCM_steeringAngleSpeed 0;
BA_ "Confidence" SG_ 297 SCCM_steeringAngleSensorReservd1 0;
BA_ "Confidence" SG_ 297 SCCM_steeringAngleSensorReservd2 0;
BA_ "Confidence" SG_ 297 SCCM_steeringAngleSensorReservd3 0;
BA_ "Confidence" SG_ 1597 SDCR_infoIndex 1;
BA_ "Confidence" SG_ 1597 SDCR_infoBuildType 1;
BA_ "Confidence" SG_ 1597 SDCR_infoBuildConfigId 0;
BA_ "Confidence" SG_ 1597 SDCR_infoHardwareId 0;
BA_ "Confidence" SG_ 1597 SDCR_infoSubUsageId 0;
BA_ "Confidence" SG_ 1597 SDCR_infoBootGitHash 0;
BA_ "Confidence" SG_ 523 TAS_axleIndex 1;
BA_ "Confidence" SG_ 523 TAS_rawHeightFL 0;
BA_ "GenSigSNA" SG_ 523 TAS_rawHeightFL "1023";
BA_ "Confidence" SG_ 523 TAS_staticHeightEstimateFL 0;
BA_ "GenSigSNA" SG_ 523 TAS_staticHeightEstimateFL "1023";
BA_ "Confidence" SG_ 523 TAS_componentPressureFL 0;
BA_ "GenSigSNA" SG_ 523 TAS_componentPressureFL "255";
BA_ "Confidence" SG_ 523 TAS_rawHeightFR 0;
BA_ "GenSigSNA" SG_ 523 TAS_rawHeightFR "1023";
BA_ "Confidence" SG_ 523 TAS_staticHeightEstimateFR 0;
BA_ "GenSigSNA" SG_ 523 TAS_staticHeightEstimateFR "1023";
BA_ "Confidence" SG_ 523 TAS_componentPressureFR 0;
BA_ "GenSigSNA" SG_ 523 TAS_componentPressureFR "255";
BA_ "Confidence" SG_ 523 TAS_rawHeightRL 0;
BA_ "GenSigSNA" SG_ 523 TAS_rawHeightRL "1023";
BA_ "Confidence" SG_ 523 TAS_staticHeightEstimateRL 0;
BA_ "GenSigSNA" SG_ 523 TAS_staticHeightEstimateRL "1023";
BA_ "Confidence" SG_ 523 TAS_componentPressureRL 0;
BA_ "GenSigSNA" SG_ 523 TAS_componentPressureRL "255";
BA_ "Confidence" SG_ 523 TAS_rawHeightRR 0;
BA_ "GenSigSNA" SG_ 523 TAS_rawHeightRR "1023";
BA_ "Confidence" SG_ 523 TAS_staticHeightEstimateRR 0;
BA_ "GenSigSNA" SG_ 523 TAS_staticHeightEstimateRR "1023";
BA_ "Confidence" SG_ 523 TAS_componentPressureRR 0;
BA_ "GenSigSNA" SG_ 523 TAS_componentPressureRR "255";
BA_ "Confidence" SG_ 1398 TAS_endstopState 0;
BA_ "Confidence" SG_ 1398 TAS_continuousControlState 0;
BA_ "Confidence" SG_ 1398 TAS_activeTireTune 0;
BA_ "Confidence" SG_ 1398 TAS_roughnessRaiseReason 0;
BA_ "Confidence" SG_ 1398 TAS_frontMetricDrivesRear 0;
BA_ "Confidence" SG_ 1398 TAS_roadCondition 0;
BA_ "GenSigSNA" SG_ 1398 TAS_roadCondition "255";
BA_ "Confidence" SG_ 1398 TAS_bellyProtect 0;
BA_ "Confidence" SG_ 1398 TAS_frontMetricDrivesFront 0;
BA_ "Confidence" SG_ 1398 TAS_speedBumpAxleFront 0;
BA_ "Confidence" SG_ 1398 TAS_speedBumpAxleRear 0;
BA_ "Confidence" SG_ 1398 TAS_holeProtectFL 0;
BA_ "Confidence" SG_ 1398 TAS_holeProtectFR 0;
BA_ "Confidence" SG_ 1398 TAS_holeProtectRL 0;
BA_ "Confidence" SG_ 1398 TAS_holeProtectRR 0;
BA_ "Confidence" SG_ 1398 TAS_stepProtectFL 0;
BA_ "Confidence" SG_ 1398 TAS_stepProtectFR 0;
BA_ "Confidence" SG_ 1398 TAS_stepProtectRL 0;
BA_ "Confidence" SG_ 1398 TAS_stepProtectRR 0;
BA_ "Confidence" SG_ 1398 TAS_FDUTorqueCorruptionScale 0;
BA_ "GenSigSNA" SG_ 1398 TAS_FDUTorqueCorruptionScale "15";
BA_ "Confidence" SG_ 1398 TAS_sprungMassEstimate 0;
BA_ "GenSigSNA" SG_ 1398 TAS_sprungMassEstimate "31";
BA_ "Confidence" SG_ 1398 TAS_anyDamperActive 0;
BA_ "Confidence" SG_ 1398 TAS_dampingStatesCounter 0;
BA_ "Confidence" SG_ 1398 TAS_dampingStatesChecksum 0;
BA_ "Confidence" SG_ 1357 TAS_infoIndex 1;
BA_ "Confidence" SG_ 1357 TAS_infoBuildType 0;
BA_ "Confidence" SG_ 1357 TAS_infoBuildConfigId 0;
BA_ "Confidence" SG_ 1357 TAS_infoHardwareId 0;
BA_ "Confidence" SG_ 1357 TAS_infoComponentId 0;
BA_ "Confidence" SG_ 1357 TAS_infoPcbaId 0;
BA_ "Confidence" SG_ 1357 TAS_infoAssemblyId 0;
BA_ "GenSigSNA" SG_ 1357 TAS_infoAssemblyId "255";
BA_ "Confidence" SG_ 1357 TAS_infoUsageId 0;
BA_ "Confidence" SG_ 1357 TAS_infoSubUsageId 0;
BA_ "Confidence" SG_ 1357 TAS_infoAppCrc 0;
BA_ "Confidence" SG_ 1357 TAS_infoAppGitHash 0;
BA_ "Confidence" SG_ 1357 TAS_infoBootGitHash 0;
BA_ "Confidence" SG_ 1357 TAS_infoPlatformType 0;
BA_ "Confidence" SG_ 1357 TAS_infoMajorVersion 0;
BA_ "GenSigSNA" SG_ 1357 TAS_infoMajorVersion "255";
BA_ "Confidence" SG_ 1357 TAS_infoBranchOrigin 0;
BA_ "GenSigSNA" SG_ 1357 TAS_infoBranchOrigin "255";
BA_ "Confidence" SG_ 1357 TAS_infoMaturity 0;
BA_ "GenSigSNA" SG_ 1357 TAS_infoMaturity "255";
BA_ "Confidence" SG_ 1357 TAS_infoHardwareRevision 0;
BA_ "GenSigSNA" SG_ 1357 TAS_infoHardwareRevision "255";
BA_ "Confidence" SG_ 525 TAS_levelingState 0;
BA_ "Confidence" SG_ 525 TAS_levelingItem 0;
BA_ "Confidence" SG_ 525 TAS_pressureGallery 0;
BA_ "GenSigSNA" SG_ 525 TAS_pressureGallery "255";
BA_ "Confidence" SG_ 525 TAS_pressureReservoir 0;
BA_ "GenSigSNA" SG_ 525 TAS_pressureReservoir "255";
BA_ "Confidence" SG_ 525 TAS_runMode 0;
BA_ "Confidence" SG_ 525 TAS_filterMode 0;
BA_ "Confidence" SG_ 525 TAS_compressorRun 0;
BA_ "Confidence" SG_ 525 TAS_twistDetected 0;
BA_ "Confidence" SG_ 525 TAS_leanDetected 0;
BA_ "Confidence" SG_ 525 TAS_limpHomeMode 0;
BA_ "Confidence" SG_ 525 TAS_targetLevel 0;
BA_ "Confidence" SG_ 525 TAS_currentLevel 0;
BA_ "Confidence" SG_ 525 TAS_jackMode 0;
BA_ "Confidence" SG_ 525 TAS_reduceVehicleSpeedRequest 0;
BA_ "Confidence" SG_ 525 TAS_statesCounter 0;
BA_ "Confidence" SG_ 525 TAS_statesChecksum 0;
BA_ "Confidence" SG_ 409 TAS_adaptiveActivityFL_C 0;
BA_ "GenSigSNA" SG_ 409 TAS_adaptiveActivityFL_C "31";
BA_ "Confidence" SG_ 409 TAS_adaptiveActivityFL_R 0;
BA_ "GenSigSNA" SG_ 409 TAS_adaptiveActivityFL_R "31";
BA_ "Confidence" SG_ 409 TAS_adaptiveActivityFR_C 0;
BA_ "GenSigSNA" SG_ 409 TAS_adaptiveActivityFR_C "31";
BA_ "Confidence" SG_ 409 TAS_adaptiveActivityFR_R 0;
BA_ "GenSigSNA" SG_ 409 TAS_adaptiveActivityFR_R "31";
BA_ "Confidence" SG_ 409 TAS_adaptiveActivityRL_C 0;
BA_ "GenSigSNA" SG_ 409 TAS_adaptiveActivityRL_C "31";
BA_ "Confidence" SG_ 409 TAS_adaptiveActivityRL_R 0;
BA_ "GenSigSNA" SG_ 409 TAS_adaptiveActivityRL_R "31";
BA_ "Confidence" SG_ 409 TAS_adaptiveActivityRR_C 0;
BA_ "GenSigSNA" SG_ 409 TAS_adaptiveActivityRR_C "31";
BA_ "Confidence" SG_ 409 TAS_adaptiveActivityRR_R 0;
BA_ "GenSigSNA" SG_ 409 TAS_adaptiveActivityRR_R "31";
BA_ "Confidence" SG_ 409 TAS_uiHeightFL 0;
BA_ "GenSigSNA" SG_ 409 TAS_uiHeightFL "63";
BA_ "Confidence" SG_ 409 TAS_uiHeightFR 0;
BA_ "GenSigSNA" SG_ 409 TAS_uiHeightFR "63";
BA_ "Confidence" SG_ 409 TAS_uiHeightRL 0;
BA_ "GenSigSNA" SG_ 409 TAS_uiHeightRL "63";
BA_ "Confidence" SG_ 409 TAS_uiHeightRR 0;
BA_ "GenSigSNA" SG_ 409 TAS_uiHeightRR "63";
BA_ "Confidence" SG_ 410 TAS_bodyAccelFL 0;
BA_ "GenSigSNA" SG_ 410 TAS_bodyAccelFL "255";
BA_ "Confidence" SG_ 410 TAS_bodyAccelFR 0;
BA_ "GenSigSNA" SG_ 410 TAS_bodyAccelFR "255";
BA_ "Confidence" SG_ 410 TAS_bodyAccelRL 0;
BA_ "GenSigSNA" SG_ 410 TAS_bodyAccelRL "255";
BA_ "Confidence" SG_ 410 TAS_bodyAccelRR 0;
BA_ "GenSigSNA" SG_ 410 TAS_bodyAccelRR "255";
BA_ "Confidence" SG_ 538 TAS_yellowWarningLamp 0;
BA_ "Confidence" SG_ 538 TAS_redWarningLamp 0;
BA_ "Confidence" SG_ 538 TAS_veryLowAllowed 0;
BA_ "Confidence" SG_ 538 TAS_lowAllowed 0;
BA_ "Confidence" SG_ 538 TAS_standardAllowed 0;
BA_ "Confidence" SG_ 538 TAS_highAllowed 0;
BA_ "Confidence" SG_ 538 TAS_veryHighAllowed 0;
BA_ "Confidence" SG_ 538 TAS_extractAllowed 0;
BA_ "Confidence" SG_ 538 TAS_showSpinner 0;
BA_ "Confidence" SG_ 538 TAS_adaptiveRideModeOverride 0;
BA_ "GenSigSNA" SG_ 538 TAS_adaptiveRideModeOverride "3";
BA_ "Confidence" SG_ 538 TAS_levelSelectEnabled 0;
BA_ "Confidence" SG_ 538 TAS_jackModeToggleEnabled 0;
BA_ "Confidence" SG_ 538 TAS_adaptiveRideSelectEnabled 0;
BA_ "Confidence" SG_ 538 TAS_launchModeState 0;
BA_ "Confidence" SG_ 538 TAS_restrictUpLevelingFalcons 0;
BA_ "Confidence" SG_ 538 TAS_restrictUpLevelingTrunk 0;
BA_ "Confidence" SG_ 538 TAS_restrictDownLevelingDoors 0;
BA_ "Confidence" SG_ 538 TAS_restrictLevelingChargeCable 0;
BA_ "Confidence" SG_ 538 TAS_restrictLevelingSystemCheck 0;
BA_ "Confidence" SG_ 538 TAS_restrictLevelingTransport 0;
BA_ "Confidence" SG_ 538 TAS_restrictLevelingShowroom 0;
BA_ "Confidence" SG_ 538 TAS_uiControlCounter 0;
BA_ "Confidence" SG_ 538 TAS_uiControlChecksum 0;
BA_ "Confidence" SG_ 659 UI_steeringTuneRequest 0;
BA_ "Confidence" SG_ 659 UI_tractionControlMode 0;
BA_ "Confidence" SG_ 659 UI_parkBrakeRequest 0;
BA_ "GenSigSNA" SG_ 659 UI_parkBrakeRequest "3";
BA_ "Confidence" SG_ 659 UI_winchModeRequest 0;
BA_ "Confidence" SG_ 659 UI_trailerMode 0;
BA_ "Confidence" SG_ 659 UI_accOvertakeEnable 0;
BA_ "GenSigSNA" SG_ 659 UI_accOvertakeEnable "3";
BA_ "Confidence" SG_ 659 UI_aebEnable 0;
BA_ "GenSigSNA" SG_ 659 UI_aebEnable "3";
BA_ "Confidence" SG_ 659 UI_aesEnable 0;
BA_ "GenSigSNA" SG_ 659 UI_aesEnable "3";
BA_ "Confidence" SG_ 659 UI_ahlbEnable 0;
BA_ "GenSigSNA" SG_ 659 UI_ahlbEnable "3";
BA_ "Confidence" SG_ 659 UI_autoLaneChangeEnable 0;
BA_ "GenSigSNA" SG_ 659 UI_autoLaneChangeEnable "3";
BA_ "Confidence" SG_ 659 UI_winchProxUserOverride 0;
BA_ "Confidence" SG_ 659 UI_autoParkRequest 0;
BA_ "GenSigSNA" SG_ 659 UI_autoParkRequest "15";
BA_ "Confidence" SG_ 659 UI_bsdEnable 0;
BA_ "GenSigSNA" SG_ 659 UI_bsdEnable "3";
BA_ "Confidence" SG_ 659 UI_fcwEnable 0;
BA_ "GenSigSNA" SG_ 659 UI_fcwEnable "3";
BA_ "Confidence" SG_ 659 UI_fcwSensitivity 0;
BA_ "GenSigSNA" SG_ 659 UI_fcwSensitivity "3";
BA_ "Confidence" SG_ 659 UI_latControlEnable 0;
BA_ "GenSigSNA" SG_ 659 UI_latControlEnable "3";
BA_ "Confidence" SG_ 659 UI_ldwEnable 0;
BA_ "GenSigSNA" SG_ 659 UI_ldwEnable "3";
BA_ "Confidence" SG_ 568 UI_roadClass 0;
BA_ "GenSigSNA" SG_ 568 UI_roadClass "0";
BA_ "Confidence" SG_ 568 UI_navRouteActive 0;
BA_ "Confidence" SG_ 568 UI_parallelAutoparkEnabled 0;
BA_ "Confidence" SG_ 568 UI_perpendicularAutoparkEnabled 0;
BA_ "Confidence" SG_ 568 UI_controlledAccess 0;
BA_ "Confidence" SG_ 568 UI_autosteerRestricted 0;
BA_ "Confidence" SG_ 651 UI_driverProfileIndex 0;
BA_ "Confidence" SG_ 651 UI_driverProfileSelectionType 0;
BA_ "Confidence" SG_ 651 UI_driverProfilePositionAdjusted 0;
BA_ "Confidence" SG_ 651 UI_activeKeyRequested 0;
BA_ "Confidence" SG_ 883 UI_mapSpeedLimitUnits 0;
BA_ "Confidence" SG_ 883 UI_mppSpeedLimit 0;
BA_ "Confidence" SG_ 883 UI_gpsNmeaMIA 0;
BA_ "Confidence" SG_ 883 UI_gpsAntennaDisconnected 0;
BA_ "Confidence" SG_ 883 UI_conditionalLimitActive 0;
BA_ "Confidence" SG_ 883 UI_conditionalSpeedLimit 0;
BA_ "GenSigSNA" SG_ 883 UI_conditionalSpeedLimit "31";
BA_ "Confidence" SG_ 755 UI_hvacReqTempSetpointLeft 0;
BA_ "Confidence" SG_ 755 UI_hvacReqAutoBlowerLevel 0;
BA_ "Confidence" SG_ 755 UI_hvacReqTempSetpointRight 0;
BA_ "Confidence" SG_ 755 UI_hvacReqAirDistributionMode 0;
BA_ "Confidence" SG_ 755 UI_hvacReqBlowerSegment 0;
BA_ "Confidence" SG_ 755 UI_hvacReqRecirc 0;
BA_ "Confidence" SG_ 755 UI_hvacReqACDisable 0;
BA_ "Confidence" SG_ 755 UI_hvacDefogState 0;
BA_ "Confidence" SG_ 755 UI_hvacReqUserPowerState 0;
BA_ "Confidence" SG_ 755 UI_hvacReqSecondRowState 0;
BA_ "Confidence" SG_ 755 UI_hvacReqKeepClimateOn 0;
BA_ "Confidence" SG_ 755 UI_hvacReqBioWeaponDefMode 0;
BA_ "Confidence" SG_ 755 UI_hvacReqTempSetpointCOP 0;
BA_ "Confidence" SG_ 1523 UI_odometer 0;
BA_ "GenSigSNA" SG_ 1523 UI_odometer "16777215";
BA_ "Confidence" SG_ 948 UI_usbFrontHubPowerStateRequest 0;
BA_ "GenSigSNA" SG_ 948 UI_usbFrontHubPowerStateRequest "0";
BA_ "Confidence" SG_ 827 UI_idlePowerConsumption 0;
BA_ "Confidence" SG_ 827 UI_chargeTimeUntilTerminationPct 0;
BA_ "GenSigSNA" SG_ 827 UI_chargeTimeUntilTerminationPct "2047";
BA_ "Confidence" SG_ 827 UI_chargeTimeUntilReadyToDepart 0;
BA_ "GenSigSNA" SG_ 827 UI_chargeTimeUntilReadyToDepart "2047";
BA_ "Confidence" SG_ 826 UI_ratedRange 0;
BA_ "Confidence" SG_ 826 UI_soe 0;
BA_ "Confidence" SG_ 826 UI_uSoe 0;
BA_ "Confidence" SG_ 723 UI_isSunUp 0;
BA_ "GenSigSNA" SG_ 723 UI_isSunUp "3";
BA_ "Confidence" SG_ 723 UI_solarElevationAngle 0;
BA_ "GenSigSNA" SG_ 723 UI_solarElevationAngle "127";
BA_ "Confidence" SG_ 723 UI_screenPCBTemperature 0;
BA_ "Confidence" SG_ 723 UI_minsToSunset 0;
BA_ "Confidence" SG_ 723 UI_minsToSunrise 0;
BA_ "Confidence" SG_ 851 UI_touchActive 0;
BA_ "Confidence" SG_ 851 UI_audioActive 0;
BA_ "Confidence" SG_ 851 UI_cellActive 0;
BA_ "Confidence" SG_ 851 UI_displayReady 0;
BA_ "Confidence" SG_ 851 UI_displayOn 0;
BA_ "Confidence" SG_ 851 UI_wifiActive 0;
BA_ "Confidence" SG_ 851 UI_wifiConnected 0;
BA_ "Confidence" SG_ 851 UI_readyForDrive 0;
BA_ "Confidence" SG_ 851 UI_cellConnected 0;
BA_ "Confidence" SG_ 851 UI_vpnActive 0;
BA_ "Confidence" SG_ 851 UI_factoryReset 0;
BA_ "GenSigSNA" SG_ 851 UI_factoryReset "0";
BA_ "Confidence" SG_ 851 UI_gpsActive 0;
BA_ "Confidence" SG_ 851 UI_cellNetworkTechnology 0;
BA_ "GenSigSNA" SG_ 851 UI_cellNetworkTechnology "15";
BA_ "Confidence" SG_ 851 UI_falseTouchCounter 0;
BA_ "Confidence" SG_ 851 UI_cellSignalBars 0;
BA_ "GenSigSNA" SG_ 851 UI_cellSignalBars "7";
BA_ "Confidence" SG_ 851 UI_trailerModeTelltale 0;
BA_ "Confidence" SG_ 851 UI_pcbTemperature 0;
BA_ "Confidence" SG_ 851 UI_cpuTemperature 0;
BA_ "Confidence" SG_ 663 UI_adaptiveRideRequest 0;
BA_ "Confidence" SG_ 663 UI_geofenceLevelingRequest 0;
BA_ "GenSigSNA" SG_ 663 UI_geofenceLevelingRequest "5";
BA_ "Confidence" SG_ 627 UI_powerStateRequest 0;
BA_ "Confidence" SG_ 627 UI_childDoorLockOnRight 0;
BA_ "Confidence" SG_ 627 UI_frontFogSwitch 0;
BA_ "Confidence" SG_ 627 UI_summonActive 0;
BA_ "Confidence" SG_ 627 UI_frunkRequest 0;
BA_ "Confidence" SG_ 627 UI_wiperMode 0;
BA_ "GenSigSNA" SG_ 627 UI_wiperMode "0";
BA_ "Confidence" SG_ 627 UI_steeringButtonMode 0;
BA_ "Confidence" SG_ 627 UI_walkUpUnlock 0;
BA_ "Confidence" SG_ 627 UI_walkAwayLock 0;
BA_ "Confidence" SG_ 627 UI_unlockOnPark 0;
BA_ "Confidence" SG_ 627 UI_globalUnlockOn 0;
BA_ "Confidence" SG_ 627 UI_childDoorLockOnLeft 0;
BA_ "Confidence" SG_ 627 UI_lockRequest 0;
BA_ "GenSigSNA" SG_ 627 UI_lockRequest "7";
BA_ "Confidence" SG_ 627 UI_alarmEnabled 0;
BA_ "Confidence" SG_ 627 UI_stop12vSupport 0;
BA_ "Confidence" SG_ 627 UI_rearFogSwitch 0;
BA_ "Confidence" SG_ 627 UI_mirrorFoldRequest 0;
BA_ "GenSigSNA" SG_ 627 UI_mirrorFoldRequest "3";
BA_ "Confidence" SG_ 627 UI_mirrorHeatRequest 0;
BA_ "Confidence" SG_ 627 UI_remoteStartRequest 0;
BA_ "GenSigSNA" SG_ 627 UI_remoteStartRequest "4";
BA_ "Confidence" SG_ 627 UI_seeYouHomeLightingOn 0;
BA_ "Confidence" SG_ 627 UI_powerOff 0;
BA_ "Confidence" SG_ 627 UI_displayBrightnessLevel 0;
BA_ "GenSigSNA" SG_ 627 UI_displayBrightnessLevel "255";
BA_ "Confidence" SG_ 627 UI_autoHighBeamEnabled 0;
BA_ "Confidence" SG_ 627 UI_frontLeftSeatHeatReq 0;
BA_ "Confidence" SG_ 627 UI_frontRightSeatHeatReq 0;
BA_ "Confidence" SG_ 627 UI_rearLeftSeatHeatReq 0;
BA_ "Confidence" SG_ 627 UI_rearCenterSeatHeatReq 0;
BA_ "Confidence" SG_ 627 UI_rearRightSeatHeatReq 0;
BA_ "Confidence" SG_ 627 UI_autoFoldMirrorsOn 0;
BA_ "Confidence" SG_ 627 UI_mirrorDipOnReverse 0;
BA_ "Confidence" SG_ 627 UI_remoteClosureRequest 0;
BA_ "GenSigSNA" SG_ 627 UI_remoteClosureRequest "3";
BA_ "Confidence" SG_ 627 UI_wiperRequest 0;
BA_ "GenSigSNA" SG_ 627 UI_wiperRequest "0";
BA_ "Confidence" SG_ 627 UI_domeLightSwitch 0;
BA_ "Confidence" SG_ 1285 SA_infoIndex 1;
BA_ "Confidence" SG_ 1285 SA_genealogyVersion 0;
BA_ "Confidence" SG_ 1285 SA_genealogyCrc 0;
BA_ "Confidence" SG_ 1285 SA_region 0;
BA_ "Confidence" SG_ 1285 SA_OverTempThreshold 0;
BA_ "Confidence" SG_ 1285 SA_partNumInt 0;
BA_ "Confidence" SG_ 1285 SA_partNumRev 0;
BA_ "Confidence" SG_ 1285 SA_currentLimit 0;
BA_ "Confidence" SG_ 1285 SA_l1Voltage 0;
VAL_ 1012 LS_lightShowIndex 24 "LightShowMux24" 23 "LightShowMux23" 22 "LightShowMux22" 21 "LightShowMux21" 20 "LightShowMux20" 19 "LightShowMux19" 18 "LightShowMux18" 17 "LightShowMux17" 16 "LightShowMux16" 15 "LightShowMux15" 14 "LightShowMux14" 13 "LightShowMux13" 12 "LightShowMux12" 11 "LightShowMux11" 10 "LightShowMux10" 9 "LightShowMux9" 8 "LightShowMux8" 7 "LightShowMux7" 6 "LightShowMux6" 5 "LightShowMux5" 4 "LightShowMux4" 3 "LightShowMux3" 2 "LightShowMux2" 1 "LightShowMux1" 0 "LightShowMux0" ;
VAL_ 1012 LS_lightLeftRampedChannel1Durati 3 "TWO_SECONDS" 2 "ONE_SECOND" 1 "HALF_SECOND" 0 "INSTANT" ;
VAL_ 1012 LS_lightLeftRampedChannel2Durati 3 "TWO_SECONDS" 2 "ONE_SECOND" 1 "HALF_SECOND" 0 "INSTANT" ;
VAL_ 1012 LS_lightLeftRampedChannel3Durati 3 "TWO_SECONDS" 2 "ONE_SECOND" 1 "HALF_SECOND" 0 "INSTANT" ;
VAL_ 1012 LS_lightLeftRampedChannel4Durati 3 "TWO_SECONDS" 2 "ONE_SECOND" 1 "HALF_SECOND" 0 "INSTANT" ;
VAL_ 1012 LS_lightLeftRampedChannel5Durati 3 "TWO_SECONDS" 2 "ONE_SECOND" 1 "HALF_SECOND" 0 "INSTANT" ;
VAL_ 1012 LS_lightLeftRampedChannel6Durati 3 "TWO_SECONDS" 2 "ONE_SECOND" 1 "HALF_SECOND" 0 "INSTANT" ;
VAL_ 1012 LS_lightLeftRampedChannel7Durati 3 "TWO_SECONDS" 2 "ONE_SECOND" 1 "HALF_SECOND" 0 "INSTANT" ;
VAL_ 1012 LS_lightRightRampedChannel1Durat 3 "TWO_SECONDS" 2 "ONE_SECOND" 1 "HALF_SECOND" 0 "INSTANT" ;
VAL_ 1012 LS_lightRightRampedChannel2Durat 3 "TWO_SECONDS" 2 "ONE_SECOND" 1 "HALF_SECOND" 0 "INSTANT" ;
VAL_ 1012 LS_lightRightRampedChannel3Durat 3 "TWO_SECONDS" 2 "ONE_SECOND" 1 "HALF_SECOND" 0 "INSTANT" ;
VAL_ 1012 LS_lightRightRampedChannel4Durat 3 "TWO_SECONDS" 2 "ONE_SECOND" 1 "HALF_SECOND" 0 "INSTANT" ;
VAL_ 1012 LS_lightRightRampedChannel5Durat 3 "TWO_SECONDS" 2 "ONE_SECOND" 1 "HALF_SECOND" 0 "INSTANT" ;
VAL_ 1012 LS_lightRightRampedChannel6Durat 3 "TWO_SECONDS" 2 "ONE_SECOND" 1 "HALF_SECOND" 0 "INSTANT" ;
VAL_ 1012 LS_lightRightRampedChannel7Durat 3 "TWO_SECONDS" 2 "ONE_SECOND" 1 "HALF_SECOND" 0 "INSTANT" ;
VAL_ 1012 LS_mirrorRequestLeft 4 "HOLIDAY_PARTY_STOP" 3 "HOLIDAY_PARTY_CLOSE" 2 "HOLIDAY_PARTY_DANCE" 1 "HOLIDAY_PARTY_OPEN" 0 "HOLIDAY_PARTY_IDLE" ;
VAL_ 1012 LS_mirrorRequestRight 4 "HOLIDAY_PARTY_STOP" 3 "HOLIDAY_PARTY_CLOSE" 2 "HOLIDAY_PARTY_DANCE" 1 "HOLIDAY_PARTY_OPEN" 0 "HOLIDAY_PARTY_IDLE" ;
VAL_ 1012 LS_liftgateRequest 4 "HOLIDAY_PARTY_STOP" 3 "HOLIDAY_PARTY_CLOSE" 2 "HOLIDAY_PARTY_DANCE" 1 "HOLIDAY_PARTY_OPEN" 0 "HOLIDAY_PARTY_IDLE" ;
VAL_ 1012 LS_windowRequestLF 4 "HOLIDAY_PARTY_STOP" 3 "HOLIDAY_PARTY_CLOSE" 2 "HOLIDAY_PARTY_DANCE" 1 "HOLIDAY_PARTY_OPEN" 0 "HOLIDAY_PARTY_IDLE" ;
VAL_ 1012 LS_windowRequestLR 4 "HOLIDAY_PARTY_STOP" 3 "HOLIDAY_PARTY_CLOSE" 2 "HOLIDAY_PARTY_DANCE" 1 "HOLIDAY_PARTY_OPEN" 0 "HOLIDAY_PARTY_IDLE" ;
VAL_ 1012 LS_windowRequestRF 4 "HOLIDAY_PARTY_STOP" 3 "HOLIDAY_PARTY_CLOSE" 2 "HOLIDAY_PARTY_DANCE" 1 "HOLIDAY_PARTY_OPEN" 0 "HOLIDAY_PARTY_IDLE" ;
VAL_ 1012 LS_windowRequestRR 4 "HOLIDAY_PARTY_STOP" 3 "HOLIDAY_PARTY_CLOSE" 2 "HOLIDAY_PARTY_DANCE" 1 "HOLIDAY_PARTY_OPEN" 0 "HOLIDAY_PARTY_IDLE" ;
VAL_ 1012 LS_presentingHandleRequestLF 4 "HOLIDAY_PARTY_STOP" 3 "HOLIDAY_PARTY_CLOSE" 2 "HOLIDAY_PARTY_DANCE" 1 "HOLIDAY_PARTY_OPEN" 0 "HOLIDAY_PARTY_IDLE" ;
VAL_ 1012 LS_presentingHandleRequestLR 4 "HOLIDAY_PARTY_STOP" 3 "HOLIDAY_PARTY_CLOSE" 2 "HOLIDAY_PARTY_DANCE" 1 "HOLIDAY_PARTY_OPEN" 0 "HOLIDAY_PARTY_IDLE" ;
VAL_ 1012 LS_presentingHandleRequestRF 4 "HOLIDAY_PARTY_STOP" 3 "HOLIDAY_PARTY_CLOSE" 2 "HOLIDAY_PARTY_DANCE" 1 "HOLIDAY_PARTY_OPEN" 0 "HOLIDAY_PARTY_IDLE" ;
VAL_ 1012 LS_presentingHandleRequestRR 4 "HOLIDAY_PARTY_STOP" 3 "HOLIDAY_PARTY_CLOSE" 2 "HOLIDAY_PARTY_DANCE" 1 "HOLIDAY_PARTY_OPEN" 0 "HOLIDAY_PARTY_IDLE" ;
VAL_ 1012 LS_powerFrontDoorRequestLeft 4 "HOLIDAY_PARTY_STOP" 3 "HOLIDAY_PARTY_CLOSE" 2 "HOLIDAY_PARTY_DANCE" 1 "HOLIDAY_PARTY_OPEN" 0 "HOLIDAY_PARTY_IDLE" ;
VAL_ 1012 LS_powerFrontDoorRequestRight 4 "HOLIDAY_PARTY_STOP" 3 "HOLIDAY_PARTY_CLOSE" 2 "HOLIDAY_PARTY_DANCE" 1 "HOLIDAY_PARTY_OPEN" 0 "HOLIDAY_PARTY_IDLE" ;
VAL_ 1012 LS_falconDoorRequestLeft 4 "HOLIDAY_PARTY_STOP" 3 "HOLIDAY_PARTY_CLOSE" 2 "HOLIDAY_PARTY_DANCE" 1 "HOLIDAY_PARTY_OPEN" 0 "HOLIDAY_PARTY_IDLE" ;
VAL_ 1012 LS_falconDoorRequestRight 4 "HOLIDAY_PARTY_STOP" 3 "HOLIDAY_PARTY_CLOSE" 2 "HOLIDAY_PARTY_DANCE" 1 "HOLIDAY_PARTY_OPEN" 0 "HOLIDAY_PARTY_IDLE" ;
VAL_ 1012 LS_chargePortRequest 3 "REQUEST_SNA" 2 "REQUEST_CLOSE" 1 "REQUEST_OPEN" 0 "REQUEST_NONE" ;
VAL_ 1012 LS_suspensionRequest 3 "SUSPENSION_REQUEST_SNA" 2 "SUSPENSION_REQUEST_LOWER" 1 "SUSPENSION_REQUEST_RAISE" 0 "SUSPENSION_REQUEST_NONE" ;
VAL_ 964 PCS_infoIndex 255 "END" 31 "SUBCOMPONENT_GITHASH" 30 "PACKAGE_SN_8_14" 29 "PACKAGE_SN_1_7" 27 "PACKAGE_PN_15_20" 26 "PACKAGE_PN_8_14" 25 "PACKAGE_PN_1_7" 23 "SUBCOMPONENT2" 22 "VARIANTCRC" 20 "UDS_PROTOCOL_BOOTCRC" 19 "VERSION_DEPRECATED" 18 "BOOTLOADER_GITHASH" 17 "APP_GITHASH" 16 "SUBCOMPONENT" 15 "BOOTLOADER_CRC" 14 "BOOTLOADER_SVN" 13 "APP_CRC" 11 "PCBAID_ASSYID_USAGEID" 10 "BUILD_HWID_COMPONENTID" 9 "DEPRECATED_9" 8 "DEPRECATED_8" 7 "DEPRECATED_7" 6 "DEPRECATED_6" 5 "DEPRECATED_5" 4 "DEPRECATED_4" 3 "DEPRECATED_3" 2 "DEPRECATED_2" 1 "DEPRECATED_1" 0 "DEPRECATED_0" ;
VAL_ 964 PCS_buildType 4 "INFO_MFG_BUILD" 3 "INFO_TRACEABLE_CI_BUILD" 2 "INFO_LOCAL_BUILD" 1 "INFO_PLATFORM_BUILD" 0 "INFO_UNKNOWN_BUILD" ;
VAL_ 676 PCS_chgPhATemp -1023 "SNA" ;
VAL_ 676 PCS_chgPhBTemp -1023 "SNA" ;
VAL_ 676 PCS_chgPhCTemp -1023 "SNA" ;
VAL_ 676 PCS_dcdcTemp -1023 "SNA" ;
VAL_ 676 PCS_ambientTemp -1023 "SNA" ;
VAL_ 676 PCS_dcdcBusbarTemp 511 "SNA" ;
VAL_ 790 PMF_infoIndex 255 "END" 21 "DI_BUILD_DATA" 20 "UDS_PROTOCOL_BOOTCRC" 19 "VERSION_DEPRECATED" 18 "BOOTLOADER_GITHASH" 17 "APP_GITHASH" 16 "SUBCOMPONENT" 15 "BOOTLOADER_CRC" 14 "BOOTLOADER_SVN" 13 "APP_CRC" 11 "PCBAID_ASSYID_USAGEID" 10 "BUILD_HWID_COMPONENTID" 9 "DEPRECATED_9" 8 "DEPRECATED_8" 7 "DEPRECATED_7" 6 "DEPRECATED_6" 5 "DEPRECATED_5" 4 "DEPRECATED_4" 3 "DEPRECATED_3" 2 "DEPRECATED_2" 1 "DEPRECATED_1" 0 "DEPRECATED_0" ;
VAL_ 790 PMF_buildType 4 "INFO_MFG_BUILD" 3 "INFO_TRACEABLE_CI_BUILD" 2 "INFO_LOCAL_BUILD" 1 "INFO_PLATFORM_BUILD" 0 "INFO_UNKNOWN_BUILD" ;
VAL_ 790 PMF_hardwareId 252 "CONFIGURABLE_HWID_PLACEHOLDER" ;
VAL_ 1748 PMR_infoIndex 255 "END" 21 "DI_BUILD_DATA" 20 "UDS_PROTOCOL_BOOTCRC" 19 "VERSION_DEPRECATED" 18 "BOOTLOADER_GITHASH" 17 "APP_GITHASH" 16 "SUBCOMPONENT" 15 "BOOTLOADER_CRC" 14 "BOOTLOADER_SVN" 13 "APP_CRC" 11 "PCBAID_ASSYID_USAGEID" 10 "BUILD_HWID_COMPONENTID" 9 "DEPRECATED_9" 8 "DEPRECATED_8" 7 "DEPRECATED_7" 6 "DEPRECATED_6" 5 "DEPRECATED_5" 4 "DEPRECATED_4" 3 "DEPRECATED_3" 2 "DEPRECATED_2" 1 "DEPRECATED_1" 0 "DEPRECATED_0" ;
VAL_ 1748 PMR_buildType 4 "INFO_MFG_BUILD" 3 "INFO_TRACEABLE_CI_BUILD" 2 "INFO_LOCAL_BUILD" 1 "INFO_PLATFORM_BUILD" 0 "INFO_UNKNOWN_BUILD" ;
VAL_ 1748 PMR_hardwareId 252 "CONFIGURABLE_HWID_PLACEHOLDER" ;
VAL_ 1551 PM_infoIndex 255 "END" 21 "DI_BUILD_DATA" 20 "UDS_PROTOCOL_BOOTCRC" 19 "VERSION_DEPRECATED" 18 "BOOTLOADER_GITHASH" 17 "APP_GITHASH" 16 "SUBCOMPONENT" 15 "BOOTLOADER_CRC" 14 "BOOTLOADER_SVN" 13 "APP_CRC" 11 "PCBAID_ASSYID_USAGEID" 10 "BUILD_HWID_COMPONENTID" 9 "DEPRECATED_9" 8 "DEPRECATED_8" 7 "DEPRECATED_7" 6 "DEPRECATED_6" 5 "DEPRECATED_5" 4 "DEPRECATED_4" 3 "DEPRECATED_3" 2 "DEPRECATED_2" 1 "DEPRECATED_1" 0 "DEPRECATED_0" ;
VAL_ 1551 PM_buildType 4 "INFO_MFG_BUILD" 3 "INFO_TRACEABLE_CI_BUILD" 2 "INFO_LOCAL_BUILD" 1 "INFO_PLATFORM_BUILD" 0 "INFO_UNKNOWN_BUILD" ;
VAL_ 1551 PM_hardwareId 252 "CONFIGURABLE_HWID_PLACEHOLDER" ;
VAL_ 837 PTC_infoIndex 255 "END" 31 "SUBCOMPONENT_GITHASH" 30 "PACKAGE_SN_8_14" 29 "PACKAGE_SN_1_7" 27 "PACKAGE_PN_15_20" 26 "PACKAGE_PN_8_14" 25 "PACKAGE_PN_1_7" 23 "SUBCOMPONENT2" 22 "VARIANTCRC" 20 "UDS_PROTOCOL_BOOTCRC" 19 "VERSION_DEPRECATED" 18 "BOOTLOADER_GITHASH" 17 "APP_GITHASH" 16 "SUBCOMPONENT" 15 "BOOTLOADER_CRC" 14 "BOOTLOADER_SVN" 13 "APP_CRC" 11 "PCBAID_ASSYID_USAGEID" 10 "BUILD_HWID_COMPONENTID" 9 "DEPRECATED_9" 8 "DEPRECATED_8" 7 "DEPRECATED_7" 6 "DEPRECATED_6" 5 "DEPRECATED_5" 4 "DEPRECATED_4" 3 "DEPRECATED_3" 2 "DEPRECATED_2" 1 "DEPRECATED_1" 0 "DEPRECATED_0" ;
VAL_ 837 PTC_infoBuildType 4 "INFO_MFG_BUILD" 3 "INFO_TRACEABLE_CI_BUILD" 2 "INFO_LOCAL_BUILD" 1 "INFO_PLATFORM_BUILD" 0 "INFO_UNKNOWN_BUILD" ;
VAL_ 837 PTC_infoAssemblyId 255 "ASSEMBLY_SNA" 1 "ASSEMBLY1" ;
VAL_ 816 SCCM_infoIndex 255 "END" 20 "UDS_PROTOCOL_BOOTCRC" 18 "BOOTLOADER_SVNHASH" 17 "APP_SVNHASH" 16 "SUBCOMPONENT1" 14 "BOOTLOADER_SVN" 13 "APP_CRC" 11 "PCBAID_ASSYID_USAGEID" 10 "BUILD_HWID_COMPONENTID" ;
VAL_ 816 SCCM_infoBuildType 4 "INFO_MFG_BUILD" 3 "INFO_TRACEABLE_CI_BUILD" 2 "INFO_LOCAL_BUILD" 1 "INFO_PLATFORM_BUILD" 0 "INFO_UNKNOWN_BUILD" ;
VAL_ 585 SCCM_highBeamStalkStatus 3 "SNA" 2 "PUSH" 1 "PULL" 0 "IDLE" ;
VAL_ 585 SCCM_washWipeButtonStatus 3 "SNA" 2 "2ND_DETENT" 1 "1ST_DETENT" 0 "NOT_PRESSED" ;
VAL_ 585 SCCM_turnIndicatorStalkStatus 9 "SNA" 8 "DOWN_2" 7 "DOWN_1_5" 6 "DOWN_1" 5 "DOWN_0_5" 4 "UP_2" 3 "UP_1_5" 2 "UP_1" 1 "UP_0_5" 0 "IDLE" ;
VAL_ 585 SCCM_turnIndicatorStalkAngle 4095 "SNA" ;
VAL_ 553 SCCM_rightStalkStatus 6 "SNA" 5 "INIT" 4 "DOWN_2" 3 "DOWN_1" 2 "UP_2" 1 "UP_1" 0 "IDLE" ;
VAL_ 553 SCCM_parkButtonStatus 3 "SNA" 2 "INIT" 1 "PRESSED" 0 "NOT_PRESSED" ;
VAL_ 297 SCCM_steeringAngleSensorStatus 3 "ERROR_INIT" 2 "ERROR" 1 "INIT" 0 "OK" ;
VAL_ 297 SCCM_steeringAngle 16383 "SNA" ;
VAL_ 297 SCCM_steeringAngleValidity 3 "SNA" 2 "INIT" 1 "VALID" 0 "INVALID" ;
VAL_ 1597 SDCR_infoIndex 255 "END" 41 "SUBCOMPONENT14" 40 "SUBCOMPONENT13" 39 "SUBCOMPONENT12" 38 "SUBCOMPONENT11" 37 "SUBCOMPONENT10" 36 "SUBCOMPONENT9" 35 "SUBCOMPONENT8" 34 "SUBCOMPONENT7" 33 "SUBCOMPONENT6" 32 "SUBCOMPONENT5" 31 "SUBCOMPONENT4" 24 "SUBCOMPONENT3" 23 "SUBCOMPONENT2" 20 "UDS_PROTOCOL_BOOTCRC" 19 "VERSION_DEPRECATED" 18 "BOOTLOADER_GITHASH" 17 "APP_GITHASH" 16 "SUBCOMPONENT1" 15 "BOOTLOADER_CRC" 14 "BOOTLOADER_SVN" 13 "APP_CRC" 11 "PCBAID_ASSYID_USAGEID" 10 "BUILD_HWID_COMPONENTID" 9 "DEPRECATED_9" 8 "DEPRECATED_8" 7 "DEPRECATED_7" 6 "DEPRECATED_6" 5 "DEPRECATED_5" 4 "DEPRECATED_4" 3 "DEPRECATED_3" 2 "DEPRECATED_2" 1 "DEPRECATED_1" 0 "DEPRECATED_0" ;
VAL_ 1597 SDCR_infoBuildType 4 "INFO_MFG_BUILD" 3 "INFO_TRACEABLE_CI_BUILD" 2 "INFO_LOCAL_BUILD" 1 "INFO_PLATFORM_BUILD" 0 "INFO_UNKNOWN_BUILD" ;
VAL_ 523 TAS_axleIndex 1 "axleRear" 0 "axleFront" ;
VAL_ 523 TAS_rawHeightFL 1023 "SNA" ;
VAL_ 523 TAS_staticHeightEstimateFL 1023 "SNA" ;
VAL_ 523 TAS_componentPressureFL 255 "SNA" ;
VAL_ 523 TAS_rawHeightFR 1023 "SNA" ;
VAL_ 523 TAS_staticHeightEstimateFR 1023 "SNA" ;
VAL_ 523 TAS_componentPressureFR 255 "SNA" ;
VAL_ 523 TAS_rawHeightRL 1023 "SNA" ;
VAL_ 523 TAS_staticHeightEstimateRL 1023 "SNA" ;
VAL_ 523 TAS_componentPressureRL 255 "SNA" ;
VAL_ 523 TAS_rawHeightRR 1023 "SNA" ;
VAL_ 523 TAS_staticHeightEstimateRR 1023 "SNA" ;
VAL_ 523 TAS_componentPressureRR 255 "SNA" ;
VAL_ 1398 TAS_endstopState 1 "TAS_DAMPING_STATE_ACTIVE" 0 "TAS_DAMPING_STATE_STANDBY" ;
VAL_ 1398 TAS_continuousControlState 1 "TAS_DAMPING_STATE_ACTIVE" 0 "TAS_DAMPING_STATE_STANDBY" ;
VAL_ 1398 TAS_activeTireTune 1 "TAS_TIRE_TUNE_MICHELIN_SUMMER_21" 0 "TAS_TIRE_TUNE_DEFAULT" ;
VAL_ 1398 TAS_roughnessRaiseReason 2 "TAS_ROUGHNESS_RAISE_REASON_LOOKAHEAD" 1 "TAS_ROUGHNESS_RAISE_REASON_LEGACY" 0 "TAS_ROUGHNESS_RAISE_REASON_NONE" ;
VAL_ 1398 TAS_frontMetricDrivesRear 3 "TAS_ACTION_ACTIVE" 2 "TAS_ACTION_ARMED" 1 "TAS_ACTION_STANDBY" 0 "TAS_ACTION_DISABLED" ;
VAL_ 1398 TAS_roadCondition 255 "SNA" ;
VAL_ 1398 TAS_bellyProtect 3 "TAS_ACTION_ACTIVE" 2 "TAS_ACTION_ARMED" 1 "TAS_ACTION_STANDBY" 0 "TAS_ACTION_DISABLED" ;
VAL_ 1398 TAS_frontMetricDrivesFront 3 "TAS_ACTION_ACTIVE" 2 "TAS_ACTION_ARMED" 1 "TAS_ACTION_STANDBY" 0 "TAS_ACTION_DISABLED" ;
VAL_ 1398 TAS_speedBumpAxleFront 4 "TAS_ACTION_CANCELED" 3 "TAS_ACTION_ACTIVE" 2 "TAS_ACTION_ARMED" 1 "TAS_ACTION_STANDBY" 0 "TAS_ACTION_DISABLED" ;
VAL_ 1398 TAS_speedBumpAxleRear 4 "TAS_ACTION_CANCELED" 3 "TAS_ACTION_ACTIVE" 2 "TAS_ACTION_ARMED" 1 "TAS_ACTION_STANDBY" 0 "TAS_ACTION_DISABLED" ;
VAL_ 1398 TAS_holeProtectFL 3 "TAS_ACTION_ACTIVE" 2 "TAS_ACTION_ARMED" 1 "TAS_ACTION_STANDBY" 0 "TAS_ACTION_DISABLED" ;
VAL_ 1398 TAS_holeProtectFR 3 "TAS_ACTION_ACTIVE" 2 "TAS_ACTION_ARMED" 1 "TAS_ACTION_STANDBY" 0 "TAS_ACTION_DISABLED" ;
VAL_ 1398 TAS_holeProtectRL 3 "TAS_ACTION_ACTIVE" 2 "TAS_ACTION_ARMED" 1 "TAS_ACTION_STANDBY" 0 "TAS_ACTION_DISABLED" ;
VAL_ 1398 TAS_holeProtectRR 3 "TAS_ACTION_ACTIVE" 2 "TAS_ACTION_ARMED" 1 "TAS_ACTION_STANDBY" 0 "TAS_ACTION_DISABLED" ;
VAL_ 1398 TAS_stepProtectFL 3 "TAS_ACTION_ACTIVE" 2 "TAS_ACTION_ARMED" 1 "TAS_ACTION_STANDBY" 0 "TAS_ACTION_DISABLED" ;
VAL_ 1398 TAS_stepProtectFR 3 "TAS_ACTION_ACTIVE" 2 "TAS_ACTION_ARMED" 1 "TAS_ACTION_STANDBY" 0 "TAS_ACTION_DISABLED" ;
VAL_ 1398 TAS_stepProtectRL 3 "TAS_ACTION_ACTIVE" 2 "TAS_ACTION_ARMED" 1 "TAS_ACTION_STANDBY" 0 "TAS_ACTION_DISABLED" ;
VAL_ 1398 TAS_stepProtectRR 3 "TAS_ACTION_ACTIVE" 2 "TAS_ACTION_ARMED" 1 "TAS_ACTION_STANDBY" 0 "TAS_ACTION_DISABLED" ;
VAL_ 1398 TAS_FDUTorqueCorruptionScale 15 "SNA" ;
VAL_ 1398 TAS_sprungMassEstimate 31 "SNA" ;
VAL_ 1357 TAS_infoIndex 255 "END" 41 "SUBCOMPONENT14" 40 "SUBCOMPONENT13" 39 "SUBCOMPONENT12" 38 "SUBCOMPONENT11" 37 "SUBCOMPONENT10" 36 "SUBCOMPONENT9" 35 "SUBCOMPONENT8" 34 "SUBCOMPONENT7" 33 "SUBCOMPONENT6" 32 "SUBCOMPONENT5" 31 "SUBCOMPONENT4" 24 "SUBCOMPONENT3" 23 "SUBCOMPONENT2" 20 "UDS_PROTOCOL_BOOTCRC" 19 "VERSION_DEPRECATED" 18 "BOOTLOADER_GITHASH" 17 "APP_GITHASH" 16 "SUBCOMPONENT1" 15 "BOOTLOADER_CRC" 14 "BOOTLOADER_SVN" 13 "APP_CRC" 11 "PCBAID_ASSYID_USAGEID" 10 "BUILD_HWID_COMPONENTID" 9 "DEPRECATED_9" 8 "DEPRECATED_8" 7 "DEPRECATED_7" 6 "DEPRECATED_6" 5 "DEPRECATED_5" 4 "DEPRECATED_4" 3 "DEPRECATED_3" 2 "DEPRECATED_2" 1 "DEPRECATED_1" 0 "DEPRECATED_0" ;
VAL_ 1357 TAS_infoBuildType 4 "INFO_MFG_BUILD" 3 "INFO_TRACEABLE_CI_BUILD" 2 "INFO_LOCAL_BUILD" 1 "INFO_PLATFORM_BUILD" 0 "INFO_UNKNOWN_BUILD" ;
VAL_ 1357 TAS_infoAssemblyId 255 "ASSEMBLY_SNA" 1 "ASSEMBLY1" ;
VAL_ 1357 TAS_infoMajorVersion 255 "SNA" 254 "LOCAL_BUILD" ;
VAL_ 1357 TAS_infoBranchOrigin 255 "SNA" 254 "LOCAL_BUILD" ;
VAL_ 1357 TAS_infoMaturity 255 "SNA" 254 "LOCAL_BUILD" ;
VAL_ 1357 TAS_infoHardwareRevision 255 "SNA" 254 "LOCAL_BUILD" ;
VAL_ 525 TAS_levelingState 15 "LEVELING_STATE_CROSSLINK" 14 "LEVELING_STATE_QUIET_EXHAUST" 13 "LEVELING_STATE_EXHAUST_RESERVOIR" 12 "LEVELING_STATE_LOWER_SPRING_WITH_COMPRESSOR" 11 "LEVELING_STATE_LOWER_SPRING" 10 "LEVELING_STATE_FILL_SPRING_RESERVOIR_FROM_COMPRESSOR" 9 "LEVELING_STATE_FILL_SPRING_FROM_RESERVOIR" 8 "LEVELING_STATE_FILL_SPRING_FROM_BOOST" 7 "LEVELING_STATE_FILL_SPRING_FROM_COMPRESSOR" 6 "LEVELING_STATE_FILL_RESERVOIR_FROM_COMPRESSOR" 5 "LEVELING_STATE_COMPRESSOR_PREFILL_GALLERY" 4 "LEVELING_STATE_COMPRESSOR_RAMPUP" 3 "LEVELING_STATE_EXHAUST_GALLERY" 2 "LEVELING_STATE_MEASURE_SPRING_PRESSURE" 1 "LEVELING_STATE_READ_P_RESERVOIR" 0 "LEVELING_STATE_IDLE" ;
VAL_ 525 TAS_levelingItem 7 "TAS_LEVELING_ITEM_ALL" 6 "TAS_LEVELING_ITEM_REAR_AXLE" 5 "TAS_LEVELING_ITEM_FRONT_AXLE" 4 "TAS_LEVELING_ITEM_RR" 3 "TAS_LEVELING_ITEM_RL" 2 "TAS_LEVELING_ITEM_FR" 1 "TAS_LEVELING_ITEM_FL" 0 "TAS_LEVELING_ITEM_NONE" ;
VAL_ 525 TAS_pressureGallery 255 "SNA" ;
VAL_ 525 TAS_pressureReservoir 255 "SNA" ;
VAL_ 525 TAS_runMode 7 "RUN_MODE_DYNO" 6 "RUN_MODE_LOW_POWER" 5 "RUN_MODE_NORMAL" 4 "RUN_MODE_DAN" 3 "RUN_MODE_ASSEMBLY" 2 "RUN_MODE_SERVICE" 1 "RUN_MODE_SYSTEM_CHECK" 0 "RUN_MODE_INIT" ;
VAL_ 525 TAS_filterMode 7 "MODE_STOPPING" 6 "MODE_DRIVE" 5 "MODE_LOADING" 4 "MODE_READY" 3 "MODE_TEST" 2 "MODE_CALIBRATE" 1 "MODE_INIT" 0 "MODE_NONE" ;
VAL_ 525 TAS_limpHomeMode 4 "LIMP_HOME_MODE_40" 3 "LIMP_HOME_MODE_30" 2 "LIMP_HOME_MODE_20" 1 "LIMP_HOME_MODE_10" 0 "LIMP_HOME_MODE_0" ;
VAL_ 525 TAS_targetLevel 4 "TAS_VERY_LOW" 3 "TAS_LOW" 2 "TAS_STANDARD" 1 "TAS_HIGH" 0 "TAS_VERY_HIGH" ;
VAL_ 525 TAS_currentLevel 4 "TAS_VERY_LOW" 3 "TAS_LOW" 2 "TAS_STANDARD" 1 "TAS_HIGH" 0 "TAS_VERY_HIGH" ;
VAL_ 409 TAS_adaptiveActivityFL_C 31 "SNA" ;
VAL_ 409 TAS_adaptiveActivityFL_R 31 "SNA" ;
VAL_ 409 TAS_adaptiveActivityFR_C 31 "SNA" ;
VAL_ 409 TAS_adaptiveActivityFR_R 31 "SNA" ;
VAL_ 409 TAS_adaptiveActivityRL_C 31 "SNA" ;
VAL_ 409 TAS_adaptiveActivityRL_R 31 "SNA" ;
VAL_ 409 TAS_adaptiveActivityRR_C 31 "SNA" ;
VAL_ 409 TAS_adaptiveActivityRR_R 31 "SNA" ;
VAL_ 409 TAS_uiHeightFL 63 "SNA" ;
VAL_ 409 TAS_uiHeightFR 63 "SNA" ;
VAL_ 409 TAS_uiHeightRL 63 "SNA" ;
VAL_ 409 TAS_uiHeightRR 63 "SNA" ;
VAL_ 410 TAS_bodyAccelFL 255 "SNA" ;
VAL_ 410 TAS_bodyAccelFR 255 "SNA" ;
VAL_ 410 TAS_bodyAccelRL 255 "SNA" ;
VAL_ 410 TAS_bodyAccelRR 255 "SNA" ;
VAL_ 538 TAS_adaptiveRideModeOverride 3 "TAS_ADAPTIVE_RIDE_MODE_SNA" 2 "TAS_ADAPTIVE_RIDE_MODE_SPORT" 1 "TAS_ADAPTIVE_RIDE_MODE_AUTO" 0 "TAS_ADAPTIVE_RIDE_MODE_COMFORT" ;
VAL_ 538 TAS_launchModeState 4 "TAS_LAUNCH_MODE_STATE_RAISE_SUSPENSION" 3 "TAS_LAUNCH_MODE_STATE_READY" 2 "TAS_LAUNCH_MODE_STATE_LOWER_SUSPENSION" 1 "TAS_LAUNCH_MODE_STATE_IDLE" 0 "TAS_LAUNCH_MODE_STATE_BLOCKED" ;
VAL_ 659 UI_steeringTuneRequest 2 "STEERING_TUNE_SPORT" 1 "STEERING_TUNE_STANDARD" 0 "STEERING_TUNE_COMFORT" ;
VAL_ 659 UI_tractionControlMode 7 "TC_SLIPPERY_SURFACE_SELECTED" 6 "TC_OFFROAD_ASSIST_SELECTED" 5 "TC_DYNO_MODE_SELECTED" 4 "TC_ROLLS_MODE_SELECTED" 3 "TC_DEV_MODE_2_SELECTED" 2 "TC_DEV_MODE_1_SELECTED" 1 "TC_SLIP_START_SELECTED" 0 "TC_NORMAL_SELECTED" ;
VAL_ 659 UI_parkBrakeRequest 3 "PARK_BRAKE_REQUEST_SNA" 1 "PARK_BRAKE_REQUEST_PRESSED" 0 "PARK_BRAKE_REQUEST_IDLE" ;
VAL_ 659 UI_winchModeRequest 3 "WINCH_MODE_DIALOGUE_OPEN" 2 "WINCH_MODE_EXIT" 1 "WINCH_MODE_ENTER" 0 "WINCH_MODE_IDLE" ;
VAL_ 659 UI_trailerMode 1 "TRAILER_MODE_ON" 0 "TRAILER_MODE_OFF" ;
VAL_ 659 UI_accOvertakeEnable 3 "SNA" 1 "ACC_OVERTAKE_ON" 0 "ACC_OVERTAKE_OFF" ;
VAL_ 659 UI_aebEnable 3 "SNA" 1 "AEB_ON" 0 "AEB_OFF" ;
VAL_ 659 UI_aesEnable 3 "SNA" 1 "AES_ON" 0 "AES_OFF" ;
VAL_ 659 UI_ahlbEnable 3 "SNA" 1 "AHLB_ON" 0 "AHLB_OFF" ;
VAL_ 659 UI_autoLaneChangeEnable 3 "SNA" 1 "ON" 0 "OFF" ;
VAL_ 659 UI_autoParkRequest 15 "SNA" 12 "BEGIN_PARKING" 11 "RESUME" 10 "PAUSE" 9 "SEARCH" 8 "COMPLETE" 7 "ABORT" 6 "PARALLEL_PULL_OUT_TO_RIGHT" 5 "PARALLEL_PULL_OUT_TO_LEFT" 4 "PARK_RIGHT_CROSS" 3 "PARK_RIGHT_PARALLEL" 2 "PARK_LEFT_CROSS" 1 "PARK_LEFT_PARALLEL" 0 "NONE" ;
VAL_ 659 UI_bsdEnable 3 "SNA" 1 "BSD_ON" 0 "BSD_OFF" ;
VAL_ 659 UI_fcwEnable 3 "SNA" 1 "FCW_ON" 0 "FCW_OFF" ;
VAL_ 659 UI_fcwSensitivity 3 "SNA" 2 "AEB_SENSITIVITY_LATE" 1 "AEB_SENSITIVITY_AVERAGE" 0 "AEB_SENSITIVITY_EARLY" ;
VAL_ 659 UI_latControlEnable 3 "LATERAL_CONTROL_SNA" 2 "LATERAL_CONTROL_UNAVAILABLE" 1 "LATERAL_CONTROL_ON" 0 "LATERAL_CONTROL_OFF" ;
VAL_ 659 UI_ldwEnable 3 "SNA" 1 "LDW_TRIGGERS_HAPTIC" 0 "NO_HAPTIC" ;
VAL_ 568 UI_roadClass 6 "CLASS_6_MINOR" 5 "CLASS_5" 4 "CLASS_4" 3 "CLASS_3" 2 "CLASS_2" 1 "CLASS_1_MAJOR" 0 "UNKNOWN_INVALID_SNA" ;
VAL_ 651 UI_driverProfileSelectionType 3 "DRIVER_PROFILE_SELECTION_TYPE_NONE" 2 "DRIVER_PROFILE_SELECTION_TYPE_AUTOMATIC_NO_OP" 1 "DRIVER_PROFILE_SELECTION_TYPE_AUTOMATIC_RESTORE" 0 "DRIVER_PROFILE_SELECTION_TYPE_MANUAL" ;
VAL_ 883 UI_mapSpeedLimitUnits 1 "KPH" 0 "MPH" ;
VAL_ 883 UI_conditionalSpeedLimit 31 "SNA" ;
VAL_ 755 UI_hvacReqTempSetpointLeft 26 "HI" 0 "LO" ;
VAL_ 755 UI_hvacReqAutoBlowerLevel 4 "VERY_HIGH" 3 "HIGH" 2 "MEDIUM" 1 "LOW" 0 "VERY_LOW" ;
VAL_ 755 UI_hvacReqTempSetpointRight 26 "HI" 0 "LO" ;
VAL_ 755 UI_hvacReqAirDistributionMode 7 "MANUAL_DEFROST_PANEL_FLOOR" 6 "MANUAL_DEFROST_PANEL" 5 "MANUAL_DEFROST_FLOOR" 4 "MANUAL_DEFROST" 3 "MANUAL_PANEL_FLOOR" 2 "MANUAL_PANEL" 1 "MANUAL_FLOOR" 0 "AUTO" ;
VAL_ 755 UI_hvacReqBlowerSegment 11 "AUTO" 10 "10" 9 "9" 8 "8" 7 "7" 6 "6" 5 "5" 4 "4" 3 "3" 2 "2" 1 "1" 0 "OFF" ;
VAL_ 755 UI_hvacReqRecirc 2 "FRESH" 1 "RECIRC" 0 "AUTO" ;
VAL_ 755 UI_hvacReqACDisable 2 "ON" 1 "OFF" 0 "AUTO" ;
VAL_ 755 UI_hvacDefogState 3 "AUTO_DEFOG" 2 "DEFROST" 1 "DEFOG" 0 "NONE" ;
VAL_ 755 UI_hvacReqUserPowerState 4 "OVERHEAT_PROTECT" 3 "OVERHEAT_PROTECT_FANONLY" 2 "PRECONDITION" 1 "ON" 0 "OFF" ;
VAL_ 755 UI_hvacReqSecondRowState 4 "HIGH" 3 "MED" 2 "LOW" 1 "OFF" 0 "AUTO" ;
VAL_ 755 UI_hvacReqKeepClimateOn 3 "KEEP_CLIMATE_ON_REQ_PARTY" 2 "KEEP_CLIMATE_ON_REQ_DOG" 1 "KEEP_CLIMATE_ON_REQ_ON" 0 "KEEP_CLIMATE_ON_REQ_OFF" ;
VAL_ 755 UI_hvacReqTempSetpointCOP 2 "HIGH" 1 "MEDIUM" 0 "LOW" ;
VAL_ 1523 UI_odometer 16777215 "SNA" ;
VAL_ 948 UI_usbFrontHubPowerStateRequest 2 "POWER_ON" 1 "POWER_NO_PREFERENCE" 0 "POWER_REQUEST_SNA" ;
VAL_ 827 UI_chargeTimeUntilTerminationPct 2047 "SNA" 1440 "MAXVAL" ;
VAL_ 827 UI_chargeTimeUntilReadyToDepart 2047 "SNA" 1440 "MAXVAL" ;
VAL_ 723 UI_isSunUp 3 "SUN_SNA" 1 "SUN_UP" 0 "SUN_DOWN" ;
VAL_ 723 UI_solarElevationAngle 127 "SNA" ;
VAL_ 851 UI_factoryReset 3 "CUSTOMER" 2 "DIAGNOSTIC" 1 "DEVELOPER" 0 "NONE_SNA" ;
VAL_ 851 UI_cellNetworkTechnology 15 "CELL_NETWORK_SNA" 14 "CELL_NETWORK_NGRAN" 13 "CELL_NETWORK_5GSA" 12 "CELL_NETWORK_5GNSA" 11 "CELL_NETWORK_LTE5GCN" 10 "CELL_NETWORK_WCDMA" 9 "CELL_NETWORK_CDMA" 8 "CELL_NETWORK_GSM" 7 "CELL_NETWORK_LTE" 6 "CELL_NETWORK_HSPA" 5 "CELL_NETWORK_HSUPA" 4 "CELL_NETWORK_HSDPA" 3 "CELL_NETWORK_UMTS" 2 "CELL_NETWORK_EDGE" 1 "CELL_NETWORK_GPRS" 0 "CELL_NETWORK_NONE" ;
VAL_ 851 UI_cellSignalBars 7 "SNA" 5 "FIVE" 4 "FOUR" 3 "THREE" 2 "TWO" 1 "ONE" 0 "ZERO" ;
VAL_ 851 UI_trailerModeTelltale 3 "TRAILER_MODE_TELLTALE_RED" 2 "TRAILER_MODE_TELLTALE_YELLOW" 1 "TRAILER_MODE_TELLTALE_BLUE" 0 "TRAILER_MODE_TELLTALE_OFF" ;
VAL_ 663 UI_adaptiveRideRequest 3 "ADAPTIVE_RIDE_REQUEST_ADVANCED" 2 "ADAPTIVE_RIDE_REQUEST_SPORT" 1 "ADAPTIVE_RIDE_REQUEST_AUTO" 0 "ADAPTIVE_RIDE_REQUEST_COMFORT" ;
VAL_ 663 UI_geofenceLevelingRequest 5 "GEOFENCE_LEVELING_REQUEST_SNA" 4 "GEOFENCE_LEVELING_REQUEST_VERY_HIGH_PERSIST" 3 "GEOFENCE_LEVELING_REQUEST_HIGH_PERSIST" 2 "GEOFENCE_LEVELING_REQUEST_VERY_HIGH_TEMPORARY" 1 "GEOFENCE_LEVELING_REQUEST_HIGH_TEMPORARY" 0 "GEOFENCE_LEVELING_REQUEST_NONE" ;
VAL_ 627 UI_powerStateRequest 3 "DRIVE_SUMMON" 2 "ACCESSORY_PLUS" 1 "ACCESSORY" 0 "IDLE" ;
VAL_ 627 UI_wiperMode 3 "WIPER_MODE_PARK" 2 "WIPER_MODE_NORMAL" 1 "WIPER_MODE_SERVICE" 0 "WIPER_MODE_SNA" ;
VAL_ 627 UI_steeringButtonMode 7 "STEERING_BUTTON_MODE_SEATS" 6 "STEERING_BUTTON_MODE_WIPERS" 5 "STEERING_BUTTON_MODE_HEADLIGHT_RIGHT" 4 "STEERING_BUTTON_MODE_HEADLIGHT_LEFT" 3 "STEERING_BUTTON_MODE_MIRROR_RIGHT" 2 "STEERING_BUTTON_MODE_MIRROR_LEFT" 1 "STEERING_BUTTON_MODE_STEERING_COLUMN_ADJ" 0 "STEERING_BUTTON_MODE_OFF" ;
VAL_ 627 UI_lockRequest 7 "UI_LOCK_REQUEST_SNA" 4 "UI_LOCK_REQUEST_REMOTE_LOCK" 3 "UI_LOCK_REQUEST_REMOTE_UNLOCK" 2 "UI_LOCK_REQUEST_UNLOCK" 1 "UI_LOCK_REQUEST_LOCK" 0 "UI_LOCK_REQUEST_IDLE" ;
VAL_ 627 UI_mirrorFoldRequest 3 "MIRROR_FOLD_REQUEST_SNA" 2 "MIRROR_FOLD_REQUEST_PRESENT" 1 "MIRROR_FOLD_REQUEST_RETRACT" 0 "MIRROR_FOLD_REQUEST_IDLE" ;
VAL_ 627 UI_remoteStartRequest 4 "UI_REMOTE_START_REQUEST_SNA" 1 "UI_REMOTE_START_REQUEST_START" 0 "UI_REMOTE_START_REQUEST_IDLE" ;
VAL_ 627 UI_displayBrightnessLevel 255 "SNA" ;
VAL_ 627 UI_frontLeftSeatHeatReq 3 "HEATER_REQUEST_LEVEL3" 2 "HEATER_REQUEST_LEVEL2" 1 "HEATER_REQUEST_LEVEL1" 0 "HEATER_REQUEST_OFF" ;
VAL_ 627 UI_frontRightSeatHeatReq 3 "HEATER_REQUEST_LEVEL3" 2 "HEATER_REQUEST_LEVEL2" 1 "HEATER_REQUEST_LEVEL1" 0 "HEATER_REQUEST_OFF" ;
VAL_ 627 UI_rearLeftSeatHeatReq 3 "HEATER_REQUEST_LEVEL3" 2 "HEATER_REQUEST_LEVEL2" 1 "HEATER_REQUEST_LEVEL1" 0 "HEATER_REQUEST_OFF" ;
VAL_ 627 UI_rearCenterSeatHeatReq 3 "HEATER_REQUEST_LEVEL3" 2 "HEATER_REQUEST_LEVEL2" 1 "HEATER_REQUEST_LEVEL1" 0 "HEATER_REQUEST_OFF" ;
VAL_ 627 UI_rearRightSeatHeatReq 3 "HEATER_REQUEST_LEVEL3" 2 "HEATER_REQUEST_LEVEL2" 1 "HEATER_REQUEST_LEVEL1" 0 "HEATER_REQUEST_OFF" ;
VAL_ 627 UI_remoteClosureRequest 3 "UI_REMOTE_CLOSURE_REQUEST_SNA" 2 "UI_REMOTE_CLOSURE_REQUEST_FRONT_TRUNK_MOVE" 1 "UI_REMOTE_CLOSURE_REQUEST_REAR_TRUNK_MOVE" 0 "UI_REMOTE_CLOSURE_REQUEST_IDLE" ;
VAL_ 627 UI_wiperRequest 6 "WIPER_REQUEST_FAST_CONTINUOUS" 5 "WIPER_REQUEST_SLOW_CONTINUOUS" 4 "WIPER_REQUEST_FAST_INTERMITTENT" 3 "WIPER_REQUEST_SLOW_INTERMITTENT" 2 "WIPER_REQUEST_AUTO" 1 "WIPER_REQUEST_OFF" 0 "WIPER_REQUEST_SNA" ;
VAL_ 627 UI_domeLightSwitch 2 "DOME_LIGHT_SWITCH_AUTO" 1 "DOME_LIGHT_SWITCH_ON" 0 "DOME_LIGHT_SWITCH_OFF" ;
VAL_ 1285 SA_infoIndex 32 "Mux32" 31 "Mux31" 30 "Mux30" 29 "Mux29" 27 "Mux27" 26 "Mux26" 25 "Mux25" 11 "Mux11" 0 "Mux0" ;
VAL_ 1285 SA_region 6 "SA_REGION_INDIA" 5 "SA_REGION_SOUTH_KOREA" 4 "SA_REGION_AUSTRALIA" 3 "SA_REGION_JAPAN" 2 "SA_REGION_CHINA" 1 "SA_REGION_EU" 0 "SA_REGION_NA" ;
